VERSION "dbc-export 1 2025.20.8"

NS_ :

BS_:

BU_: BMS CC CMP CMPD CP DAS DI DIF DIR EPBL EPBR EVSE FC GTW HCML HCMR HVP ICR PCS PM PMF PMR PTC SCCM SCM SCS SDCR TAS UMC VC VCFRONT VCLEFT VCRIGHT VCSEC

BO_ 1012 LS_lightShow: 8 GTW
 SG_ LS_lightShowIndex M : 0|5@1+ (1,0) [0|31] "" Vector__XXX
 SG_ LS_lightLeftRampedChannel1Reques m0 : 5|1@1+ (1,0) [0|1] "" Vector__XXX
 SG_ LS_lightLeftRampedChannel1Durati m0 : 6|2@1+ (1,0) [0|3] "" Vector__XXX
 SG_ LS_lightLeftRampedChannel2Reques m0 : 8|1@1+ (1,0) [0|1] "" Vector__XXX
 SG_ LS_lightLeftRampedChannel2Durati m0 : 9|2@1+ (1,0) [0|3] "" Vector__XXX
 SG_ LS_lightLeftRampedChannel3Reques m0 : 11|1@1+ (1,0) [0|1] "" Vector__XXX
 SG_ LS_lightLeftRampedChannel3Durati m0 : 12|2@1+ (1,0) [0|3] "" Vector__XXX
 SG_ LS_lightLeftRampedChannel4Reques m0 : 14|1@1+ (1,0) [0|1] "" Vector__XXX
 SG_ LS_lightLeftRampedChannel4Durati m0 : 16|2@1+ (1,0) [0|3] "" Vector__XXX
 SG_ LS_lightLeftRampedChannel5Reques m0 : 18|1@1+ (1,0) [0|1] "" Vector__XXX
 SG_ LS_lightLeftRampedChannel5Durati m0 : 19|2@1+ (1,0) [0|3] "" Vector__XXX
 SG_ LS_lightLeftRampedChannel6Reques m0 : 21|1@1+ (1,0) [0|1] "" Vector__XXX
 SG_ LS_lightLeftRampedChannel6Durati m0 : 22|2@1+ (1,0) [0|3] "" Vector__XXX
 SG_ LS_lightLeftRampedChannel7Reques m0 : 24|1@1+ (1,0) [0|1] "" Vector__XXX
 SG_ LS_lightLeftRampedChannel7Durati m0 : 25|2@1+ (1,0) [0|3] "" Vector__XXX
 SG_ LS_lightRightRampedChannel1Reque m0 : 27|1@1+ (1,0) [0|1] "" Vector__XXX
 SG_ LS_lightRightRampedChannel1Durat m0 : 28|2@1+ (1,0) [0|3] "" Vector__XXX
 SG_ LS_lightRightRampedChannel2Reque m0 : 30|1@1+ (1,0) [0|1] "" Vector__XXX
 SG_ LS_lightRightRampedChannel2Durat m0 : 31|2@1+ (1,0) [0|3] "" Vector__XXX
 SG_ LS_lightRightRampedChannel3Reque m0 : 33|1@1+ (1,0) [0|1] "" Vector__XXX
 SG_ LS_lightRightRampedChannel3Durat m0 : 34|2@1+ (1,0) [0|3] "" Vector__XXX
 SG_ LS_lightRightRampedChannel4Reque m0 : 36|1@1+ (1,0) [0|1] "" Vector__XXX
 SG_ LS_lightRightRampedChannel4Durat m0 : 37|2@1+ (1,0) [0|3] "" Vector__XXX
 SG_ LS_lightRightRampedChannel5Reque m0 : 39|1@1+ (1,0) [0|1] "" Vector__XXX
 SG_ LS_lightRightRampedChannel5Durat m0 : 40|2@1+ (1,0) [0|3] "" Vector__XXX
 SG_ LS_lightRightRampedChannel6Reque m0 : 42|1@1+ (1,0) [0|1] "" Vector__XXX
 SG_ LS_lightRightRampedChannel6Durat m0 : 43|2@1+ (1,0) [0|3] "" Vector__XXX
 SG_ LS_lightRightRampedChannel7Reque m0 : 45|1@1+ (1,0) [0|1] "" Vector__XXX
 SG_ LS_lightRightRampedChannel7Durat m0 : 46|2@1+ (1,0) [0|3] "" Vector__XXX
 SG_ LS_lightRearTurnLeftRequest m0 : 48|1@1+ (1,0) [0|1] "" Vector__XXX
 SG_ LS_lightRearTurnRightRequest m0 : 49|1@1+ (1,0) [0|1] "" Vector__XXX
 SG_ LS_lightSideRepeaterLeftRequest m0 : 50|1@1+ (1,0) [0|1] "" Vector__XXX
 SG_ LS_lightSideRepeaterRightRequest m0 : 51|1@1+ (1,0) [0|1] "" Vector__XXX
 SG_ LS_lightSideMarkerLeftRequest m0 : 52|1@1+ (1,0) [0|1] "" Vector__XXX
 SG_ LS_lightSideMarkerRightRequest m0 : 53|1@1+ (1,0) [0|1] "" Vector__XXX
 SG_ LS_lightFrontFogLeftRequest m0 : 54|1@1+ (1,0) [0|1] "" Vector__XXX
 SG_ LS_lightFrontFogRightRequest m0 : 55|1@1+ (1,0) [0|1] "" Vector__XXX
 SG_ LS_lightRearFogRequest m0 : 56|1@1+ (1,0) [0|1] "" Vector__XXX
 SG_ LS_lightBrakeRequest m0 : 57|1@1+ (1,0) [0|1] "" Vector__XXX
 SG_ LS_lightTailLeftRequest m0 : 58|1@1+ (1,0) [0|1] "" Vector__XXX
 SG_ LS_lightTailRightRequest m0 : 59|1@1+ (1,0) [0|1] "" Vector__XXX
 SG_ LS_lightLicensePlateRequest m0 : 60|1@1+ (1,0) [0|1] "" Vector__XXX
 SG_ LS_lightReverseRequest m0 : 61|1@1+ (1,0) [0|1] "" Vector__XXX
 SG_ LS_lightAuxParkLeftRequest m0 : 62|1@1+ (1,0) [0|1] "" Vector__XXX
 SG_ LS_lightAuxParkRightRequest m0 : 63|1@1+ (1,0) [0|1] "" Vector__XXX
 SG_ LS_mirrorRequestLeft m1 : 5|3@1+ (1,0) [0|7] "" Vector__XXX
 SG_ LS_mirrorRequestRight m1 : 8|3@1+ (1,0) [0|7] "" Vector__XXX
 SG_ LS_liftgateRequest m1 : 11|3@1+ (1,0) [0|7] "" Vector__XXX
 SG_ LS_windowRequestLF m1 : 16|3@1+ (1,0) [0|7] "" Vector__XXX
 SG_ LS_windowRequestLR m1 : 19|3@1+ (1,0) [0|7] "" Vector__XXX
 SG_ LS_windowRequestRF m1 : 24|3@1+ (1,0) [0|7] "" Vector__XXX
 SG_ LS_windowRequestRR m1 : 27|3@1+ (1,0) [0|7] "" Vector__XXX
 SG_ LS_presentingHandleRequestLF m1 : 32|3@1+ (1,0) [0|7] "" Vector__XXX
 SG_ LS_presentingHandleRequestLR m1 : 35|3@1+ (1,0) [0|7] "" Vector__XXX
 SG_ LS_presentingHandleRequestRF m1 : 40|3@1+ (1,0) [0|7] "" Vector__XXX
 SG_ LS_presentingHandleRequestRR m1 : 43|3@1+ (1,0) [0|7] "" Vector__XXX
 SG_ LS_powerFrontDoorRequestLeft m1 : 46|3@1+ (1,0) [0|7] "" Vector__XXX
 SG_ LS_powerFrontDoorRequestRight m1 : 49|3@1+ (1,0) [0|7] "" Vector__XXX
 SG_ LS_falconDoorRequestLeft m1 : 52|3@1+ (1,0) [0|7] "" Vector__XXX
 SG_ LS_falconDoorRequestRight m1 : 55|3@1+ (1,0) [0|7] "" Vector__XXX
 SG_ LS_chargePortRequest m1 : 58|2@1+ (1,0) [0|2] "" Vector__XXX
 SG_ LS_chargePortRaveRequest m1 : 60|1@1+ (1,0) [0|1] "" Vector__XXX
 SG_ LS_suspensionRequest m1 : 61|2@1+ (1,0) [0|2] "" Vector__XXX
 SG_ LS_rgbIPFLRed m2 : 8|8@1+ (1,0) [0|255] "" Vector__XXX
 SG_ LS_rgbIPFLGreen m2 : 16|8@1+ (1,0) [0|255] "" Vector__XXX
 SG_ LS_rgbIPFLBlue m2 : 24|8@1+ (1,0) [0|255] "" Vector__XXX
 SG_ LS_rgbIPFRRed m2 : 32|8@1+ (1,0) [0|255] "" Vector__XXX
 SG_ LS_rgbIPFRGreen m2 : 40|8@1+ (1,0) [0|255] "" Vector__XXX
 SG_ LS_rgbIPFRBlue m2 : 48|8@1+ (1,0) [0|255] "" Vector__XXX
 SG_ LS_rgbDoorFLForeRed m3 : 8|8@1+ (1,0) [0|255] "" Vector__XXX
 SG_ LS_rgbDoorFLForeGreen m3 : 16|8@1+ (1,0) [0|255] "" Vector__XXX
 SG_ LS_rgbDoorFLForeBlue m3 : 24|8@1+ (1,0) [0|255] "" Vector__XXX
 SG_ LS_rgbDoorFLAftRed m3 : 32|8@1+ (1,0) [0|255] "" Vector__XXX
 SG_ LS_rgbDoorFLAftGreen m3 : 40|8@1+ (1,0) [0|255] "" Vector__XXX
 SG_ LS_rgbDoorFLAftBlue m3 : 48|8@1+ (1,0) [0|255] "" Vector__XXX
 SG_ LS_rgbDoorFRForeRed m4 : 8|8@1+ (1,0) [0|255] "" Vector__XXX
 SG_ LS_rgbDoorFRForeGreen m4 : 16|8@1+ (1,0) [0|255] "" Vector__XXX
 SG_ LS_rgbDoorFRForeBlue m4 : 24|8@1+ (1,0) [0|255] "" Vector__XXX
 SG_ LS_rgbDoorFRAftRed m4 : 32|8@1+ (1,0) [0|255] "" Vector__XXX
 SG_ LS_rgbDoorFRAftGreen m4 : 40|8@1+ (1,0) [0|255] "" Vector__XXX
 SG_ LS_rgbDoorFRAftBlue m4 : 48|8@1+ (1,0) [0|255] "" Vector__XXX
 SG_ LS_rgbDoorRLForeRed m5 : 8|8@1+ (1,0) [0|255] "" Vector__XXX
 SG_ LS_rgbDoorRLForeGreen m5 : 16|8@1+ (1,0) [0|255] "" Vector__XXX
 SG_ LS_rgbDoorRLForeBlue m5 : 24|8@1+ (1,0) [0|255] "" Vector__XXX
 SG_ LS_rgbDoorRLAftRed m5 : 32|8@1+ (1,0) [0|255] "" Vector__XXX
 SG_ LS_rgbDoorRLAftGreen m5 : 40|8@1+ (1,0) [0|255] "" Vector__XXX
 SG_ LS_rgbDoorRLAftBlue m5 : 48|8@1+ (1,0) [0|255] "" Vector__XXX
 SG_ LS_rgbDoorRRForeRed m6 : 8|8@1+ (1,0) [0|255] "" Vector__XXX
 SG_ LS_rgbDoorRRForeGreen m6 : 16|8@1+ (1,0) [0|255] "" Vector__XXX
 SG_ LS_rgbDoorRRForeBlue m6 : 24|8@1+ (1,0) [0|255] "" Vector__XXX
 SG_ LS_rgbDoorRRAftRed m6 : 32|8@1+ (1,0) [0|255] "" Vector__XXX
 SG_ LS_rgbDoorRRAftGreen m6 : 40|8@1+ (1,0) [0|255] "" Vector__XXX
 SG_ LS_rgbDoorRRAftBlue m6 : 48|8@1+ (1,0) [0|255] "" Vector__XXX
 SG_ LS_frontMatrix0 m7 : 8|8@1+ (1,0) [0|255] "" Vector__XXX
 SG_ LS_frontMatrix1 m7 : 16|8@1+ (1,0) [0|255] "" Vector__XXX
 SG_ LS_frontMatrix2 m7 : 24|8@1+ (1,0) [0|255] "" Vector__XXX
 SG_ LS_frontMatrix3 m7 : 32|8@1+ (1,0) [0|255] "" Vector__XXX
 SG_ LS_frontMatrix4 m7 : 40|8@1+ (1,0) [0|255] "" Vector__XXX
 SG_ LS_frontMatrix5 m7 : 48|8@1+ (1,0) [0|255] "" Vector__XXX
 SG_ LS_frontMatrix6 m7 : 56|8@1+ (1,0) [0|255] "" Vector__XXX
 SG_ LS_frontMatrix7 m8 : 8|8@1+ (1,0) [0|255] "" Vector__XXX
 SG_ LS_frontMatrix8 m8 : 16|8@1+ (1,0) [0|255] "" Vector__XXX
 SG_ LS_frontMatrix9 m8 : 24|8@1+ (1,0) [0|255] "" Vector__XXX
 SG_ LS_frontMatrix10 m8 : 32|8@1+ (1,0) [0|255] "" Vector__XXX
 SG_ LS_frontMatrix11 m8 : 40|8@1+ (1,0) [0|255] "" Vector__XXX
 SG_ LS_frontMatrix12 m8 : 48|8@1+ (1,0) [0|255] "" Vector__XXX
 SG_ LS_frontMatrix13 m8 : 56|8@1+ (1,0) [0|255] "" Vector__XXX
 SG_ LS_frontMatrix14 m9 : 8|8@1+ (1,0) [0|255] "" Vector__XXX
 SG_ LS_frontMatrix15 m9 : 16|8@1+ (1,0) [0|255] "" Vector__XXX
 SG_ LS_frontMatrix16 m9 : 24|8@1+ (1,0) [0|255] "" Vector__XXX
 SG_ LS_frontMatrix17 m9 : 32|8@1+ (1,0) [0|255] "" Vector__XXX
 SG_ LS_frontMatrix18 m9 : 40|8@1+ (1,0) [0|255] "" Vector__XXX
 SG_ LS_frontMatrix19 m9 : 48|8@1+ (1,0) [0|255] "" Vector__XXX
 SG_ LS_frontMatrix20 m9 : 56|8@1+ (1,0) [0|255] "" Vector__XXX
 SG_ LS_frontMatrix21 m10 : 8|8@1+ (1,0) [0|255] "" Vector__XXX
 SG_ LS_frontMatrix22 m10 : 16|8@1+ (1,0) [0|255] "" Vector__XXX
 SG_ LS_frontMatrix23 m10 : 24|8@1+ (1,0) [0|255] "" Vector__XXX
 SG_ LS_frontMatrix24 m10 : 32|8@1+ (1,0) [0|255] "" Vector__XXX
 SG_ LS_frontMatrix25 m10 : 40|8@1+ (1,0) [0|255] "" Vector__XXX
 SG_ LS_frontMatrix26 m10 : 48|8@1+ (1,0) [0|255] "" Vector__XXX
 SG_ LS_frontMatrix27 m10 : 56|8@1+ (1,0) [0|255] "" Vector__XXX
 SG_ LS_frontMatrix28 m11 : 8|8@1+ (1,0) [0|255] "" Vector__XXX
 SG_ LS_frontMatrix29 m11 : 16|8@1+ (1,0) [0|255] "" Vector__XXX
 SG_ LS_frontMatrix30 m11 : 24|8@1+ (1,0) [0|255] "" Vector__XXX
 SG_ LS_frontMatrix31 m11 : 32|8@1+ (1,0) [0|255] "" Vector__XXX
 SG_ LS_frontMatrix32 m11 : 40|8@1+ (1,0) [0|255] "" Vector__XXX
 SG_ LS_frontMatrix33 m11 : 48|8@1+ (1,0) [0|255] "" Vector__XXX
 SG_ LS_frontMatrix34 m11 : 56|8@1+ (1,0) [0|255] "" Vector__XXX
 SG_ LS_frontMatrix35 m12 : 8|8@1+ (1,0) [0|255] "" Vector__XXX
 SG_ LS_frontMatrix36 m12 : 16|8@1+ (1,0) [0|255] "" Vector__XXX
 SG_ LS_frontMatrix37 m12 : 24|8@1+ (1,0) [0|255] "" Vector__XXX
 SG_ LS_frontMatrix38 m12 : 32|8@1+ (1,0) [0|255] "" Vector__XXX
 SG_ LS_frontMatrix39 m12 : 40|8@1+ (1,0) [0|255] "" Vector__XXX
 SG_ LS_frontMatrix40 m12 : 48|8@1+ (1,0) [0|255] "" Vector__XXX
 SG_ LS_frontMatrix41 m12 : 56|8@1+ (1,0) [0|255] "" Vector__XXX
 SG_ LS_frontMatrix42 m13 : 8|8@1+ (1,0) [0|255] "" Vector__XXX
 SG_ LS_frontMatrix43 m13 : 16|8@1+ (1,0) [0|255] "" Vector__XXX
 SG_ LS_frontMatrix44 m13 : 24|8@1+ (1,0) [0|255] "" Vector__XXX
 SG_ LS_frontMatrix45 m13 : 32|8@1+ (1,0) [0|255] "" Vector__XXX
 SG_ LS_frontMatrix46 m13 : 40|8@1+ (1,0) [0|255] "" Vector__XXX
 SG_ LS_frontMatrix47 m13 : 48|8@1+ (1,0) [0|255] "" Vector__XXX
 SG_ LS_frontMatrix48 m13 : 56|8@1+ (1,0) [0|255] "" Vector__XXX
 SG_ LS_frontMatrix49 m14 : 8|8@1+ (1,0) [0|255] "" Vector__XXX
 SG_ LS_frontMatrix50 m14 : 16|8@1+ (1,0) [0|255] "" Vector__XXX
 SG_ LS_frontMatrix51 m14 : 24|8@1+ (1,0) [0|255] "" Vector__XXX
 SG_ LS_frontMatrix52 m14 : 32|8@1+ (1,0) [0|255] "" Vector__XXX
 SG_ LS_frontMatrix53 m14 : 40|8@1+ (1,0) [0|255] "" Vector__XXX
 SG_ LS_frontMatrix54 m14 : 48|8@1+ (1,0) [0|255] "" Vector__XXX
 SG_ LS_frontMatrix55 m14 : 56|8@1+ (1,0) [0|255] "" Vector__XXX
 SG_ LS_frontMatrix56 m15 : 8|8@1+ (1,0) [0|255] "" Vector__XXX
 SG_ LS_frontMatrix57 m15 : 16|8@1+ (1,0) [0|255] "" Vector__XXX
 SG_ LS_frontMatrix58 m15 : 24|8@1+ (1,0) [0|255] "" Vector__XXX
 SG_ LS_frontMatrix59 m15 : 32|8@1+ (1,0) [0|255] "" Vector__XXX
 SG_ LS_rearMatrix0 m15 : 40|8@1+ (1,0) [0|255] "" Vector__XXX
 SG_ LS_rearMatrix1 m15 : 48|8@1+ (1,0) [0|255] "" Vector__XXX
 SG_ LS_rearMatrix2 m15 : 56|8@1+ (1,0) [0|255] "" Vector__XXX
 SG_ LS_rearMatrix3 m16 : 8|8@1+ (1,0) [0|255] "" Vector__XXX
 SG_ LS_rearMatrix4 m16 : 16|8@1+ (1,0) [0|255] "" Vector__XXX
 SG_ LS_rearMatrix5 m16 : 24|8@1+ (1,0) [0|255] "" Vector__XXX
 SG_ LS_rearMatrix6 m16 : 32|8@1+ (1,0) [0|255] "" Vector__XXX
 SG_ LS_rearMatrix7 m16 : 40|8@1+ (1,0) [0|255] "" Vector__XXX
 SG_ LS_rearMatrix8 m16 : 48|8@1+ (1,0) [0|255] "" Vector__XXX
 SG_ LS_rearMatrix9 m16 : 56|8@1+ (1,0) [0|255] "" Vector__XXX
 SG_ LS_rearMatrix10 m17 : 8|8@1+ (1,0) [0|255] "" Vector__XXX
 SG_ LS_rearMatrix11 m17 : 16|8@1+ (1,0) [0|255] "" Vector__XXX
 SG_ LS_rearMatrix12 m17 : 24|8@1+ (1,0) [0|255] "" Vector__XXX
 SG_ LS_rearMatrix13 m17 : 32|8@1+ (1,0) [0|255] "" Vector__XXX
 SG_ LS_rearMatrix14 m17 : 40|8@1+ (1,0) [0|255] "" Vector__XXX
 SG_ LS_rearMatrix15 m17 : 48|8@1+ (1,0) [0|255] "" Vector__XXX
 SG_ LS_rearMatrix16 m17 : 56|8@1+ (1,0) [0|255] "" Vector__XXX
 SG_ LS_rearMatrix17 m18 : 8|8@1+ (1,0) [0|255] "" Vector__XXX
 SG_ LS_rearMatrix18 m18 : 16|8@1+ (1,0) [0|255] "" Vector__XXX
 SG_ LS_rearMatrix19 m18 : 24|8@1+ (1,0) [0|255] "" Vector__XXX
 SG_ LS_rearMatrix20 m18 : 32|8@1+ (1,0) [0|255] "" Vector__XXX
 SG_ LS_rearMatrix21 m18 : 40|8@1+ (1,0) [0|255] "" Vector__XXX
 SG_ LS_rearMatrix22 m18 : 48|8@1+ (1,0) [0|255] "" Vector__XXX
 SG_ LS_rearMatrix23 m18 : 56|8@1+ (1,0) [0|255] "" Vector__XXX
 SG_ LS_rearMatrix24 m19 : 8|8@1+ (1,0) [0|255] "" Vector__XXX
 SG_ LS_rearMatrix25 m19 : 16|8@1+ (1,0) [0|255] "" Vector__XXX
 SG_ LS_rearMatrix26 m19 : 24|8@1+ (1,0) [0|255] "" Vector__XXX
 SG_ LS_rearMatrix27 m19 : 32|8@1+ (1,0) [0|255] "" Vector__XXX
 SG_ LS_rearMatrix28 m19 : 40|8@1+ (1,0) [0|255] "" Vector__XXX
 SG_ LS_rearMatrix29 m19 : 48|8@1+ (1,0) [0|255] "" Vector__XXX
 SG_ LS_rearMatrix30 m19 : 56|8@1+ (1,0) [0|255] "" Vector__XXX
 SG_ LS_rearMatrix31 m20 : 8|8@1+ (1,0) [0|255] "" Vector__XXX
 SG_ LS_rearMatrix32 m20 : 16|8@1+ (1,0) [0|255] "" Vector__XXX
 SG_ LS_rearMatrix33 m20 : 24|8@1+ (1,0) [0|255] "" Vector__XXX
 SG_ LS_rearMatrix34 m20 : 32|8@1+ (1,0) [0|255] "" Vector__XXX
 SG_ LS_rearMatrix35 m20 : 40|8@1+ (1,0) [0|255] "" Vector__XXX
 SG_ LS_rearMatrix36 m20 : 48|8@1+ (1,0) [0|255] "" Vector__XXX
 SG_ LS_rearMatrix37 m20 : 56|8@1+ (1,0) [0|255] "" Vector__XXX
 SG_ LS_rearMatrix38 m21 : 8|8@1+ (1,0) [0|255] "" Vector__XXX
 SG_ LS_rearMatrix39 m21 : 16|8@1+ (1,0) [0|255] "" Vector__XXX
 SG_ LS_rearMatrix40 m21 : 24|8@1+ (1,0) [0|255] "" Vector__XXX
 SG_ LS_rearMatrix41 m21 : 32|8@1+ (1,0) [0|255] "" Vector__XXX
 SG_ LS_rearMatrix42 m21 : 40|8@1+ (1,0) [0|255] "" Vector__XXX
 SG_ LS_rearMatrix43 m21 : 48|8@1+ (1,0) [0|255] "" Vector__XXX
 SG_ LS_rearMatrix44 m21 : 56|8@1+ (1,0) [0|255] "" Vector__XXX
 SG_ LS_rearMatrix45 m22 : 8|8@1+ (1,0) [0|255] "" Vector__XXX
 SG_ LS_rearMatrix46 m22 : 16|8@1+ (1,0) [0|255] "" Vector__XXX
 SG_ LS_rearMatrix47 m22 : 24|8@1+ (1,0) [0|255] "" Vector__XXX
 SG_ LS_rearMatrix48 m22 : 32|8@1+ (1,0) [0|255] "" Vector__XXX
 SG_ LS_rearMatrix49 m22 : 40|8@1+ (1,0) [0|255] "" Vector__XXX
 SG_ LS_rearMatrix50 m22 : 48|8@1+ (1,0) [0|255] "" Vector__XXX
 SG_ LS_rearMatrix51 m22 : 56|8@1+ (1,0) [0|255] "" Vector__XXX
 SG_ LS_rearMatrix52 m23 : 8|8@1+ (1,0) [0|255] "" Vector__XXX
 SG_ LS_rearMatrix53 m23 : 16|8@1+ (1,0) [0|255] "" Vector__XXX
 SG_ LS_rearMatrix54 m23 : 24|8@1+ (1,0) [0|255] "" Vector__XXX
 SG_ LS_rearMatrix55 m23 : 32|8@1+ (1,0) [0|255] "" Vector__XXX
 SG_ LS_rearMatrix56 m23 : 40|8@1+ (1,0) [0|255] "" Vector__XXX
 SG_ LS_rearMatrix57 m23 : 48|8@1+ (1,0) [0|255] "" Vector__XXX
 SG_ LS_rearMatrix58 m23 : 56|8@1+ (1,0) [0|255] "" Vector__XXX
 SG_ LS_rearMatrix59 m24 : 8|8@1+ (1,0) [0|255] "" Vector__XXX
 SG_ LS_offroadLightBar0 m24 : 16|8@1+ (1,0) [0|255] "" Vector__XXX
 SG_ LS_offroadLightBar1 m24 : 24|8@1+ (1,0) [0|255] "" Vector__XXX
 SG_ LS_offroadLightBar2 m24 : 32|8@1+ (1,0) [0|255] "" Vector__XXX
 SG_ LS_offroadLightBar3 m24 : 40|8@1+ (1,0) [0|255] "" Vector__XXX
 SG_ LS_offroadLightBar4 m24 : 48|8@1+ (1,0) [0|255] "" Vector__XXX
 SG_ LS_offroadLightBar5 m24 : 56|8@1+ (1,0) [0|255] "" Vector__XXX

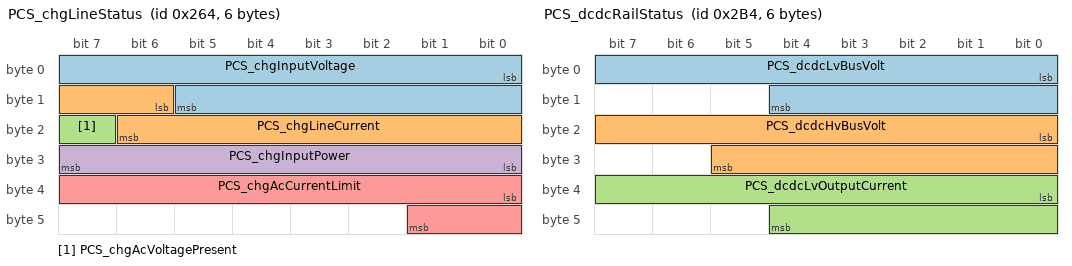
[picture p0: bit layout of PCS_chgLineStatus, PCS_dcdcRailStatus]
BO_ 612 PCS_chgLineStatus: 6 PCS
 SG_ PCS_chgInputVoltage : 0|14@1+ (0.033,0) [0|540.639] "V" Vector__XXX
 SG_ PCS_chgLineCurrent : 14|9@1+ (0.1,0) [0|50] "A" Vector__XXX
 SG_ PCS_chgAcVoltagePresent : 23|1@1+ (1,0) [0|1] "" Vector__XXX
 SG_ PCS_chgInputPower : 24|8@1+ (0.1,0) [0|20] "kW" Vector__XXX
 SG_ PCS_chgAcCurrentLimit : 32|10@1+ (0.1,0) [0|102.3] "A" Vector__XXX

BO_ 692 PCS_dcdcRailStatus: 6 PCS
 SG_ PCS_dcdcLvBusVolt : 0|13@1+ (0.01,0) [0|80] "V" Vector__XXX
 SG_ PCS_dcdcHvBusVolt : 16|14@1+ (0.1,0) [0|1600] "V" Vector__XXX
 SG_ PCS_dcdcLvOutputCurrent : 32|13@1- (0.1,0) [-400|400] "A" Vector__XXX

BO_ 964 PCS_info: 8 PCS
 SG_ PCS_infoIndex M : 0|8@1+ (1,0) [0|255] "" Vector__XXX
 SG_ PCS_buildType m10 : 8|8@1+ (1,0) [0|255] "" Vector__XXX
 SG_ PCS_buildConfigId m10 : 16|16@1+ (1,0) [0|65535] "" Vector__XXX
 SG_ PCS_hardwareId m10 : 32|16@1+ (1,0) [0|65535] "" Vector__XXX
 SG_ PCS_componentId m10 : 48|16@1+ (1,0) [0|65535] "" Vector__XXX
 SG_ PCS_pcbaId m11 : 16|8@1+ (1,0) [0|255] "" Vector__XXX
 SG_ PCS_assemblyId m11 : 24|8@1+ (1,0) [0|255] "" Vector__XXX
 SG_ PCS_usageId m11 : 32|16@1+ (1,0) [0|65535] "" Vector__XXX
 SG_ PCS_subUsageId m11 : 48|16@1+ (1,0) [0|65535] "" Vector__XXX
 SG_ PCS_platformType m13 : 8|8@1+ (1,0) [0|255] "" Vector__XXX
 SG_ PCS_appCrc m13 : 32|32@1+ (1,0) [0|4294967295] "" Vector__XXX
 SG_ PCS_cpu2AppCrc m16 : 32|32@1+ (1,0) [0|4294967295] "" Vector__XXX
 SG_ PCS_appGitHash m17 : 8|56@1+ (1,0) [0|7.20575940379e+16] "" Vector__XXX
 SG_ PCS_bootGitHash m18 : 8|56@1+ (1,0) [0|7.20575940379e+16] "" Vector__XXX
 SG_ PCS_bootUdsProtoVersion m20 : 8|8@1+ (1,0) [0|255] "" Vector__XXX
 SG_ PCS_bootCrc m20 : 32|32@1+ (1,0) [0|4294967295] "" Vector__XXX

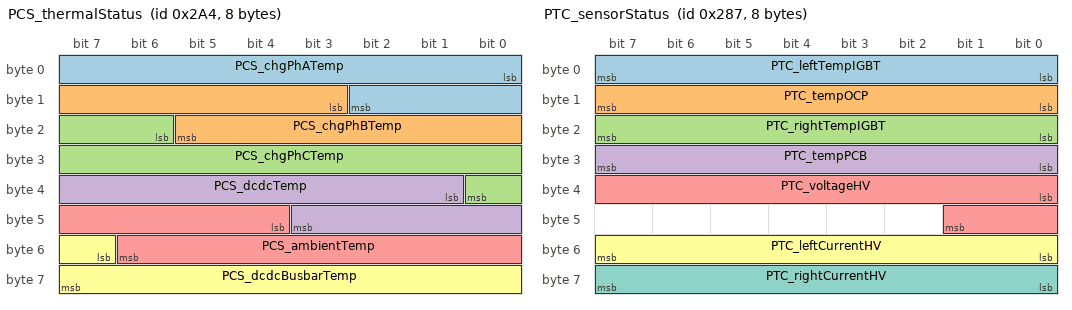
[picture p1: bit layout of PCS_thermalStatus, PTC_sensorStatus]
BO_ 676 PCS_thermalStatus: 8 PCS
 SG_ PCS_chgPhATemp : 0|11@1- (0.1,40) [-62.4|142.3] "C" Vector__XXX
 SG_ PCS_chgPhBTemp : 11|11@1- (0.1,40) [-62.4|142.3] "C" Vector__XXX
 SG_ PCS_chgPhCTemp : 22|11@1- (0.1,40) [-62.4|142.3] "C" Vector__XXX
 SG_ PCS_dcdcTemp : 33|11@1- (0.1,40) [-62.4|142.3] "C" Vector__XXX
 SG_ PCS_ambientTemp : 44|11@1- (0.1,40) [-62.4|142.3] "C" Vector__XXX
 SG_ PCS_dcdcBusbarTemp : 55|9@1+ (0.2935421,0) [0|149.706471] "C" Vector__XXX

BO_ 790 PMF_info: 8 PMF
 SG_ PMF_infoIndex M : 0|8@1+ (1,0) [0|255] "" Vector__XXX
 SG_ PMF_buildType m10 : 8|8@1+ (1,0) [0|255] "" Vector__XXX
 SG_ PMF_buildConfigurationId m10 : 16|16@1+ (1,0) [0|65535] "" Vector__XXX
 SG_ PMF_hardwareId m10 : 32|8@1+ (1,0) [0|252] "" Vector__XXX
 SG_ PMF_deviceFused m10 : 40|1@1+ (1,0) [0|1] "" Vector__XXX
 SG_ PMF_componentId m10 : 48|16@1+ (1,0) [0|65535] "" Vector__XXX
 SG_ PMF_pcbaId m11 : 16|8@1+ (1,0) [0|255] "" Vector__XXX
 SG_ PMF_assemblyId m11 : 24|8@1+ (1,0) [0|255] "" Vector__XXX
 SG_ PMF_usageId m11 : 32|16@1+ (1,0) [0|65535] "" Vector__XXX
 SG_ PMF_subUsageId m11 : 48|16@1+ (1,0) [0|65535] "" Vector__XXX
 SG_ PMF_applicationCrc m13 : 32|32@1+ (1,0) [0|4294967295] "" Vector__XXX
 SG_ PMF_appGitHash m17 : 8|56@1+ (1,0) [0|7.20575940379e+16] "" Vector__XXX
 SG_ PMF_bootGitHash m18 : 8|56@1+ (1,0) [0|7.20575940379e+16] "" Vector__XXX
 SG_ PMF_platformTyp m19 : 8|8@1+ (1,0) [0|255] "" Vector__XXX
 SG_ PMF_udsProtocolVersion m20 : 8|8@1+ (1,0) [0|255] "" Vector__XXX
 SG_ PMF_bootloaderCrc m20 : 32|32@1+ (1,0) [0|4294967295] "" Vector__XXX

BO_ 1748 PMR_info: 8 PMR
 SG_ PMR_infoIndex M : 0|8@1+ (1,0) [0|255] "" Vector__XXX
 SG_ PMR_buildType m10 : 8|8@1+ (1,0) [0|255] "" Vector__XXX
 SG_ PMR_buildConfigurationId m10 : 16|16@1+ (1,0) [0|65535] "" Vector__XXX
 SG_ PMR_hardwareId m10 : 32|8@1+ (1,0) [0|252] "" Vector__XXX
 SG_ PMR_deviceFused m10 : 40|1@1+ (1,0) [0|1] "" Vector__XXX
 SG_ PMR_componentId m10 : 48|16@1+ (1,0) [0|65535] "" Vector__XXX
 SG_ PMR_pcbaId m11 : 16|8@1+ (1,0) [0|255] "" Vector__XXX
 SG_ PMR_assemblyId m11 : 24|8@1+ (1,0) [0|255] "" Vector__XXX
 SG_ PMR_usageId m11 : 32|16@1+ (1,0) [0|65535] "" Vector__XXX
 SG_ PMR_subUsageId m11 : 48|16@1+ (1,0) [0|65535] "" Vector__XXX
 SG_ PMR_applicationCrc m13 : 32|32@1+ (1,0) [0|4294967295] "" Vector__XXX
 SG_ PMR_appGitHash m17 : 8|56@1+ (1,0) [0|7.20575940379e+16] "" Vector__XXX
 SG_ PMR_bootGitHash m18 : 8|56@1+ (1,0) [0|7.20575940379e+16] "" Vector__XXX
 SG_ PMR_platformTyp m19 : 8|8@1+ (1,0) [0|255] "" Vector__XXX
 SG_ PMR_udsProtocolVersion m20 : 8|8@1+ (1,0) [0|255] "" Vector__XXX
 SG_ PMR_bootloaderCrc m20 : 32|32@1+ (1,0) [0|4294967295] "" Vector__XXX

BO_ 1551 PM_info: 8 PM
 SG_ PM_infoIndex M : 0|8@1+ (1,0) [0|255] "" Vector__XXX
 SG_ PM_buildType m10 : 8|8@1+ (1,0) [0|255] "" Vector__XXX
 SG_ PM_buildConfigurationId m10 : 16|16@1+ (1,0) [0|65535] "" Vector__XXX
 SG_ PM_hardwareId m10 : 32|8@1+ (1,0) [0|252] "" Vector__XXX
 SG_ PM_deviceFused m10 : 40|1@1+ (1,0) [0|1] "" Vector__XXX
 SG_ PM_componentId m10 : 48|16@1+ (1,0) [0|65535] "" Vector__XXX
 SG_ PM_pcbaId m11 : 16|8@1+ (1,0) [0|255] "" Vector__XXX
 SG_ PM_assemblyId m11 : 24|8@1+ (1,0) [0|255] "" Vector__XXX
 SG_ PM_usageId m11 : 32|16@1+ (1,0) [0|65535] "" Vector__XXX
 SG_ PM_subUsageId m11 : 48|16@1+ (1,0) [0|65535] "" Vector__XXX
 SG_ PM_applicationCrc m13 : 32|32@1+ (1,0) [0|4294967295] "" Vector__XXX
 SG_ PM_bootGitHash m18 : 8|56@1+ (1,0) [0|7.20575940379e+16] "" Vector__XXX

BO_ 1766 PNCD_IsoTpPipeToCp: 8 GTW
 SG_ PNCD_isoTpToCpData : 0|64@1+ (1,0) [0|1.84467440737e+19] "" Vector__XXX

BO_ 837 PTC_info: 8 PTC
 SG_ PTC_infoIndex M : 0|8@1+ (1,0) [0|255] "" Vector__XXX
 SG_ PTC_infoBuildType m10 : 8|3@1+ (1,0) [0|7] "" Vector__XXX
 SG_ PTC_infoBuildConfigId m10 : 16|16@1+ (1,0) [0|65535] "" Vector__XXX
 SG_ PTC_infoHardwareId m10 : 32|16@1+ (1,0) [0|65535] "" Vector__XXX
 SG_ PTC_infoComponentId m10 : 48|16@1+ (1,0) [0|65535] "" Vector__XXX
 SG_ PTC_infoPcbaId m11 : 16|8@1+ (1,0) [0|255] "" Vector__XXX
 SG_ PTC_infoAssemblyId m11 : 24|8@1+ (1,0) [0|254] "" Vector__XXX
 SG_ PTC_infoUsageId m11 : 32|16@1+ (1,0) [0|65535] "" Vector__XXX
 SG_ PTC_infoSubUsageId m11 : 48|16@1+ (1,0) [0|65535] "" Vector__XXX
 SG_ PTC_infoPlatformType m13 : 8|8@1+ (1,0) [0|255] "" Vector__XXX
 SG_ PTC_infoAppCrc m13 : 32|32@1+ (1,0) [0|4294967295] "" Vector__XXX
 SG_ PTC_infoBootUdsProtoVersion m20 : 8|8@1+ (1,0) [0|255] "" Vector__XXX
 SG_ PTC_infoBootCrc m20 : 32|32@1+ (1,0) [0|4294967295] "" Vector__XXX

BO_ 647 PTC_sensorStatus: 8 PTC
 SG_ PTC_leftTempIGBT : 0|8@1+ (1,-40) [-40|200] "degC" Vector__XXX
 SG_ PTC_tempOCP : 8|8@1+ (1,-40) [-40|200] "degC" Vector__XXX
 SG_ PTC_rightTempIGBT : 16|8@1+ (1,-40) [-40|200] "degC" Vector__XXX
 SG_ PTC_tempPCB : 24|8@1+ (1,-40) [-40|200] "degC" Vector__XXX
 SG_ PTC_voltageHV : 32|10@1+ (0.5,0) [0|511.5] "V" Vector__XXX
 SG_ PTC_leftCurrentHV : 48|8@1+ (0.2,0) [0|50] "A" Vector__XXX
 SG_ PTC_rightCurrentHV : 56|8@1+ (0.2,0) [0|50] "A" Vector__XXX

BO_ 1359 SCCM_alertMatrix: 8 SCCM
 SG_ SCCM_matrixIndex M : 0|4@1+ (1,0) [0|15] "" Vector__XXX
 SG_ SCCM_a001_CANBusOff m0 : 4|1@1+ (1,0) [0|1] "" Vector__XXX
 SG_ SCCM_a002_CANTOut m0 : 5|1@1+ (1,0) [0|1] "" Vector__XXX
 SG_ SCCM_a003_highBeamOpen m0 : 6|1@1+ (1,0) [0|1] "" Vector__XXX
 SG_ SCCM_a004_highBeamShortToGND m0 : 7|1@1+ (1,0) [0|1] "" Vector__XXX
 SG_ SCCM_a005_tipWipeOpen m0 : 8|1@1+ (1,0) [0|1] "" Vector__XXX
 SG_ SCCM_a006_tipWipeShortToGND m0 : 9|1@1+ (1,0) [0|1] "" Vector__XXX
 SG_ SCCM_a007_turnIndComInfo m0 : 10|1@1+ (1,0) [0|1] "" Vector__XXX
 SG_ SCCM_a008_turnIndInvalidTrans m0 : 11|1@1+ (1,0) [0|1] "" Vector__XXX
 SG_ SCCM_a009_turnIndOpen m0 : 12|1@1+ (1,0) [0|1] "" Vector__XXX
 SG_ SCCM_a010_turnIndShortToGnd m0 : 13|1@1+ (1,0) [0|1] "" Vector__XXX
 SG_ SCCM_a011_turnIndHWErr m0 : 14|1@1+ (1,0) [0|1] "" Vector__XXX
 SG_ SCCM_a012_turnGenErr m0 : 15|1@1+ (1,0) [0|1] "" Vector__XXX
 SG_ SCCM_a013_voltageHigh m0 : 16|1@1+ (1,0) [0|1] "" Vector__XXX
 SG_ SCCM_a014_voltageLow m0 : 17|1@1+ (1,0) [0|1] "" Vector__XXX
 SG_ SCCM_a015_softwareError m0 : 18|1@1+ (1,0) [0|1] "" Vector__XXX
 SG_ SCCM_a016_hardwareError m0 : 19|1@1+ (1,0) [0|1] "" Vector__XXX
 SG_ SCCM_a017_memoryError m0 : 20|1@1+ (1,0) [0|1] "" Vector__XXX
 SG_ SCCM_a018_angleSpeedOutOfRange m0 : 21|1@1+ (1,0) [0|1] "" Vector__XXX
 SG_ SCCM_a019_angleOutOfRange m0 : 22|1@1+ (1,0) [0|1] "" Vector__XXX
 SG_ SCCM_a020_angleInternalError m0 : 23|1@1+ (1,0) [0|1] "" Vector__XXX
 SG_ SCCM_a021_gearStalkSignalInvalid m0 : 24|1@1+ (1,0) [0|1] "" Vector__XXX
 SG_ SCCM_a022_gearStalkOpenCircuit m0 : 25|1@1+ (1,0) [0|1] "" Vector__XXX
 SG_ SCCM_a023_gearStalkShortCircuit m0 : 26|1@1+ (1,0) [0|1] "" Vector__XXX
 SG_ SCCM_a024_gearStalkGenErr m0 : 27|1@1+ (1,0) [0|1] "" Vector__XXX
 SG_ SCCM_a025_runTimeError m0 : 28|1@1+ (1,0) [0|1] "" Vector__XXX
 SG_ SCCM_a026_parkButtonInvalidSigna m0 : 29|1@1+ (1,0) [0|1] "" Vector__XXX
 SG_ SCCM_a027_parkButtonOpenCircuit m0 : 30|1@1+ (1,0) [0|1] "" Vector__XXX
 SG_ SCCM_a028_parkButtonShortToGroun m0 : 31|1@1+ (1,0) [0|1] "" Vector__XXX
 SG_ SCCM_a029_parkButtonMalfunction m0 : 32|1@1+ (1,0) [0|1] "" Vector__XXX
 SG_ SCCM_a061_voltageHigh_2 m1 : 4|1@1+ (1,0) [0|1] "" Vector__XXX
 SG_ SCCM_a062_voltageLow_2 m1 : 5|1@1+ (1,0) [0|1] "" Vector__XXX
 SG_ SCCM_a063_angleOutOfRange_2 m1 : 6|1@1+ (1,0) [0|1] "" Vector__XXX
 SG_ SCCM_a064_angleSpeedOutOfRange_2 m1 : 7|1@1+ (1,0) [0|1] "" Vector__XXX
 SG_ SCCM_a065_angleNotPlausible m1 : 8|1@1+ (1,0) [0|1] "" Vector__XXX
 SG_ SCCM_a066_angleSpeedNotPlausible m1 : 9|1@1+ (1,0) [0|1] "" Vector__XXX
 SG_ SCCM_a067_CANBusOff_2 m1 : 10|1@1+ (1,0) [0|1] "" Vector__XXX
 SG_ SCCM_a068_CANLVPowerState_LOC m1 : 11|1@1+ (1,0) [0|1] "" Vector__XXX
 SG_ SCCM_a069_calibrationMismatch m1 : 12|1@1+ (1,0) [0|1] "" Vector__XXX
 SG_ SCCM_a070_angleTrimMismatch m1 : 13|1@1+ (1,0) [0|1] "" Vector__XXX
 SG_ SCCM_a071_angleHallSensorError m1 : 14|1@1+ (1,0) [0|1] "" Vector__XXX
 SG_ SCCM_a072_spiBitErrors m1 : 15|1@1+ (1,0) [0|1] "" Vector__XXX
 SG_ SCCM_a073_watchdogReset m1 : 16|1@1+ (1,0) [0|1] "" Vector__XXX
 SG_ SCCM_a074_PLLLossOfLock m1 : 17|1@1+ (1,0) [0|1] "" Vector__XXX
 SG_ SCCM_a075_hardwareError_2 m1 : 18|1@1+ (1,0) [0|1] "" Vector__XXX
 SG_ SCCM_a076_memoryError_2 m1 : 19|1@1+ (1,0) [0|1] "" Vector__XXX
 SG_ SCCM_a077_gearAngleNotPlausible m1 : 20|1@1+ (1,0) [0|1] "" Vector__XXX
 SG_ SCCM_a078_ADCCalibrationError m1 : 21|1@1+ (1,0) [0|1] "" Vector__XXX
 SG_ SCCM_a079_chipTempOutOfRange m1 : 22|1@1+ (1,0) [0|1] "" Vector__XXX
 SG_ SCCM_a080_ADCSelfTestFailed m1 : 23|1@1+ (1,0) [0|1] "" Vector__XXX
 SG_ SCCM_a081_startupTestFailed m1 : 24|1@1+ (1,0) [0|1] "" Vector__XXX
 SG_ SCCM_a082_runtimeTestFailed m1 : 25|1@1+ (1,0) [0|1] "" Vector__XXX
 SG_ SCCM_a121_turnIndicatorAngleInva m2 : 4|1@1+ (1,0) [0|1] "" Vector__XXX
 SG_ SCCM_a122_turnIndicatorSpeedInva m2 : 5|1@1+ (1,0) [0|1] "" Vector__XXX
 SG_ SCCM_a123_turnIndicatorStuckActi m2 : 6|1@1+ (1,0) [0|1] "" Vector__XXX
 SG_ SCCM_a124_turnIndicatorIdleInval m2 : 7|1@1+ (1,0) [0|1] "" Vector__XXX
 SG_ SCCM_a125_turnIndicatorHallAngle m2 : 8|1@1+ (1,0) [0|1] "" Vector__XXX
 SG_ SCCM_a126_turnIndicatorHallMagOu m2 : 9|1@1+ (1,0) [0|1] "" Vector__XXX

BO_ 816 SCCM_info: 8 SCCM
 SG_ SCCM_infoIndex M : 0|8@1+ (1,0) [0|255] "" Vector__XXX
 SG_ SCCM_infoBuildType m10 : 8|8@1+ (1,0) [0|255] "" Vector__XXX
 SG_ SCCM_infoBuildConfigId m10 : 16|16@1+ (1,0) [0|65535] "" Vector__XXX
 SG_ SCCM_infoHardwareId m10 : 32|16@1+ (1,0) [0|65535] "" Vector__XXX
 SG_ SCCM_infoComponentId m10 : 48|16@1+ (1,0) [0|65535] "" Vector__XXX
 SG_ SCCM_infoPcbaId m11 : 16|8@1+ (1,0) [0|255] "" Vector__XXX
 SG_ SCCM_infoAssemblyId m11 : 24|8@1+ (1,0) [0|255] "" Vector__XXX
 SG_ SCCM_infoUsageId m11 : 32|16@1+ (1,0) [0|65535] "" Vector__XXX
 SG_ SCCM_infoSubUsageId m11 : 48|16@1+ (1,0) [0|65535] "" Vector__XXX
 SG_ SCCM_infoPlatformType m13 : 8|8@1+ (1,0) [0|255] "" Vector__XXX
 SG_ SCCM_infoAppCrc m13 : 39|32@0+ (1,0) [0|4294967295] "" Vector__XXX
 SG_ SCCM_infoBootSvnRev m14 : 8|24@1+ (1,0) [0|16777215] "" Vector__XXX
 SG_ SCCM_infoBootSvnUrlHash m14 : 32|32@1+ (1,0) [0|4294967295] "" Vector__XXX
 SG_ SCCM_infoSubcomponent1Version m16 : 16|32@1+ (1,0) [0|4294967295] "" Vector__XXX
 SG_ SCCM_infoAppSvnHash m17 : 8|56@1+ (1,0) [0|7.20575940379e+16] "" Vector__XXX
 SG_ SCCM_infoBootSvnHash m18 : 8|56@1+ (1,0) [0|7.20575940379e+16] "" Vector__XXX
 SG_ SCCM_infoUdsProtoVersion m20 : 8|8@1+ (1,0) [0|255] "" Vector__XXX
 SG_ SCCM_infoBootCrc m20 : 32|32@1+ (1,0) [0|4294967295] "" Vector__XXX

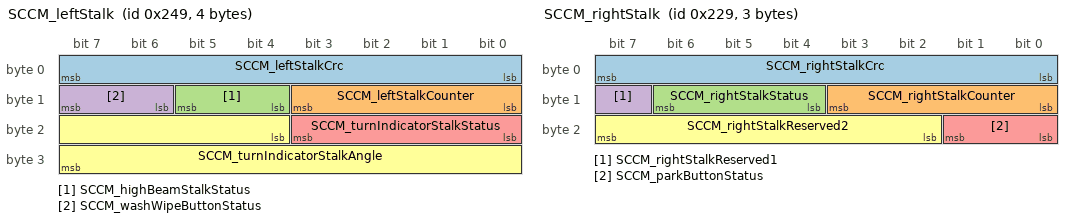
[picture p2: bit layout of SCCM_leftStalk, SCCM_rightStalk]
BO_ 585 SCCM_leftStalk: 4 SCCM
 SG_ SCCM_leftStalkCrc : 0|8@1+ (1,0) [0|255] "" Vector__XXX
 SG_ SCCM_leftStalkCounter : 8|4@1+ (1,0) [0|15] "" Vector__XXX
 SG_ SCCM_highBeamStalkStatus : 12|2@1+ (1,0) [0|2] "" Vector__XXX
 SG_ SCCM_washWipeButtonStatus : 14|2@1+ (1,0) [0|2] "" Vector__XXX
 SG_ SCCM_turnIndicatorStalkStatus : 16|4@1+ (1,0) [0|15] "" Vector__XXX
 SG_ SCCM_turnIndicatorStalkAngle : 20|12@1+ (0.1,-180) [-180|180] "deg" Vector__XXX

BO_ 553 SCCM_rightStalk: 3 SCCM
 SG_ SCCM_rightStalkCrc : 0|8@1+ (1,0) [0|255] "" Vector__XXX
 SG_ SCCM_rightStalkCounter : 8|4@1+ (1,0) [0|15] "" Vector__XXX
 SG_ SCCM_rightStalkStatus : 12|3@1+ (1,0) [0|7] "" Vector__XXX
 SG_ SCCM_rightStalkReserved1 : 15|1@1+ (1,0) [0|1] "" Vector__XXX
 SG_ SCCM_parkButtonStatus : 16|2@1+ (1,0) [0|2] "" Vector__XXX
 SG_ SCCM_rightStalkReserved2 : 18|6@1+ (1,0) [0|63] "" Vector__XXX

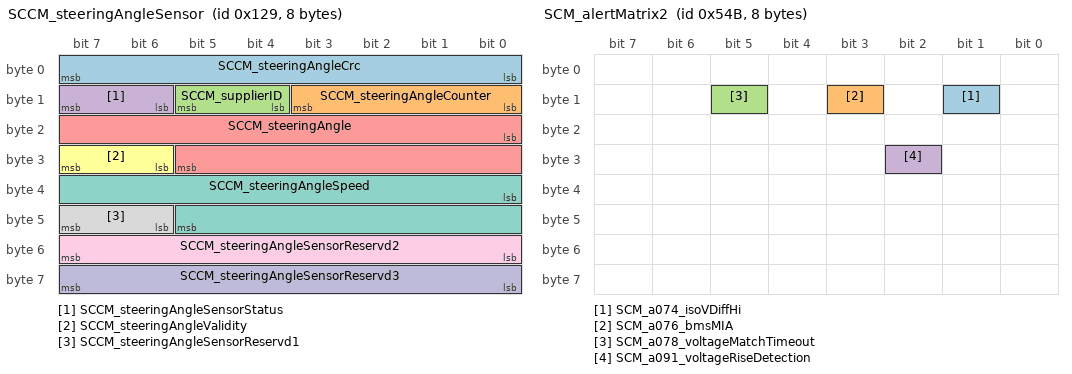
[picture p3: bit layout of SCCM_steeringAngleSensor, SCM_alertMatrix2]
BO_ 297 SCCM_steeringAngleSensor: 8 SCCM
 SG_ SCCM_steeringAngleCrc : 0|8@1+ (1,0) [0|255] "" Vector__XXX
 SG_ SCCM_steeringAngleCounter : 8|4@1+ (1,0) [0|15] "" Vector__XXX
 SG_ SCCM_supplierID : 12|2@1+ (1,0) [0|3] "" Vector__XXX
 SG_ SCCM_steeringAngleSensorStatus : 14|2@1+ (1,0) [0|3] "" Vector__XXX
 SG_ SCCM_steeringAngle : 16|14@1+ (0.1,-819.2) [-819.2|819] "deg" Vector__XXX
 SG_ SCCM_steeringAngleValidity : 30|2@1+ (1,0) [0|2] "" Vector__XXX
 SG_ SCCM_steeringAngleSpeed : 32|14@1+ (0.5,-4096) [-4096|4095.5] "deg/s" Vector__XXX
 SG_ SCCM_steeringAngleSensorReservd1 : 46|2@1+ (1,0) [0|3] "" Vector__XXX
 SG_ SCCM_steeringAngleSensorReservd2 : 48|8@1+ (1,0) [0|255] "" Vector__XXX
 SG_ SCCM_steeringAngleSensorReservd3 : 56|8@1+ (1,0) [0|255] "" Vector__XXX

BO_ 1356 SCM_alertLog: 8 SCM
 SG_ SCM_alertID M : 0|15@1+ (1,0) [0|32767] "" Vector__XXX
 SG_ SCM_alertType : 15|1@1+ (1,0) [0|1] "" Vector__XXX
 SG_ SCM_a074_voltageWithRo m74 : 16|12@1+ (1,0) [0|4095] "" Vector__XXX
 SG_ SCM_a074_voltageWithoutRo m74 : 28|12@1+ (1,0) [0|4095] "" Vector__XXX

BO_ 815 SCM_alertMatrix1: 8 SCM
 SG_ SCM_a027_externalIsolationLow : 26|1@1+ (1,0) [0|1] "" Vector__XXX
 SG_ SCM_a044_proximityRationality : 43|1@1+ (1,0) [0|1] "" Vector__XXX

BO_ 1355 SCM_alertMatrix2: 8 SCM
 SG_ SCM_a074_isoVDiffHi : 9|1@1+ (1,0) [0|1] "" Vector__XXX
 SG_ SCM_a076_bmsMIA : 11|1@1+ (1,0) [0|1] "" Vector__XXX
 SG_ SCM_a078_voltageMatchTimeout : 13|1@1+ (1,0) [0|1] "" Vector__XXX
 SG_ SCM_a091_voltageRiseDetection : 26|1@1+ (1,0) [0|1] "" Vector__XXX

BO_ 1354 SCS_alertLog: 8 SCS
 SG_ SCS_alertID M : 0|15@1+ (1,0) [0|32767] "" Vector__XXX
 SG_ SCS_alertType : 15|1@1+ (1,0) [0|1] "" Vector__XXX
 SG_ SCS_a044_proximityV m44 : 16|16@1+ (0.0001,0) [0|6.5535] "V" Vector__XXX
 SG_ SCS_a074_voltageWithRo m74 : 16|12@1+ (0.146520152688,0) [0|600.000025257] "V" Vector__XXX
 SG_ SCS_a074_voltageWithoutRo m74 : 28|12@1+ (0.146520152688,0) [0|600.000025257] "V" Vector__XXX

BO_ 869 SCS_alertMatrix1: 8 SCS
 SG_ SCS_a001_hwDSPfault : 0|1@1+ (1,0) [0|1] "" Vector__XXX
 SG_ SCS_a002_hwIbatOC : 1|1@1+ (1,0) [0|1] "" Vector__XXX
 SG_ SCS_a003_hwCordOT : 2|1@1+ (1,0) [0|1] "" Vector__XXX
 SG_ SCS_a004_hwVbusOV : 3|1@1+ (1,0) [0|1] "" Vector__XXX
 SG_ SCS_a005_hwHVIL : 4|1@1+ (1,0) [0|1] "" Vector__XXX
 SG_ SCS_a006_hwWeld_V1 : 5|1@1+ (1,0) [0|1] "" Vector__XXX
 SG_ SCS_a007_hwWeld_V2 : 6|1@1+ (1,0) [0|1] "" Vector__XXX
 SG_ SCS_a008_hwIllegalCntrShoot : 7|1@1+ (1,0) [0|1] "" Vector__XXX
 SG_ SCS_a009_hwOpen_V1 : 8|1@1+ (1,0) [0|1] "" Vector__XXX
 SG_ SCS_a010_hwOpen_V2 : 9|1@1+ (1,0) [0|1] "" Vector__XXX
 SG_ SCS_a011_hwIllegalCntrCmdV1 : 10|1@1+ (1,0) [0|1] "" Vector__XXX
 SG_ SCS_a012_hwIllegalCntrCmdV2 : 11|1@1+ (1,0) [0|1] "" Vector__XXX
 SG_ SCS_a013_cordTempHiFoldBk : 12|1@1+ (1,0) [0|1] "" Vector__XXX
 SG_ SCS_a014_coolantTempHiFoldBk : 13|1@1+ (1,0) [0|1] "" Vector__XXX
 SG_ SCS_a015_cpldRationality : 14|1@1+ (1,0) [0|1] "" Vector__XXX
 SG_ SCS_a016_unusedHW16 : 15|1@1+ (1,0) [0|1] "" Vector__XXX
 SG_ SCS_a017_unusedHW17 : 16|1@1+ (1,0) [0|1] "" Vector__XXX
 SG_ SCS_a018_unusedHW18 : 17|1@1+ (1,0) [0|1] "" Vector__XXX
 SG_ SCS_a019_unusedHW19 : 18|1@1+ (1,0) [0|1] "" Vector__XXX
 SG_ SCS_a020_unusedHW20 : 19|1@1+ (1,0) [0|1] "" Vector__XXX
 SG_ SCS_a021_unusedHW21 : 20|1@1+ (1,0) [0|1] "" Vector__XXX
 SG_ SCS_a024_emergencyShutdown : 23|1@1+ (1,0) [0|1] "" Vector__XXX
 SG_ SCS_a025_internalIsolationFault : 24|1@1+ (1,0) [0|1] "" Vector__XXX
 SG_ SCS_a026_internalIsolationLow : 25|1@1+ (1,0) [0|1] "" Vector__XXX
 SG_ SCS_a027_externalIsolationLow : 26|1@1+ (1,0) [0|1] "" Vector__XXX
 SG_ SCS_a028_isolationRationality : 27|1@1+ (1,0) [0|1] "" Vector__XXX
 SG_ SCS_a029_VbatOV : 28|1@1+ (1,0) [0|1] "" Vector__XXX
 SG_ SCS_a030_VbusOV : 29|1@1+ (1,0) [0|1] "" Vector__XXX
 SG_ SCS_a031_IbatOC : 30|1@1+ (1,0) [0|1] "" Vector__XXX
 SG_ SCS_a032_VBatRationality : 31|1@1+ (1,0) [0|1] "" Vector__XXX
 SG_ SCS_a033_VBusRationality : 32|1@1+ (1,0) [0|1] "" Vector__XXX
 SG_ SCS_a034_IBatRationality : 33|1@1+ (1,0) [0|1] "" Vector__XXX
 SG_ SCS_a035_unexpectedVbusBehavior : 34|1@1+ (1,0) [0|1] "" Vector__XXX
 SG_ SCS_a036_internalContactorWelded : 35|1@1+ (1,0) [0|1] "" Vector__XXX
 SG_ SCS_a037_outputContactorWelded : 36|1@1+ (1,0) [0|1] "" Vector__XXX
 SG_ SCS_a038_contactorFailedOpen : 37|1@1+ (1,0) [0|1] "" Vector__XXX
 SG_ SCS_a039_ibatRegulation : 38|1@1+ (1,0) [0|1] "" Vector__XXX
 SG_ SCS_a040_plus12VOutOfRange : 39|1@1+ (1,0) [0|1] "" Vector__XXX
 SG_ SCS_a041_minus12VOutOfRange : 40|1@1+ (1,0) [0|1] "" Vector__XXX
 SG_ SCS_a042_pilotOutOfRange : 41|1@1+ (1,0) [0|1] "" Vector__XXX
 SG_ SCS_a043_pilotRationality : 42|1@1+ (1,0) [0|1] "" Vector__XXX
 SG_ SCS_a044_proximityRationality : 43|1@1+ (1,0) [0|1] "" Vector__XXX
 SG_ SCS_a045_pcbaOT : 44|1@1+ (1,0) [0|1] "" Vector__XXX
 SG_ SCS_a046_coolantOT : 45|1@1+ (1,0) [0|1] "" Vector__XXX
 SG_ SCS_a047_cordOT : 46|1@1+ (1,0) [0|1] "" Vector__XXX
 SG_ SCS_a048_ambientOT : 47|1@1+ (1,0) [0|1] "" Vector__XXX
 SG_ SCS_a049_pcbaTempRationality : 48|1@1+ (1,0) [0|1] "" Vector__XXX
 SG_ SCS_a050_coolantTempRationality : 49|1@1+ (1,0) [0|1] "" Vector__XXX
 SG_ SCS_a051_cordTempRationality : 50|1@1+ (1,0) [0|1] "" Vector__XXX
 SG_ SCS_a052_ambientTempRationality : 51|1@1+ (1,0) [0|1] "" Vector__XXX
 SG_ SCS_a053_unexpectedThermalBehavi : 52|1@1+ (1,0) [0|1] "" Vector__XXX
 SG_ SCS_a054_pumpRegulation : 53|1@1+ (1,0) [0|1] "" Vector__XXX
 SG_ SCS_a055_coolantLevelLow : 54|1@1+ (1,0) [0|1] "" Vector__XXX
 SG_ SCS_a056_stateTransitionDenied : 55|1@1+ (1,0) [0|1] "" Vector__XXX
 SG_ SCS_a057_watchdogReset : 56|1@1+ (1,0) [0|1] "" Vector__XXX
 SG_ SCS_a058_adcRef : 57|1@1+ (1,0) [0|1] "" Vector__XXX
 SG_ SCS_a059_memoryError : 58|1@1+ (1,0) [0|1] "" Vector__XXX
 SG_ SCS_a060_swHVIL : 59|1@1+ (1,0) [0|1] "" Vector__XXX
 SG_ SCS_a061_postOutOfService : 60|1@1+ (1,0) [0|1] "" Vector__XXX
 SG_ SCS_a062_unused : 61|1@1+ (1,0) [0|1] "" Vector__XXX
 SG_ SCS_a063_canRationality : 62|1@1+ (1,0) [0|1] "" Vector__XXX
 SG_ SCS_a064_vehicleCommandTimeout : 63|1@1+ (1,0) [0|1] "" Vector__XXX

BO_ 880 SCS_alertMatrix2: 8 SCS
 SG_ SCS_a065_vBatRationalityStage1 : 0|1@1+ (1,0) [0|1] "" Vector__XXX
 SG_ SCS_a066_vBatRationalityStage2 : 1|1@1+ (1,0) [0|1] "" Vector__XXX
 SG_ SCS_a067_vBatRationalityStage3 : 2|1@1+ (1,0) [0|1] "" Vector__XXX
 SG_ SCS_a068_vBatRationalityStage4 : 3|1@1+ (1,0) [0|1] "" Vector__XXX
 SG_ SCS_a069_vStageRationalityV1 : 4|1@1+ (1,0) [0|1] "" Vector__XXX
 SG_ SCS_a070_vStageRationalityV2 : 5|1@1+ (1,0) [0|1] "" Vector__XXX
 SG_ SCS_a071_chargerMIA : 6|1@1+ (1,0) [0|1] "" Vector__XXX
 SG_ SCS_a072_gtwMIA : 7|1@1+ (1,0) [0|1] "" Vector__XXX
 SG_ SCS_a073_lccMIA : 8|1@1+ (1,0) [0|1] "" Vector__XXX
 SG_ SCS_a074_isoVDiffHi : 9|1@1+ (1,0) [0|1] "" Vector__XXX
 SG_ SCS_a075_unused75 : 10|1@1+ (1,0) [0|1] "" Vector__XXX
 SG_ SCS_a076_bmsMIA : 11|1@1+ (1,0) [0|1] "" Vector__XXX
 SG_ SCS_a077_unexpectedVbatBehavior : 12|1@1+ (1,0) [0|1] "" Vector__XXX
 SG_ SCS_a078_voltageMatchTimeout : 13|1@1+ (1,0) [0|1] "" Vector__XXX
 SG_ SCS_a079_unexpectedVbat : 14|1@1+ (1,0) [0|1] "" Vector__XXX
 SG_ SCS_a080_lccFaulted : 15|1@1+ (1,0) [0|1] "" Vector__XXX
 SG_ SCS_a081_rmsInputVoltageHigh : 16|1@1+ (1,0) [0|1] "" Vector__XXX
 SG_ SCS_a082_VbatUV : 17|1@1+ (1,0) [0|1] "" Vector__XXX
 SG_ SCS_a083_chargeCurrentLimited : 18|1@1+ (1,0) [0|1] "" Vector__XXX
 SG_ SCS_a084_unused84 : 19|1@1+ (1,0) [0|1] "" Vector__XXX
 SG_ SCS_a085_unused85 : 20|1@1+ (1,0) [0|1] "" Vector__XXX
 SG_ SCS_a086_lccResetDetected : 21|1@1+ (1,0) [0|1] "" Vector__XXX
 SG_ SCS_a087_posCordTempRationality : 22|1@1+ (1,0) [0|1] "" Vector__XXX
 SG_ SCS_a088_negCordTempRationality : 23|1@1+ (1,0) [0|1] "" Vector__XXX
 SG_ SCS_a089_posCordOT : 24|1@1+ (1,0) [0|1] "" Vector__XXX
 SG_ SCS_a090_negCordOT : 25|1@1+ (1,0) [0|1] "" Vector__XXX
 SG_ SCS_a091_voltageRiseDetection : 26|1@1+ (1,0) [0|1] "" Vector__XXX
 SG_ SCS_a092_cabEnableDeasserted : 27|1@1+ (1,0) [0|1] "" Vector__XXX
 SG_ SCS_a093_unused93 : 28|1@1+ (1,0) [0|1] "" Vector__XXX
 SG_ SCS_a094_unused94 : 29|1@1+ (1,0) [0|1] "" Vector__XXX
 SG_ SCS_a095_unused95 : 30|1@1+ (1,0) [0|1] "" Vector__XXX
 SG_ SCS_a096_unused96 : 31|1@1+ (1,0) [0|1] "" Vector__XXX
 SG_ SCS_a097_unused97 : 32|1@1+ (1,0) [0|1] "" Vector__XXX
 SG_ SCS_a098_unused98 : 33|1@1+ (1,0) [0|1] "" Vector__XXX
 SG_ SCS_a099_unused99 : 34|1@1+ (1,0) [0|1] "" Vector__XXX
 SG_ SCS_a100_unused100 : 35|1@1+ (1,0) [0|1] "" Vector__XXX
 SG_ SCS_a101_unused101 : 36|1@1+ (1,0) [0|1] "" Vector__XXX
 SG_ SCS_a102_unused102 : 37|1@1+ (1,0) [0|1] "" Vector__XXX
 SG_ SCS_a103_unused103 : 38|1@1+ (1,0) [0|1] "" Vector__XXX
 SG_ SCS_a104_unused104 : 39|1@1+ (1,0) [0|1] "" Vector__XXX
 SG_ SCS_a105_unused105 : 40|1@1+ (1,0) [0|1] "" Vector__XXX
 SG_ SCS_a106_unused106 : 41|1@1+ (1,0) [0|1] "" Vector__XXX
 SG_ SCS_a107_unused107 : 42|1@1+ (1,0) [0|1] "" Vector__XXX
 SG_ SCS_a108_unused108 : 43|1@1+ (1,0) [0|1] "" Vector__XXX
 SG_ SCS_a109_unused109 : 44|1@1+ (1,0) [0|1] "" Vector__XXX
 SG_ SCS_a110_unused110 : 45|1@1+ (1,0) [0|1] "" Vector__XXX
 SG_ SCS_a111_unused111 : 46|1@1+ (1,0) [0|1] "" Vector__XXX
 SG_ SCS_a112_unused112 : 47|1@1+ (1,0) [0|1] "" Vector__XXX
 SG_ SCS_a113_unused113 : 48|1@1+ (1,0) [0|1] "" Vector__XXX
 SG_ SCS_a114_unused114 : 49|1@1+ (1,0) [0|1] "" Vector__XXX
 SG_ SCS_a115_unused115 : 50|1@1+ (1,0) [0|1] "" Vector__XXX
 SG_ SCS_a116_unused116 : 51|1@1+ (1,0) [0|1] "" Vector__XXX
 SG_ SCS_a117_unused117 : 52|1@1+ (1,0) [0|1] "" Vector__XXX
 SG_ SCS_a118_unused118 : 53|1@1+ (1,0) [0|1] "" Vector__XXX
 SG_ SCS_a119_unused119 : 54|1@1+ (1,0) [0|1] "" Vector__XXX
 SG_ SCS_a120_unused120 : 55|1@1+ (1,0) [0|1] "" Vector__XXX
 SG_ SCS_a121_unused121 : 56|1@1+ (1,0) [0|1] "" Vector__XXX
 SG_ SCS_a122_unused122 : 57|1@1+ (1,0) [0|1] "" Vector__XXX
 SG_ SCS_a123_unused123 : 58|1@1+ (1,0) [0|1] "" Vector__XXX
 SG_ SCS_a124_unused124 : 59|1@1+ (1,0) [0|1] "" Vector__XXX
 SG_ SCS_a125_unused125 : 60|1@1+ (1,0) [0|1] "" Vector__XXX
 SG_ SCS_a126_unused126 : 61|1@1+ (1,0) [0|1] "" Vector__XXX
 SG_ SCS_a127_unused127 : 62|1@1+ (1,0) [0|1] "" Vector__XXX
 SG_ SCS_a128_unused128 : 63|1@1+ (1,0) [0|1] "" Vector__XXX

BO_ 1467 SDCR_alertMatrix: 8 SDCR
 SG_ SDCR_matrixIndex M : 0|4@1+ (1,0) [0|15] "" Vector__XXX
 SG_ SDCR_a001_powerOnSelfTestFailed m0 : 4|1@1+ (1,0) [0|1] "" Vector__XXX
 SG_ SDCR_a002_diPstSkipped m0 : 5|1@1+ (1,0) [0|1] "" Vector__XXX
 SG_ SDCR_a003_diUartMIA m0 : 6|1@1+ (1,0) [0|1] "" Vector__XXX
 SG_ SDCR_a004_pmRunningFdbkIrrationa m0 : 7|1@1+ (1,0) [0|1] "" Vector__XXX
 SG_ SDCR_a005_motorSpeedIrrational m0 : 8|1@1+ (1,0) [0|1] "" Vector__XXX
 SG_ SDCR_a006_pyroTriggered m0 : 9|1@1+ (1,0) [0|1] "" Vector__XXX
 SG_ SDCR_a007_faultCurrentsDetected m0 : 10|1@1+ (1,0) [0|1] "" Vector__XXX
 SG_ SDCR_a008_hvlinkMIA m0 : 11|1@1+ (1,0) [0|1] "" Vector__XXX
 SG_ SDCR_a009_uartVersionMismatch m0 : 12|1@1+ (1,0) [0|1] "" Vector__XXX
 SG_ SDCR_a010_vrefIrrational m0 : 13|1@1+ (1,0) [0|1] "" Vector__XXX
 SG_ SDCR_a011_phaseCurrentOffset m0 : 14|1@1+ (1,0) [0|1] "" Vector__XXX
 SG_ SDCR_a012_vBoostSecIrrational m0 : 15|1@1+ (1,0) [0|1] "" Vector__XXX
 SG_ SDCR_a013_vBkupIrrational m0 : 16|1@1+ (1,0) [0|1] "" Vector__XXX
 SG_ SDCR_a014_vBusIrrational m0 : 17|1@1+ (1,0) [0|1] "" Vector__XXX
 SG_ SDCR_a015_phaseVIrrational m0 : 18|1@1+ (1,0) [0|1] "" Vector__XXX
 SG_ SDCR_a016_systemReset m0 : 19|1@1+ (1,0) [0|1] "" Vector__XXX
 SG_ SDCR_a017_adcSPIError m0 : 20|1@1+ (1,0) [0|1] "" Vector__XXX
 SG_ SDCR_a018_historicalPyroTrigger m0 : 21|1@1+ (1,0) [0|1] "" Vector__XXX
 SG_ SDCR_a019_historicalFaultCurrent m0 : 22|1@1+ (1,0) [0|1] "" Vector__XXX
 SG_ SDCR_a020_eepromSPIError m0 : 23|1@1+ (1,0) [0|1] "" Vector__XXX
 SG_ SDCR_a021_busBarTempIrrational m0 : 24|1@1+ (1,0) [0|1] "" Vector__XXX
 SG_ SDCR_a022_TaskInitError m0 : 25|1@1+ (1,0) [0|1] "" Vector__XXX
 SG_ SDCR_a023_ecuLogAvailable m0 : 26|1@1+ (1,0) [0|1] "" Vector__XXX
 SG_ SDCR_a024_gtwMIA m0 : 27|1@1+ (1,0) [0|1] "" Vector__XXX
 SG_ SDCR_a025_diSwitchingFdbkIrratio m0 : 28|1@1+ (1,0) [0|1] "" Vector__XXX
 SG_ SDCR_a026_faultCurrentMonitoring m0 : 29|1@1+ (1,0) [0|1] "" Vector__XXX
 SG_ SDCR_a027_diCanMIA m0 : 30|1@1+ (1,0) [0|1] "" Vector__XXX
 SG_ SDCR_a028_vcLVStateMIA m0 : 31|1@1+ (1,0) [0|1] "" Vector__XXX
 SG_ SDCR_a029_diMIA m0 : 32|1@1+ (1,0) [0|1] "" Vector__XXX
 SG_ SDCR_a030_placeholder30 m0 : 33|1@1+ (1,0) [0|1] "" Vector__XXX
 SG_ SDCR_a031_placeholder31 m0 : 34|1@1+ (1,0) [0|1] "" Vector__XXX
 SG_ SDCR_a032_placeholder32 m0 : 35|1@1+ (1,0) [0|1] "" Vector__XXX
 SG_ SDCR_a033_placeholder33 m0 : 36|1@1+ (1,0) [0|1] "" Vector__XXX
 SG_ SDCR_a034_phaseCurrentIrrational m0 : 37|1@1+ (1,0) [0|1] "" Vector__XXX

BO_ 1597 SDCR_info: 8 SDCR
 SG_ SDCR_infoIndex M : 0|8@1+ (1,0) [0|255] "" Vector__XXX
 SG_ SDCR_infoBuildType m10 : 13|3@1+ (1,0) [0|7] "" Vector__XXX
 SG_ SDCR_infoBuildConfigId m10 : 16|16@1+ (1,0) [0|65535] "" Vector__XXX
 SG_ SDCR_infoHardwareId m10 : 32|16@1+ (1,0) [0|65535] "" Vector__XXX
 SG_ SDCR_infoComponentId m10 : 55|16@0+ (1,0) [0|65535] "" Vector__XXX
 SG_ SDCR_infoPcbaId m11 : 8|8@1+ (1,0) [0|255] "" Vector__XXX
 SG_ SDCR_infoAssemblyId m11 : 16|8@1+ (1,0) [0|255] "" Vector__XXX
 SG_ SDCR_infoUsageId m11 : 31|16@0+ (1,0) [0|65535] "" Vector__XXX
 SG_ SDCR_infoSubUsageId m11 : 40|16@1+ (1,0) [0|65535] "" Vector__XXX
 SG_ SDCR_infoAppCrc m13 : 15|32@0+ (1,0) [0|4294967295] "" Vector__XXX
 SG_ SDCR_infoBootGitHash m18 : 8|56@1+ (1,0) [0|7.20575940379e+16] "" Vector__XXX

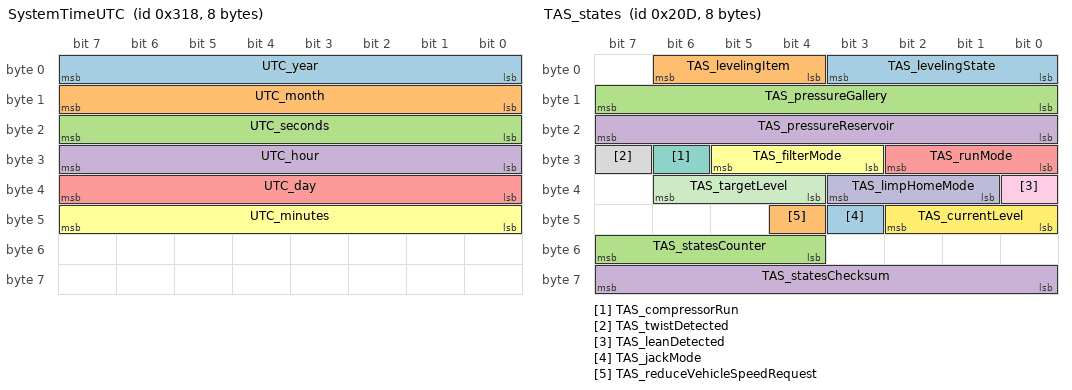
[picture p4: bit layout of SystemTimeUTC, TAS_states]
BO_ 792 SystemTimeUTC: 8 Vector__XXX
 SG_ UTC_year : 0|8@1+ (1,2000) [2000|2255] "" Vector__XXX
 SG_ UTC_month : 8|8@1+ (1,0) [1|12] "" Vector__XXX
 SG_ UTC_seconds : 16|8@1+ (1,0) [0|59] "s" Vector__XXX
 SG_ UTC_hour : 24|8@1+ (1,0) [0|23] "h" Vector__XXX
 SG_ UTC_day : 32|8@1+ (1,0) [1|31] "" Vector__XXX
 SG_ UTC_minutes : 40|8@1+ (1,0) [0|59] "min" Vector__XXX

BO_ 523 TAS_axleData: 8 TAS
 SG_ TAS_axleIndex M : 0|1@1+ (1,0) [0|1] "" Vector__XXX
 SG_ TAS_rawHeightFL m0 : 4|10@1+ (1,-512) [-512|510] "mm" Vector__XXX
 SG_ TAS_staticHeightEstimateFL m0 : 14|10@1+ (1,-512) [-512|510] "mm" Vector__XXX
 SG_ TAS_componentPressureFL m0 : 24|8@1+ (0.1,0) [0|25.4] "bara" Vector__XXX
 SG_ TAS_rawHeightFR m0 : 32|10@1+ (1,-512) [-512|510] "mm" Vector__XXX
 SG_ TAS_staticHeightEstimateFR m0 : 42|10@1+ (1,-512) [-512|510] "mm" Vector__XXX
 SG_ TAS_componentPressureFR m0 : 52|8@1+ (0.1,0) [0|25.4] "bara" Vector__XXX
 SG_ TAS_rawHeightRL m1 : 4|10@1+ (1,-512) [-512|510] "mm" Vector__XXX
 SG_ TAS_staticHeightEstimateRL m1 : 14|10@1+ (1,-512) [-512|510] "mm" Vector__XXX
 SG_ TAS_componentPressureRL m1 : 24|8@1+ (0.1,0) [0|25.4] "bara" Vector__XXX
 SG_ TAS_rawHeightRR m1 : 32|10@1+ (1,-512) [-512|510] "mm" Vector__XXX
 SG_ TAS_staticHeightEstimateRR m1 : 42|10@1+ (1,-512) [-512|510] "mm" Vector__XXX
 SG_ TAS_componentPressureRR m1 : 52|8@1+ (0.1,0) [0|25.4] "bara" Vector__XXX

BO_ 1398 TAS_dampingStates: 8 TAS
 SG_ TAS_endstopState : 0|1@1+ (1,0) [0|1] "" Vector__XXX
 SG_ TAS_continuousControlState : 1|1@1+ (1,0) [0|1] "" Vector__XXX
 SG_ TAS_activeTireTune : 2|1@1+ (1,0) [0|1] "" Vector__XXX
 SG_ TAS_roughnessRaiseReason : 3|2@1+ (1,0) [0|3] "" Vector__XXX
 SG_ TAS_frontMetricDrivesRear : 5|2@1+ (1,0) [0|3] "" Vector__XXX
 SG_ TAS_roadCondition : 8|8@1+ (0.005,0) [0|1.27] "-" Vector__XXX
 SG_ TAS_bellyProtect : 16|2@1+ (1,0) [0|3] "" Vector__XXX
 SG_ TAS_frontMetricDrivesFront : 18|2@1+ (1,0) [0|3] "" Vector__XXX
 SG_ TAS_speedBumpAxleFront : 20|3@1+ (1,0) [0|7] "" Vector__XXX
 SG_ TAS_speedBumpAxleRear : 23|3@1+ (1,0) [0|7] "" Vector__XXX
 SG_ TAS_holeProtectFL : 26|2@1+ (1,0) [0|3] "" Vector__XXX
 SG_ TAS_holeProtectFR : 28|2@1+ (1,0) [0|3] "" Vector__XXX
 SG_ TAS_holeProtectRL : 30|2@1+ (1,0) [0|3] "" Vector__XXX
 SG_ TAS_holeProtectRR : 32|2@1+ (1,0) [0|3] "" Vector__XXX
 SG_ TAS_stepProtectFL : 34|2@1+ (1,0) [0|3] "" Vector__XXX
 SG_ TAS_stepProtectFR : 36|2@1+ (1,0) [0|3] "" Vector__XXX
 SG_ TAS_stepProtectRL : 38|2@1+ (1,0) [0|3] "" Vector__XXX
 SG_ TAS_stepProtectRR : 40|2@1+ (1,0) [0|3] "" Vector__XXX
 SG_ TAS_FDUTorqueCorruptionScale : 42|4@1+ (0.075,0) [0|1.05] "-" Vector__XXX
 SG_ TAS_sprungMassEstimate : 46|5@1+ (64,1800) [1800|3720] "kg" Vector__XXX
 SG_ TAS_anyDamperActive : 51|1@1+ (1,0) [0|1] "" Vector__XXX
 SG_ TAS_dampingStatesCounter : 52|4@1+ (1,0) [0|15] "" Vector__XXX
 SG_ TAS_dampingStatesChecksum : 56|8@1+ (1,0) [0|255] "" Vector__XXX

BO_ 1357 TAS_info: 8 TAS
 SG_ TAS_infoIndex M : 0|8@1+ (1,0) [0|255] "" Vector__XXX
 SG_ TAS_infoBuildType m10 : 8|8@1+ (1,0) [0|255] "" Vector__XXX
 SG_ TAS_infoBuildConfigId m10 : 16|16@1+ (1,0) [0|65535] "" Vector__XXX
 SG_ TAS_infoHardwareId m10 : 32|1@1+ (1,0) [0|1] "" Vector__XXX
 SG_ TAS_infoComponentId m10 : 48|16@1+ (1,0) [0|65535] "" Vector__XXX
 SG_ TAS_infoPcbaId m11 : 16|8@1+ (1,0) [0|255] "" Vector__XXX
 SG_ TAS_infoAssemblyId m11 : 24|8@1+ (1,0) [0|254] "" Vector__XXX
 SG_ TAS_infoUsageId m11 : 32|16@1+ (1,0) [0|65535] "" Vector__XXX
 SG_ TAS_infoSubUsageId m11 : 48|16@1+ (1,0) [0|65535] "" Vector__XXX
 SG_ TAS_infoAppCrc m13 : 32|32@1+ (1,0) [0|4294967295] "" Vector__XXX
 SG_ TAS_infoAppGitHash m17 : 8|56@1+ (1,0) [0|7.20575940379e+16] "" Vector__XXX
 SG_ TAS_infoBootGitHash m18 : 8|56@1+ (1,0) [0|7.20575940379e+16] "" Vector__XXX
 SG_ TAS_infoPlatformType m19 : 8|8@1+ (1,0) [0|255] "" Vector__XXX
 SG_ TAS_infoMajorVersion m19 : 16|8@1+ (1,0) [0|254] "" Vector__XXX
 SG_ TAS_infoBranchOrigin m19 : 24|8@1+ (1,0) [0|254] "" Vector__XXX
 SG_ TAS_infoMaturity m19 : 32|8@1+ (1,0) [0|254] "" Vector__XXX
 SG_ TAS_infoHardwareRevision m19 : 40|8@1+ (1,0) [0|254] "" Vector__XXX

BO_ 525 TAS_states: 8 TAS
 SG_ TAS_levelingState : 0|4@1+ (1,0) [0|15] "" Vector__XXX
 SG_ TAS_levelingItem : 4|3@1+ (1,0) [0|7] "" Vector__XXX
 SG_ TAS_pressureGallery : 8|8@1+ (0.1,0) [0|25.4] "bara" Vector__XXX
 SG_ TAS_pressureReservoir : 16|8@1+ (0.1,0) [0|25.4] "bara" Vector__XXX
 SG_ TAS_runMode : 24|3@1+ (1,0) [0|7] "" Vector__XXX
 SG_ TAS_filterMode : 27|3@1+ (1,0) [0|7] "" Vector__XXX
 SG_ TAS_compressorRun : 30|1@1+ (1,0) [0|1] "" Vector__XXX
 SG_ TAS_twistDetected : 31|1@1+ (1,0) [0|1] "" Vector__XXX
 SG_ TAS_leanDetected : 32|1@1+ (1,0) [0|1] "" Vector__XXX
 SG_ TAS_limpHomeMode : 33|3@1+ (1,0) [0|7] "" Vector__XXX
 SG_ TAS_targetLevel : 36|3@1+ (1,0) [0|7] "" Vector__XXX
 SG_ TAS_currentLevel : 40|3@1+ (1,0) [0|7] "" Vector__XXX
 SG_ TAS_jackMode : 43|1@1+ (1,0) [0|1] "" Vector__XXX
 SG_ TAS_reduceVehicleSpeedRequest : 44|1@1+ (1,0) [0|1] "" Vector__XXX
 SG_ TAS_statesCounter : 52|4@1+ (1,0) [0|15] "" Vector__XXX
 SG_ TAS_statesChecksum : 56|8@1+ (1,0) [0|255] "" Vector__XXX

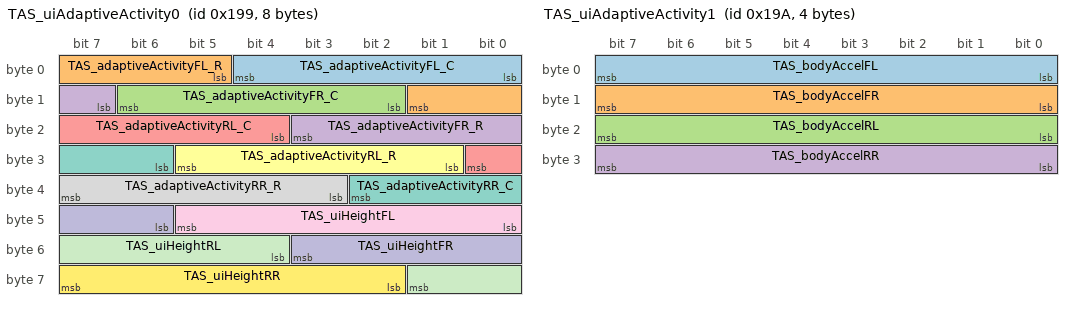
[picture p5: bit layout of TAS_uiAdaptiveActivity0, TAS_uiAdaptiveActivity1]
BO_ 409 TAS_uiAdaptiveActivity0: 8 TAS
 SG_ TAS_adaptiveActivityFL_C : 0|5@1+ (0.04,0) [0|1] "-" Vector__XXX
 SG_ TAS_adaptiveActivityFL_R : 5|5@1+ (0.04,0) [0|1] "-" Vector__XXX
 SG_ TAS_adaptiveActivityFR_C : 10|5@1+ (0.04,0) [0|1] "-" Vector__XXX
 SG_ TAS_adaptiveActivityFR_R : 15|5@1+ (0.04,0) [0|1] "-" Vector__XXX
 SG_ TAS_adaptiveActivityRL_C : 20|5@1+ (0.04,0) [0|1] "-" Vector__XXX
 SG_ TAS_adaptiveActivityRL_R : 25|5@1+ (0.04,0) [0|1] "-" Vector__XXX
 SG_ TAS_adaptiveActivityRR_C : 30|5@1+ (0.04,0) [0|1] "-" Vector__XXX
 SG_ TAS_adaptiveActivityRR_R : 35|5@1+ (0.04,0) [0|1] "-" Vector__XXX
 SG_ TAS_uiHeightFL : 40|6@1+ (4,-128) [-128|120] "mm" Vector__XXX
 SG_ TAS_uiHeightFR : 46|6@1+ (4,-128) [-128|120] "mm" Vector__XXX
 SG_ TAS_uiHeightRL : 52|6@1+ (4,-128) [-128|120] "mm" Vector__XXX
 SG_ TAS_uiHeightRR : 58|6@1+ (4,-128) [-128|120] "mm" Vector__XXX

BO_ 410 TAS_uiAdaptiveActivity1: 4 TAS
 SG_ TAS_bodyAccelFL : 0|8@1+ (0.05,-5) [-5|5] "g" Vector__XXX
 SG_ TAS_bodyAccelFR : 8|8@1+ (0.05,-5) [-5|5] "g" Vector__XXX
 SG_ TAS_bodyAccelRL : 16|8@1+ (0.05,-5) [-5|5] "g" Vector__XXX
 SG_ TAS_bodyAccelRR : 24|8@1+ (0.05,-5) [-5|5] "g" Vector__XXX

BO_ 538 TAS_uiControl: 5 TAS
 SG_ TAS_yellowWarningLamp : 0|1@1+ (1,0) [0|1] "" Vector__XXX
 SG_ TAS_redWarningLamp : 1|1@1+ (1,0) [0|1] "" Vector__XXX
 SG_ TAS_veryLowAllowed : 2|1@1+ (1,0) [0|1] "" Vector__XXX
 SG_ TAS_lowAllowed : 3|1@1+ (1,0) [0|1] "" Vector__XXX
 SG_ TAS_standardAllowed : 4|1@1+ (1,0) [0|1] "" Vector__XXX
 SG_ TAS_highAllowed : 5|1@1+ (1,0) [0|1] "" Vector__XXX
 SG_ TAS_veryHighAllowed : 6|1@1+ (1,0) [0|1] "" Vector__XXX
 SG_ TAS_extractAllowed : 7|1@1+ (1,0) [0|1] "" Vector__XXX
 SG_ TAS_showSpinner : 9|1@1+ (1,0) [0|1] "" Vector__XXX
 SG_ TAS_adaptiveRideModeOverride : 10|2@1+ (1,0) [0|2] "" Vector__XXX
 SG_ TAS_levelSelectEnabled : 12|1@1+ (1,0) [0|1] "" Vector__XXX
 SG_ TAS_jackModeToggleEnabled : 13|1@1+ (1,0) [0|1] "" Vector__XXX
 SG_ TAS_adaptiveRideSelectEnabled : 14|1@1+ (1,0) [0|1] "" Vector__XXX
 SG_ TAS_launchModeState : 16|3@1+ (1,0) [0|7] "" Vector__XXX
 SG_ TAS_restrictUpLevelingFalcons : 19|1@1+ (1,0) [0|1] "" Vector__XXX
 SG_ TAS_restrictUpLevelingTrunk : 20|1@1+ (1,0) [0|1] "" Vector__XXX
 SG_ TAS_restrictDownLevelingDoors : 21|1@1+ (1,0) [0|1] "" Vector__XXX
 SG_ TAS_restrictLevelingChargeCable : 22|1@1+ (1,0) [0|1] "" Vector__XXX
 SG_ TAS_restrictLevelingSystemCheck : 23|1@1+ (1,0) [0|1] "" Vector__XXX
 SG_ TAS_restrictLevelingTransport : 24|1@1+ (1,0) [0|1] "" Vector__XXX
 SG_ TAS_restrictLevelingShowroom : 25|1@1+ (1,0) [0|1] "" Vector__XXX
 SG_ TAS_uiControlCounter : 28|4@1+ (1,0) [0|15] "" Vector__XXX
 SG_ TAS_uiControlChecksum : 32|8@1+ (1,0) [0|255] "" Vector__XXX

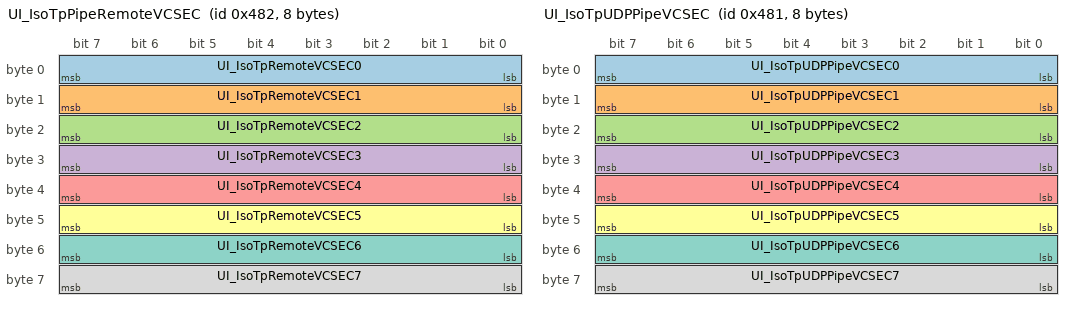
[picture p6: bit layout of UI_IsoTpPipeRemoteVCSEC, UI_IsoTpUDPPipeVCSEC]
BO_ 1154 UI_IsoTpPipeRemoteVCSEC: 8 GTW
 SG_ UI_IsoTpRemoteVCSEC0 : 0|8@1+ (1,0) [0|255] "" Vector__XXX
 SG_ UI_IsoTpRemoteVCSEC1 : 8|8@1+ (1,0) [0|255] "" Vector__XXX
 SG_ UI_IsoTpRemoteVCSEC2 : 16|8@1+ (1,0) [0|255] "" Vector__XXX
 SG_ UI_IsoTpRemoteVCSEC3 : 24|8@1+ (1,0) [0|255] "" Vector__XXX
 SG_ UI_IsoTpRemoteVCSEC4 : 32|8@1+ (1,0) [0|255] "" Vector__XXX
 SG_ UI_IsoTpRemoteVCSEC5 : 40|8@1+ (1,0) [0|255] "" Vector__XXX
 SG_ UI_IsoTpRemoteVCSEC6 : 48|8@1+ (1,0) [0|255] "" Vector__XXX
 SG_ UI_IsoTpRemoteVCSEC7 : 56|8@1+ (1,0) [0|255] "" Vector__XXX

BO_ 1153 UI_IsoTpUDPPipeVCSEC: 8 GTW
 SG_ UI_IsoTpUDPPipeVCSEC0 : 0|8@1+ (1,0) [0|255] "" Vector__XXX
 SG_ UI_IsoTpUDPPipeVCSEC1 : 8|8@1+ (1,0) [0|255] "" Vector__XXX
 SG_ UI_IsoTpUDPPipeVCSEC2 : 16|8@1+ (1,0) [0|255] "" Vector__XXX
 SG_ UI_IsoTpUDPPipeVCSEC3 : 24|8@1+ (1,0) [0|255] "" Vector__XXX
 SG_ UI_IsoTpUDPPipeVCSEC4 : 32|8@1+ (1,0) [0|255] "" Vector__XXX
 SG_ UI_IsoTpUDPPipeVCSEC5 : 40|8@1+ (1,0) [0|255] "" Vector__XXX
 SG_ UI_IsoTpUDPPipeVCSEC6 : 48|8@1+ (1,0) [0|255] "" Vector__XXX
 SG_ UI_IsoTpUDPPipeVCSEC7 : 56|8@1+ (1,0) [0|255] "" Vector__XXX

BO_ 659 UI_chassisControl: 8 GTW
 SG_ UI_steeringTuneRequest : 0|2@1+ (1,0) [0|3] "" Vector__XXX
 SG_ UI_tractionControlMode : 2|3@1+ (1,0) [0|7] "" Vector__XXX
 SG_ UI_parkBrakeRequest : 5|2@1+ (1,0) [0|2] "" Vector__XXX
 SG_ UI_narrowGarages : 7|1@1+ (1,0) [0|1] "" Vector__XXX
 SG_ UI_winchModeRequest : 8|2@1+ (1,0) [0|3] "" Vector__XXX
 SG_ UI_zeroSpeedConfirmed : 10|2@1+ (1,0) [0|2] "" Vector__XXX
 SG_ UI_trailerMode : 12|1@1+ (1,0) [0|1] "" Vector__XXX
 SG_ UI_distanceUnits : 13|1@1+ (1,0) [0|1] "" Vector__XXX
 SG_ UI_dasDebugEnable : 14|1@1+ (1,0) [0|1] "" Vector__XXX
 SG_ UI_accOvertakeEnable : 16|2@1+ (1,0) [0|2] "" Vector__XXX
 SG_ UI_aebEnable : 18|2@1+ (1,0) [0|2] "" Vector__XXX
 SG_ UI_aesEnable : 20|2@1+ (1,0) [0|2] "" Vector__XXX
 SG_ UI_ahlbEnable : 22|2@1+ (1,0) [0|2] "" Vector__XXX
 SG_ UI_autoLaneChangeEnable : 24|2@1+ (1,0) [0|2] "" Vector__XXX
 SG_ UI_winchProxUserOverride : 26|1@1+ (1,0) [0|1] "" Vector__XXX
 SG_ UI_rebootAutopilot : 27|1@1+ (1,0) [0|1] "" Vector__XXX
 SG_ UI_autoParkRequest : 28|4@1+ (1,0) [0|14] "" Vector__XXX
 SG_ UI_bsdEnable : 32|2@1+ (1,0) [0|2] "" Vector__XXX
 SG_ UI_fcwEnable : 34|2@1+ (1,0) [0|2] "" Vector__XXX
 SG_ UI_fcwSensitivity : 36|2@1+ (1,0) [0|2] "" Vector__XXX
 SG_ UI_latControlEnable : 38|2@1+ (1,0) [0|2] "" Vector__XXX
 SG_ UI_ldwEnable : 40|2@1+ (1,0) [0|2] "" Vector__XXX
 SG_ UI_pedalSafetyEnable : 42|2@1+ (1,0) [0|2] "" Vector__XXX
 SG_ UI_pedalMap_epas : 44|2@1+ (1,0) [0|3] "" Vector__XXX
 SG_ UI_redLightStopSignEnable : 46|2@1+ (1,0) [0|2] "" Vector__XXX
 SG_ UI_selfParkTune : 48|4@1+ (1,0) [0|14] "" Vector__XXX
 SG_ UI_chassisControlCounter : 52|4@1+ (1,0) [0|15] "" Vector__XXX
 SG_ UI_chassisControlChecksum : 56|8@1+ (1,0) [0|255] "" Vector__XXX

BO_ 1280 UI_debugECU: 2 GTW
 SG_ UI_debugEcuTarget M : 0|5@1+ (1,0) [0|31] "" Vector__XXX
 SG_ UI_DI_debugEnable m1 : 8|1@1+ (1,0) [0|1] "" Vector__XXX
 SG_ UI_DIS_debugEnable m2 : 8|1@1+ (1,0) [0|1] "" Vector__XXX
 SG_ UI_PM_debugEnable m3 : 8|1@1+ (1,0) [0|1] "" Vector__XXX
 SG_ UI_PM_debugAt100Hz m3 : 9|1@1+ (1,0) [0|1] "" Vector__XXX
 SG_ UI_PMS_debugEnable m4 : 8|1@1+ (1,0) [0|1] "" Vector__XXX
 SG_ UI_PMS_debugAt100Hz m4 : 9|1@1+ (1,0) [0|1] "" Vector__XXX
 SG_ UI_BMS_debugAllEnable m5 : 8|1@1+ (1,0) [0|1] "" Vector__XXX
 SG_ UI_BMS_debugDisable m5 : 9|1@1+ (1,0) [0|1] "" Vector__XXX
 SG_ UI_VCRIGHT_debugEnable m6 : 8|1@1+ (1,0) [0|1] "" Vector__XXX
 SG_ UI_VCFRONT_debugEnable m7 : 5|1@1+ (1,0) [0|1] "" Vector__XXX
 SG_ UI_DIF_debugEnable m8 : 8|1@1+ (1,0) [0|1] "" Vector__XXX
 SG_ UI_DIR_debugEnable m9 : 8|1@1+ (1,0) [0|1] "" Vector__XXX
 SG_ UI_PMF_debugEnable m10 : 8|1@1+ (1,0) [0|1] "" Vector__XXX
 SG_ UI_PMR_debugEnable m11 : 8|1@1+ (1,0) [0|1] "" Vector__XXX

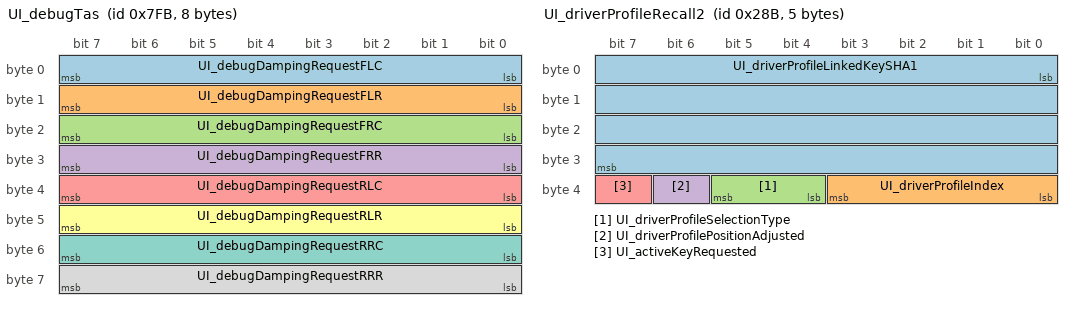
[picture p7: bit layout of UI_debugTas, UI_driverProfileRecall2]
BO_ 2043 UI_debugTas: 8 GTW
 SG_ UI_debugDampingRequestFLC : 0|8@1+ (0.01,0) [0|2.54] "A" Vector__XXX
 SG_ UI_debugDampingRequestFLR : 8|8@1+ (0.01,0) [0|2.54] "A" Vector__XXX
 SG_ UI_debugDampingRequestFRC : 16|8@1+ (0.01,0) [0|2.54] "A" Vector__XXX
 SG_ UI_debugDampingRequestFRR : 24|8@1+ (0.01,0) [0|2.54] "A" Vector__XXX
 SG_ UI_debugDampingRequestRLC : 32|8@1+ (0.01,0) [0|2.54] "A" Vector__XXX
 SG_ UI_debugDampingRequestRLR : 40|8@1+ (0.01,0) [0|2.54] "A" Vector__XXX
 SG_ UI_debugDampingRequestRRC : 48|8@1+ (0.01,0) [0|2.54] "A" Vector__XXX
 SG_ UI_debugDampingRequestRRR : 56|8@1+ (0.01,0) [0|2.54] "A" Vector__XXX

BO_ 568 UI_driverAssistMapData: 8 GTW
 SG_ UI_mapSpeedLimitDependency : 0|3@1+ (1,0) [0|6] "" Vector__XXX
 SG_ UI_roadClass : 3|3@1+ (1,0) [1|7] "" Vector__XXX
 SG_ UI_inSuperchargerGeofence : 6|1@1+ (1,0) [0|1] "" Vector__XXX
 SG_ UI_mapSpeedUnits : 7|1@1+ (1,0) [0|1] "" Vector__XXX
 SG_ UI_mapSpeedLimit : 8|5@1+ (1,0) [0|30] "" Vector__XXX
 SG_ UI_mapSpeedLimitType : 13|3@1+ (1,0) [0|6] "" Vector__XXX
 SG_ UI_countryCode : 16|10@1+ (1,0) [0|1022] "" Vector__XXX
 SG_ UI_streetCount : 26|2@1+ (1,0) [0|3] "" Vector__XXX
 SG_ UI_gpsRoadMatch : 28|1@1+ (1,0) [0|1] "" Vector__XXX
 SG_ UI_navRouteActive : 29|1@1+ (1,0) [0|1] "" Vector__XXX
 SG_ UI_parallelAutoparkEnabled : 30|1@1+ (1,0) [0|1] "" Vector__XXX
 SG_ UI_perpendicularAutoparkEnabled : 31|1@1+ (1,0) [0|1] "" Vector__XXX
 SG_ UI_nextBranchDist : 32|5@1+ (10,0) [0|300] "m" Vector__XXX
 SG_ UI_controlledAccess : 37|1@1+ (1,0) [0|1] "" Vector__XXX
 SG_ UI_nextBranchLeftOffRamp : 38|1@1+ (1,0) [0|1] "" Vector__XXX
 SG_ UI_nextBranchRightOffRamp : 39|1@1+ (1,0) [0|1] "" Vector__XXX
 SG_ UI_rejectLeftLane : 40|1@1+ (1,0) [0|1] "" Vector__XXX
 SG_ UI_rejectRightLane : 41|1@1+ (1,0) [0|1] "" Vector__XXX
 SG_ UI_rejectHPP : 42|1@1+ (1,0) [0|1] "" Vector__XXX
 SG_ UI_rejectNav : 43|1@1+ (1,0) [0|1] "" Vector__XXX
 SG_ UI_rejectLeftFreeSpace : 44|1@1+ (1,0) [0|1] "" Vector__XXX
 SG_ UI_rejectRightFreeSpace : 45|1@1+ (1,0) [0|1] "" Vector__XXX
 SG_ UI_rejectAutosteer : 46|1@1+ (1,0) [0|1] "" Vector__XXX
 SG_ UI_rejectHandsOn : 47|1@1+ (1,0) [0|1] "" Vector__XXX
 SG_ UI_acceptBottsDots : 48|1@1+ (1,0) [0|1] "" Vector__XXX
 SG_ UI_autosteerRestricted : 49|1@1+ (1,0) [0|1] "" Vector__XXX
 SG_ UI_pmmEnabled : 50|1@1+ (1,0) [0|1] "" Vector__XXX
 SG_ UI_scaEnabled : 51|1@1+ (1,0) [0|1] "" Vector__XXX
 SG_ UI_mapDataCounter : 52|4@1+ (1,0) [0|15] "" Vector__XXX
 SG_ UI_mapDataChecksum : 56|8@1+ (1,0) [0|255] "" Vector__XXX

BO_ 651 UI_driverProfileRecall2: 5 GTW
 SG_ UI_driverProfileLinkedKeySHA1 : 0|32@1+ (1,0) [0|4294967294] "" Vector__XXX
 SG_ UI_driverProfileIndex : 32|4@1+ (1,0) [0|15] "" Vector__XXX
 SG_ UI_driverProfileSelectionType : 36|2@1+ (1,0) [0|3] "" Vector__XXX
 SG_ UI_driverProfilePositionAdjusted : 38|1@1+ (1,0) [0|1] "" Vector__XXX
 SG_ UI_activeKeyRequested : 39|1@1+ (1,0) [0|1] "" Vector__XXX

BO_ 984 UI_elevationStatus: 4 GTW
 SG_ UI_elevation : 0|14@1- (1,0) [-8192|8190] "m" Vector__XXX
 SG_ UI_navElevation : 16|14@1- (1,0) [-8192|8190] "m" Vector__XXX

BO_ 804 UI_gpsTime: 8 GTW
 SG_ UI_gpsTime : 0|64@1+ (1,0) [0|1.84467440737e+19] "" Vector__XXX

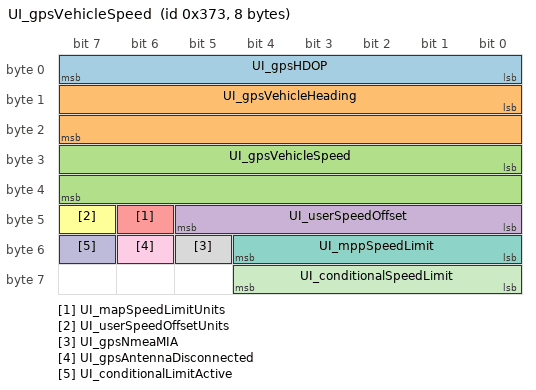
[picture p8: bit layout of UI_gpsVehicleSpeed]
BO_ 883 UI_gpsVehicleSpeed: 8 GTW
 SG_ UI_gpsHDOP : 0|8@1+ (0.1,0) [0|25.5] "1" Vector__XXX
 SG_ UI_gpsVehicleHeading : 8|16@1+ (0.0078125,0) [0|511.9921875] "deg" Vector__XXX
 SG_ UI_gpsVehicleSpeed : 24|16@1+ (0.00390625,0) [0|255.99609375] "km/hr" Vector__XXX
 SG_ UI_userSpeedOffset : 40|6@1+ (1,-30) [-30|33] "kph/mph" Vector__XXX
 SG_ UI_mapSpeedLimitUnits : 46|1@1+ (1,0) [0|1] "" Vector__XXX
 SG_ UI_userSpeedOffsetUnits : 47|1@1+ (1,0) [0|1] "" Vector__XXX
 SG_ UI_mppSpeedLimit : 48|5@1+ (5,0) [0|155] "kph/mph" Vector__XXX
 SG_ UI_gpsNmeaMIA : 53|1@1+ (1,0) [0|1] "" Vector__XXX
 SG_ UI_gpsAntennaDisconnected : 54|1@1+ (1,0) [0|1] "" Vector__XXX
 SG_ UI_conditionalLimitActive : 55|1@1+ (1,0) [0|1] "" Vector__XXX
 SG_ UI_conditionalSpeedLimit : 56|5@1+ (5,0) [0|150] "kph/mph" Vector__XXX

BO_TX_BU_ 1012 : GTW;
BO_TX_BU_ 612 : PCS;
BO_TX_BU_ 692 : PCS;
BO_TX_BU_ 964 : PCS;
BO_TX_BU_ 676 : PCS;
BO_TX_BU_ 790 : PMF;
BO_TX_BU_ 1748 : PMR;
BO_TX_BU_ 1551 : PM;
BO_TX_BU_ 1766 : GTW;
BO_TX_BU_ 837 : PTC;
BO_TX_BU_ 647 : PTC;
BO_TX_BU_ 1359 : SCCM;
BO_TX_BU_ 816 : SCCM;
BO_TX_BU_ 585 : SCCM;
BO_TX_BU_ 553 : SCCM;
BO_TX_BU_ 297 : SCCM;
BO_TX_BU_ 1356 : SCM;
BO_TX_BU_ 815 : SCM;
BO_TX_BU_ 1355 : SCM;
BO_TX_BU_ 1354 : SCS;
BO_TX_BU_ 869 : SCS;
BO_TX_BU_ 880 : SCS;
BO_TX_BU_ 1467 : SDCR;
BO_TX_BU_ 1597 : SDCR;
BO_TX_BU_ 523 : TAS;
BO_TX_BU_ 1398 : TAS;
BO_TX_BU_ 1357 : TAS;
BO_TX_BU_ 525 : TAS;
BO_TX_BU_ 409 : TAS;
BO_TX_BU_ 410 : TAS;
BO_TX_BU_ 538 : TAS;
BO_TX_BU_ 1154 : GTW;
BO_TX_BU_ 1153 : GTW;
BO_TX_BU_ 659 : GTW;
BO_TX_BU_ 1280 : GTW;
BO_TX_BU_ 2043 : GTW;
BO_TX_BU_ 568 : GTW;
BO_TX_BU_ 651 : GTW;
BO_TX_BU_ 984 : GTW;
BO_TX_BU_ 804 : GTW;
BO_TX_BU_ 883 : GTW;
CM_ BO_ 1012 "LS ECU message: light show; forwarded onto this bus by the gateway; frame length from the layout, not yet observed on a vehicle bus";
CM_ SG_ 1012 LS_lightShowIndex "LS ECU: light show index";
CM_ SG_ 1012 LS_lightLeftRampedChannel1Reques "LS ECU: light left ramped channel1 request";
CM_ SG_ 1012 LS_lightLeftRampedChannel1Durati "LS ECU: light left ramped channel1 duration";
CM_ SG_ 1012 LS_lightLeftRampedChannel2Reques "LS ECU: light left ramped channel2 request";
CM_ SG_ 1012 LS_lightLeftRampedChannel2Durati "LS ECU: light left ramped channel2 duration";
CM_ SG_ 1012 LS_lightLeftRampedChannel3Reques "LS ECU: light left ramped channel3 request";
CM_ SG_ 1012 LS_lightLeftRampedChannel3Durati "LS ECU: light left ramped channel3 duration";
CM_ SG_ 1012 LS_lightLeftRampedChannel4Reques "LS ECU: light left ramped channel4 request";
CM_ SG_ 1012 LS_lightLeftRampedChannel4Durati "LS ECU: light left ramped channel4 duration";
CM_ SG_ 1012 LS_lightLeftRampedChannel5Reques "LS ECU: light left ramped channel5 request";
CM_ SG_ 1012 LS_lightLeftRampedChannel5Durati "LS ECU: light left ramped channel5 duration";
CM_ SG_ 1012 LS_lightLeftRampedChannel6Reques "LS ECU: light left ramped channel6 request";
CM_ SG_ 1012 LS_lightLeftRampedChannel6Durati "LS ECU: light left ramped channel6 duration";
CM_ SG_ 1012 LS_lightLeftRampedChannel7Reques "LS ECU: light left ramped channel7 request";
CM_ SG_ 1012 LS_lightLeftRampedChannel7Durati "LS ECU: light left ramped channel7 duration";
CM_ SG_ 1012 LS_lightRightRampedChannel1Reque "LS ECU: light right ramped channel1 request";
CM_ SG_ 1012 LS_lightRightRampedChannel1Durat "LS ECU: light right ramped channel1 duration; raw 1 = signal not available (SNA)";
CM_ SG_ 1012 LS_lightRightRampedChannel2Reque "LS ECU: light right ramped channel2 request";
CM_ SG_ 1012 LS_lightRightRampedChannel2Durat "LS ECU: light right ramped channel2 duration; raw 1 = signal not available (SNA)";
CM_ SG_ 1012 LS_lightRightRampedChannel3Reque "LS ECU: light right ramped channel3 request";
CM_ SG_ 1012 LS_lightRightRampedChannel3Durat "LS ECU: light right ramped channel3 duration";
CM_ SG_ 1012 LS_lightRightRampedChannel4Reque "LS ECU: light right ramped channel4 request";
CM_ SG_ 1012 LS_lightRightRampedChannel4Durat "LS ECU: light right ramped channel4 duration";
CM_ SG_ 1012 LS_lightRightRampedChannel5Reque "LS ECU: light right ramped channel5 request";
CM_ SG_ 1012 LS_lightRightRampedChannel5Durat "LS ECU: light right ramped channel5 duration";
CM_ SG_ 1012 LS_lightRightRampedChannel6Reque "LS ECU: light right ramped channel6 request";
CM_ SG_ 1012 LS_lightRightRampedChannel6Durat "LS ECU: light right ramped channel6 duration";
CM_ SG_ 1012 LS_lightRightRampedChannel7Reque "LS ECU: light right ramped channel7 request";
CM_ SG_ 1012 LS_lightRightRampedChannel7Durat "LS ECU: light right ramped channel7 duration";
CM_ SG_ 1012 LS_lightRearTurnLeftRequest "LS ECU: light rear turn left request";
CM_ SG_ 1012 LS_lightRearTurnRightRequest "LS ECU: light rear turn right request";
CM_ SG_ 1012 LS_lightSideRepeaterLeftRequest "LS ECU: light side repeater left request";
CM_ SG_ 1012 LS_lightSideRepeaterRightRequest "LS ECU: light side repeater right request";
CM_ SG_ 1012 LS_lightSideMarkerLeftRequest "LS ECU: light side marker left request";
CM_ SG_ 1012 LS_lightSideMarkerRightRequest "LS ECU: light side marker right request";
CM_ SG_ 1012 LS_lightFrontFogLeftRequest "LS ECU: light front fog left request";
CM_ SG_ 1012 LS_lightFrontFogRightRequest "LS ECU: light front fog right request";
CM_ SG_ 1012 LS_lightRearFogRequest "LS ECU: light rear fog request";
CM_ SG_ 1012 LS_lightBrakeRequest "LS ECU: light brake request";
CM_ SG_ 1012 LS_lightTailLeftRequest "LS ECU: light tail left request";
CM_ SG_ 1012 LS_lightTailRightRequest "LS ECU: light tail right request";
CM_ SG_ 1012 LS_lightLicensePlateRequest "LS ECU: light license plate request";
CM_ SG_ 1012 LS_lightReverseRequest "LS ECU: light reverse request";
CM_ SG_ 1012 LS_lightAuxParkLeftRequest "LS ECU: light aux park left request";
CM_ SG_ 1012 LS_lightAuxParkRightRequest "LS ECU: light aux park right request";
CM_ SG_ 1012 LS_mirrorRequestLeft "LS ECU: mirror request left";
CM_ SG_ 1012 LS_mirrorRequestRight "LS ECU: mirror request right";
CM_ SG_ 1012 LS_liftgateRequest "LS ECU: liftgate request";
CM_ SG_ 1012 LS_windowRequestLF "LS ECU: window request LF";
CM_ SG_ 1012 LS_windowRequestLR "LS ECU: window request LR";
CM_ SG_ 1012 LS_windowRequestRF "LS ECU: window request RF";
CM_ SG_ 1012 LS_windowRequestRR "LS ECU: window request RR";
CM_ SG_ 1012 LS_presentingHandleRequestLF "LS ECU: presenting handle request LF";
CM_ SG_ 1012 LS_presentingHandleRequestLR "LS ECU: presenting handle request LR";
CM_ SG_ 1012 LS_presentingHandleRequestRF "LS ECU: presenting handle request RF";
CM_ SG_ 1012 LS_presentingHandleRequestRR "LS ECU: presenting handle request RR";
CM_ SG_ 1012 LS_powerFrontDoorRequestLeft "LS ECU: power front door request left";
CM_ SG_ 1012 LS_powerFrontDoorRequestRight "LS ECU: power front door request right";
CM_ SG_ 1012 LS_falconDoorRequestLeft "LS ECU: falcon door request left";
CM_ SG_ 1012 LS_falconDoorRequestRight "LS ECU: falcon door request right";
CM_ SG_ 1012 LS_chargePortRequest "LS ECU: charge port request; raw 3 = signal not available (SNA)";
CM_ SG_ 1012 LS_chargePortRaveRequest "LS ECU: charge port rave request";
CM_ SG_ 1012 LS_suspensionRequest "LS ECU: suspension request; raw 3 = signal not available (SNA)";
CM_ SG_ 1012 LS_rgbIPFLRed "LS ECU: rgb IPFL red";
CM_ SG_ 1012 LS_rgbIPFLGreen "LS ECU: rgb IPFL green";
CM_ SG_ 1012 LS_rgbIPFLBlue "LS ECU: rgb IPFL blue";
CM_ SG_ 1012 LS_rgbIPFRRed "LS ECU: rgb IPFR red";
CM_ SG_ 1012 LS_rgbIPFRGreen "LS ECU: rgb IPFR green";
CM_ SG_ 1012 LS_rgbIPFRBlue "LS ECU: rgb IPFR blue";
CM_ SG_ 1012 LS_rgbDoorFLForeRed "LS ECU: rgb door FL fore red";
CM_ SG_ 1012 LS_rgbDoorFLForeGreen "LS ECU: rgb door FL fore green";
CM_ SG_ 1012 LS_rgbDoorFLForeBlue "LS ECU: rgb door FL fore blue";
CM_ SG_ 1012 LS_rgbDoorFLAftRed "LS ECU: rgb door FL aft red";
CM_ SG_ 1012 LS_rgbDoorFLAftGreen "LS ECU: rgb door FL aft green";
CM_ SG_ 1012 LS_rgbDoorFLAftBlue "LS ECU: rgb door FL aft blue";
CM_ SG_ 1012 LS_rgbDoorFRForeRed "LS ECU: rgb door FR fore red";
CM_ SG_ 1012 LS_rgbDoorFRForeGreen "LS ECU: rgb door FR fore green";
CM_ SG_ 1012 LS_rgbDoorFRForeBlue "LS ECU: rgb door FR fore blue";
CM_ SG_ 1012 LS_rgbDoorFRAftRed "LS ECU: rgb door FR aft red";
CM_ SG_ 1012 LS_rgbDoorFRAftGreen "LS ECU: rgb door FR aft green";
CM_ SG_ 1012 LS_rgbDoorFRAftBlue "LS ECU: rgb door FR aft blue";
CM_ SG_ 1012 LS_rgbDoorRLForeRed "LS ECU: rgb door RL fore red";
CM_ SG_ 1012 LS_rgbDoorRLForeGreen "LS ECU: rgb door RL fore green";
CM_ SG_ 1012 LS_rgbDoorRLForeBlue "LS ECU: rgb door RL fore blue";
CM_ SG_ 1012 LS_rgbDoorRLAftRed "LS ECU: rgb door RL aft red";
CM_ SG_ 1012 LS_rgbDoorRLAftGreen "LS ECU: rgb door RL aft green";
CM_ SG_ 1012 LS_rgbDoorRLAftBlue "LS ECU: rgb door RL aft blue";
CM_ SG_ 1012 LS_rgbDoorRRForeRed "LS ECU: rgb door RR fore red";
CM_ SG_ 1012 LS_rgbDoorRRForeGreen "LS ECU: rgb door RR fore green";
CM_ SG_ 1012 LS_rgbDoorRRForeBlue "LS ECU: rgb door RR fore blue";
CM_ SG_ 1012 LS_rgbDoorRRAftRed "LS ECU: rgb door RR aft red";
CM_ SG_ 1012 LS_rgbDoorRRAftGreen "LS ECU: rgb door RR aft green";
CM_ SG_ 1012 LS_rgbDoorRRAftBlue "LS ECU: rgb door RR aft blue";
CM_ SG_ 1012 LS_frontMatrix0 "LS ECU: front matrix0";
CM_ SG_ 1012 LS_frontMatrix1 "LS ECU: front matrix1";
CM_ SG_ 1012 LS_frontMatrix2 "LS ECU: front matrix2";
CM_ SG_ 1012 LS_frontMatrix3 "LS ECU: front matrix3";
CM_ SG_ 1012 LS_frontMatrix4 "LS ECU: front matrix4";
CM_ SG_ 1012 LS_frontMatrix5 "LS ECU: front matrix5";
CM_ SG_ 1012 LS_frontMatrix6 "LS ECU: front matrix6";
CM_ SG_ 1012 LS_frontMatrix7 "LS ECU: front matrix7";
CM_ SG_ 1012 LS_frontMatrix8 "LS ECU: front matrix8";
CM_ SG_ 1012 LS_frontMatrix9 "LS ECU: front matrix9";
CM_ SG_ 1012 LS_frontMatrix10 "LS ECU: front matrix10";
CM_ SG_ 1012 LS_frontMatrix11 "LS ECU: front matrix11";
CM_ SG_ 1012 LS_frontMatrix12 "LS ECU: front matrix12";
CM_ SG_ 1012 LS_frontMatrix13 "LS ECU: front matrix13";
CM_ SG_ 1012 LS_frontMatrix14 "LS ECU: front matrix14";
CM_ SG_ 1012 LS_frontMatrix15 "LS ECU: front matrix15";
CM_ SG_ 1012 LS_frontMatrix16 "LS ECU: front matrix16";
CM_ SG_ 1012 LS_frontMatrix17 "LS ECU: front matrix17";
CM_ SG_ 1012 LS_frontMatrix18 "LS ECU: front matrix18";
CM_ SG_ 1012 LS_frontMatrix19 "LS ECU: front matrix19";
CM_ SG_ 1012 LS_frontMatrix20 "LS ECU: front matrix20";
CM_ SG_ 1012 LS_frontMatrix21 "LS ECU: front matrix21";
CM_ SG_ 1012 LS_frontMatrix22 "LS ECU: front matrix22";
CM_ SG_ 1012 LS_frontMatrix23 "LS ECU: front matrix23";
CM_ SG_ 1012 LS_frontMatrix24 "LS ECU: front matrix24";
CM_ SG_ 1012 LS_frontMatrix25 "LS ECU: front matrix25";
CM_ SG_ 1012 LS_frontMatrix26 "LS ECU: front matrix26";
CM_ SG_ 1012 LS_frontMatrix27 "LS ECU: front matrix27";
CM_ SG_ 1012 LS_frontMatrix28 "LS ECU: front matrix28";
CM_ SG_ 1012 LS_frontMatrix29 "LS ECU: front matrix29";
CM_ SG_ 1012 LS_frontMatrix30 "LS ECU: front matrix30";
CM_ SG_ 1012 LS_frontMatrix31 "LS ECU: front matrix31";
CM_ SG_ 1012 LS_frontMatrix32 "LS ECU: front matrix32";
CM_ SG_ 1012 LS_frontMatrix33 "LS ECU: front matrix33";
CM_ SG_ 1012 LS_frontMatrix34 "LS ECU: front matrix34";
CM_ SG_ 1012 LS_frontMatrix35 "LS ECU: front matrix35";
CM_ SG_ 1012 LS_frontMatrix36 "LS ECU: front matrix36";
CM_ SG_ 1012 LS_frontMatrix37 "LS ECU: front matrix37";
CM_ SG_ 1012 LS_frontMatrix38 "LS ECU: front matrix38";
CM_ SG_ 1012 LS_frontMatrix39 "LS ECU: front matrix39";
CM_ SG_ 1012 LS_frontMatrix40 "LS ECU: front matrix40";
CM_ SG_ 1012 LS_frontMatrix41 "LS ECU: front matrix41";
CM_ SG_ 1012 LS_frontMatrix42 "LS ECU: front matrix42";
CM_ SG_ 1012 LS_frontMatrix43 "LS ECU: front matrix43";
CM_ SG_ 1012 LS_frontMatrix44 "LS ECU: front matrix44";
CM_ SG_ 1012 LS_frontMatrix45 "LS ECU: front matrix45";
CM_ SG_ 1012 LS_frontMatrix46 "LS ECU: front matrix46";
CM_ SG_ 1012 LS_frontMatrix47 "LS ECU: front matrix47";
CM_ SG_ 1012 LS_frontMatrix48 "LS ECU: front matrix48";
CM_ SG_ 1012 LS_frontMatrix49 "LS ECU: front matrix49";
CM_ SG_ 1012 LS_frontMatrix50 "LS ECU: front matrix50";
CM_ SG_ 1012 LS_frontMatrix51 "LS ECU: front matrix51";
CM_ SG_ 1012 LS_frontMatrix52 "LS ECU: front matrix52";
CM_ SG_ 1012 LS_frontMatrix53 "LS ECU: front matrix53";
CM_ SG_ 1012 LS_frontMatrix54 "LS ECU: front matrix54";
CM_ SG_ 1012 LS_frontMatrix55 "LS ECU: front matrix55";
CM_ SG_ 1012 LS_frontMatrix56 "LS ECU: front matrix56";
CM_ SG_ 1012 LS_frontMatrix57 "LS ECU: front matrix57";
CM_ SG_ 1012 LS_frontMatrix58 "LS ECU: front matrix58";
CM_ SG_ 1012 LS_frontMatrix59 "LS ECU: front matrix59";
CM_ SG_ 1012 LS_rearMatrix0 "LS ECU: rear matrix0";
CM_ SG_ 1012 LS_rearMatrix1 "LS ECU: rear matrix1";
CM_ SG_ 1012 LS_rearMatrix2 "LS ECU: rear matrix2";
CM_ SG_ 1012 LS_rearMatrix3 "LS ECU: rear matrix3";
CM_ SG_ 1012 LS_rearMatrix4 "LS ECU: rear matrix4";
CM_ SG_ 1012 LS_rearMatrix5 "LS ECU: rear matrix5";
CM_ SG_ 1012 LS_rearMatrix6 "LS ECU: rear matrix6";
CM_ SG_ 1012 LS_rearMatrix7 "LS ECU: rear matrix7";
CM_ SG_ 1012 LS_rearMatrix8 "LS ECU: rear matrix8";
CM_ SG_ 1012 LS_rearMatrix9 "LS ECU: rear matrix9";
CM_ SG_ 1012 LS_rearMatrix10 "LS ECU: rear matrix10";
CM_ SG_ 1012 LS_rearMatrix11 "LS ECU: rear matrix11";
CM_ SG_ 1012 LS_rearMatrix12 "LS ECU: rear matrix12";
CM_ SG_ 1012 LS_rearMatrix13 "LS ECU: rear matrix13";
CM_ SG_ 1012 LS_rearMatrix14 "LS ECU: rear matrix14";
CM_ SG_ 1012 LS_rearMatrix15 "LS ECU: rear matrix15";
CM_ SG_ 1012 LS_rearMatrix16 "LS ECU: rear matrix16";
CM_ SG_ 1012 LS_rearMatrix17 "LS ECU: rear matrix17";
CM_ SG_ 1012 LS_rearMatrix18 "LS ECU: rear matrix18";
CM_ SG_ 1012 LS_rearMatrix19 "LS ECU: rear matrix19";
CM_ SG_ 1012 LS_rearMatrix20 "LS ECU: rear matrix20";
CM_ SG_ 1012 LS_rearMatrix21 "LS ECU: rear matrix21";
CM_ SG_ 1012 LS_rearMatrix22 "LS ECU: rear matrix22";
CM_ SG_ 1012 LS_rearMatrix23 "LS ECU: rear matrix23";
CM_ SG_ 1012 LS_rearMatrix24 "LS ECU: rear matrix24";
CM_ SG_ 1012 LS_rearMatrix25 "LS ECU: rear matrix25";
CM_ SG_ 1012 LS_rearMatrix26 "LS ECU: rear matrix26";
CM_ SG_ 1012 LS_rearMatrix27 "LS ECU: rear matrix27";
CM_ SG_ 1012 LS_rearMatrix28 "LS ECU: rear matrix28";
CM_ SG_ 1012 LS_rearMatrix29 "LS ECU: rear matrix29";
CM_ SG_ 1012 LS_rearMatrix30 "LS ECU: rear matrix30";
CM_ SG_ 1012 LS_rearMatrix31 "LS ECU: rear matrix31";
CM_ SG_ 1012 LS_rearMatrix32 "LS ECU: rear matrix32";
CM_ SG_ 1012 LS_rearMatrix33 "LS ECU: rear matrix33";
CM_ SG_ 1012 LS_rearMatrix34 "LS ECU: rear matrix34";
CM_ SG_ 1012 LS_rearMatrix35 "LS ECU: rear matrix35";
CM_ SG_ 1012 LS_rearMatrix36 "LS ECU: rear matrix36";
CM_ SG_ 1012 LS_rearMatrix37 "LS ECU: rear matrix37";
CM_ SG_ 1012 LS_rearMatrix38 "LS ECU: rear matrix38";
CM_ SG_ 1012 LS_rearMatrix39 "LS ECU: rear matrix39";
CM_ SG_ 1012 LS_rearMatrix40 "LS ECU: rear matrix40";
CM_ SG_ 1012 LS_rearMatrix41 "LS ECU: rear matrix41";
CM_ SG_ 1012 LS_rearMatrix42 "LS ECU: rear matrix42";
CM_ SG_ 1012 LS_rearMatrix43 "LS ECU: rear matrix43";
CM_ SG_ 1012 LS_rearMatrix44 "LS ECU: rear matrix44";
CM_ SG_ 1012 LS_rearMatrix45 "LS ECU: rear matrix45";
CM_ SG_ 1012 LS_rearMatrix46 "LS ECU: rear matrix46";
CM_ SG_ 1012 LS_rearMatrix47 "LS ECU: rear matrix47";
CM_ SG_ 1012 LS_rearMatrix48 "LS ECU: rear matrix48";
CM_ SG_ 1012 LS_rearMatrix49 "LS ECU: rear matrix49";
CM_ SG_ 1012 LS_rearMatrix50 "LS ECU: rear matrix50";
CM_ SG_ 1012 LS_rearMatrix51 "LS ECU: rear matrix51";
CM_ SG_ 1012 LS_rearMatrix52 "LS ECU: rear matrix52";
CM_ SG_ 1012 LS_rearMatrix53 "LS ECU: rear matrix53";
CM_ SG_ 1012 LS_rearMatrix54 "LS ECU: rear matrix54";
CM_ SG_ 1012 LS_rearMatrix55 "LS ECU: rear matrix55";
CM_ SG_ 1012 LS_rearMatrix56 "LS ECU: rear matrix56";
CM_ SG_ 1012 LS_rearMatrix57 "LS ECU: rear matrix57";
CM_ SG_ 1012 LS_rearMatrix58 "LS ECU: rear matrix58";
CM_ SG_ 1012 LS_rearMatrix59 "LS ECU: rear matrix59";
CM_ SG_ 1012 LS_offroadLightBar0 "LS ECU: offroad light bar0";
CM_ SG_ 1012 LS_offroadLightBar1 "LS ECU: offroad light bar1";
CM_ SG_ 1012 LS_offroadLightBar2 "LS ECU: offroad light bar2";
CM_ SG_ 1012 LS_offroadLightBar3 "LS ECU: offroad light bar3";
CM_ SG_ 1012 LS_offroadLightBar4 "LS ECU: offroad light bar4";
CM_ SG_ 1012 LS_offroadLightBar5 "LS ECU: offroad light bar5";
CM_ BO_ 612 "Power conversion system (on-board charger and DC-DC converter) message: chg line status; frame length from the layout, not yet observed on a vehicle bus";
CM_ SG_ 612 PCS_chgInputVoltage "RMS value of AC charger's sensed input voltage";
CM_ SG_ 612 PCS_chgLineCurrent "AC charger's sensed input line current";
CM_ SG_ 612 PCS_chgAcVoltagePresent "Indicates whether AC voltage is present on the PCS input";
CM_ SG_ 612 PCS_chgInputPower "Total AC charger input power";
CM_ SG_ 612 PCS_chgAcCurrentLimit "Maximum AC current that can be pulled from a single conductor";
CM_ BO_ 692 "Power conversion system (on-board charger and DC-DC converter) message: dcdc rail status; frame length from the layout, not yet observed on a vehicle bus";
CM_ SG_ 692 PCS_dcdcLvBusVolt "DCDC's sensed LV bus voltage";
CM_ SG_ 692 PCS_dcdcHvBusVolt "DCDC's sensed HV bus voltage";
CM_ SG_ 692 PCS_dcdcLvOutputCurrent "DCDC's computed LV output current";
CM_ BO_ 964 "Power conversion system (on-board charger and DC-DC converter) message: info; frame length from the layout, not yet observed on a vehicle bus";
CM_ SG_ 964 PCS_infoIndex "Power conversion system (on-board charger and DC-DC converter): info index";
CM_ SG_ 964 PCS_buildType "Power conversion system (on-board charger and DC-DC converter): build type";
CM_ SG_ 964 PCS_buildConfigId "Power conversion system (on-board charger and DC-DC converter): build config id";
CM_ SG_ 964 PCS_hardwareId "Power conversion system (on-board charger and DC-DC converter): hardware id";
CM_ SG_ 964 PCS_componentId "Power conversion system (on-board charger and DC-DC converter): component id";
CM_ SG_ 964 PCS_pcbaId "PCBA ID portion of component hardware ID as reported by application";
CM_ SG_ 964 PCS_assemblyId "Power conversion system (on-board charger and DC-DC converter): assembly id";
CM_ SG_ 964 PCS_usageId "Usage ID portion of component hardware ID as reported by application";
CM_ SG_ 964 PCS_subUsageId "Sub-usage ID portion of component hardware ID as reported by application";
CM_ SG_ 964 PCS_platformType "Power conversion system (on-board charger and DC-DC converter): platform type";
CM_ SG_ 964 PCS_appCrc "Power conversion system (on-board charger and DC-DC converter): app crc";
CM_ SG_ 964 PCS_cpu2AppCrc "Power conversion system (on-board charger and DC-DC converter): cpu2 app crc";
CM_ SG_ 964 PCS_appGitHash "Power conversion system (on-board charger and DC-DC converter): app git hash";
CM_ SG_ 964 PCS_bootGitHash "Power conversion system (on-board charger and DC-DC converter): boot git hash";
CM_ SG_ 964 PCS_bootUdsProtoVersion "Power conversion system (on-board charger and DC-DC converter): boot uds proto version";
CM_ SG_ 964 PCS_bootCrc "Power conversion system (on-board charger and DC-DC converter): boot crc";
CM_ BO_ 676 "Power conversion system (on-board charger and DC-DC converter) message: thermal status; frame length from the layout, not yet observed on a vehicle bus";
CM_ SG_ 676 PCS_chgPhATemp "Sensed temperature of AC charger phase A; raw 1025 = signal not available (SNA)";
CM_ SG_ 676 PCS_chgPhBTemp "Sensed temperature of AC charger phase B; raw 1025 = signal not available (SNA)";
CM_ SG_ 676 PCS_chgPhCTemp "Sensed temperature of AC charger phase C; raw 1025 = signal not available (SNA)";
CM_ SG_ 676 PCS_dcdcTemp "Sensed temperature of DCDC; raw 1025 = signal not available (SNA)";
CM_ SG_ 676 PCS_ambientTemp "Ambient temperature sensed by the PCS; raw 1025 = signal not available (SNA)";
CM_ SG_ 676 PCS_dcdcBusbarTemp "Sensed temperature of DCDC busbar; raw 511 = signal not available (SNA)";
CM_ BO_ 790 "PMF ECU message: info; frame length from the layout, not yet observed on a vehicle bus";
CM_ SG_ 790 PMF_infoIndex "PMF ECU: info index";
CM_ SG_ 790 PMF_buildType "PMF ECU: build type";
CM_ SG_ 790 PMF_buildConfigurationId "PMF ECU: build configuration id";
CM_ SG_ 790 PMF_hardwareId "PMF ECU: hardware id";
CM_ SG_ 790 PMF_deviceFused "PMF ECU: device fused";
CM_ SG_ 790 PMF_componentId "PMF ECU: component id";
CM_ SG_ 790 PMF_pcbaId "PMF ECU: pcba id";
CM_ SG_ 790 PMF_assemblyId "PMF ECU: assembly id";
CM_ SG_ 790 PMF_usageId "PMF ECU: usage id";
CM_ SG_ 790 PMF_subUsageId "PMF ECU: sub usage id";
CM_ SG_ 790 PMF_applicationCrc "PMF ECU: application crc";
CM_ SG_ 790 PMF_appGitHash "PMF ECU: app git hash";
CM_ SG_ 790 PMF_bootGitHash "PMF ECU: boot git hash";
CM_ SG_ 790 PMF_platformTyp "PMF ECU: platform typ";
CM_ SG_ 790 PMF_udsProtocolVersion "PMF ECU: uds protocol version";
CM_ SG_ 790 PMF_bootloaderCrc "PMF ECU: bootloader crc";
CM_ BO_ 1748 "PMR ECU message: info; frame length from the layout, not yet observed on a vehicle bus";
CM_ SG_ 1748 PMR_infoIndex "PMR ECU: info index";
CM_ SG_ 1748 PMR_buildType "PMR ECU: build type";
CM_ SG_ 1748 PMR_buildConfigurationId "PMR ECU: build configuration id";
CM_ SG_ 1748 PMR_hardwareId "PMR ECU: hardware id";
CM_ SG_ 1748 PMR_deviceFused "PMR ECU: device fused";
CM_ SG_ 1748 PMR_componentId "PMR ECU: component id";
CM_ SG_ 1748 PMR_pcbaId "PMR ECU: pcba id";
CM_ SG_ 1748 PMR_assemblyId "PMR ECU: assembly id";
CM_ SG_ 1748 PMR_usageId "PMR ECU: usage id";
CM_ SG_ 1748 PMR_subUsageId "PMR ECU: sub usage id";
CM_ SG_ 1748 PMR_applicationCrc "PMR ECU: application crc";
CM_ SG_ 1748 PMR_appGitHash "PMR ECU: app git hash";
CM_ SG_ 1748 PMR_bootGitHash "PMR ECU: boot git hash";
CM_ SG_ 1748 PMR_platformTyp "PMR ECU: platform typ";
CM_ SG_ 1748 PMR_udsProtocolVersion "PMR ECU: uds protocol version";
CM_ SG_ 1748 PMR_bootloaderCrc "PMR ECU: bootloader crc";
CM_ BO_ 1551 "PM ECU message: info; frame length from the layout, not yet observed on a vehicle bus";
CM_ SG_ 1551 PM_infoIndex "PM ECU: info index";
CM_ SG_ 1551 PM_buildType "PM ECU: build type";
CM_ SG_ 1551 PM_buildConfigurationId "PM ECU: build configuration id";
CM_ SG_ 1551 PM_hardwareId "PM ECU: hardware id";
CM_ SG_ 1551 PM_deviceFused "PM ECU: device fused";
CM_ SG_ 1551 PM_componentId "PM ECU: component id";
CM_ SG_ 1551 PM_pcbaId "PM ECU: pcba id";
CM_ SG_ 1551 PM_assemblyId "PM ECU: assembly id";
CM_ SG_ 1551 PM_usageId "PM ECU: usage id";
CM_ SG_ 1551 PM_subUsageId "PM ECU: sub usage id";
CM_ SG_ 1551 PM_applicationCrc "PM ECU: application crc";
CM_ SG_ 1551 PM_bootGitHash "PM ECU: boot git hash";
CM_ BO_ 1766 "PNCD ECU message: iso tp pipe to cp; forwarded onto this bus by the gateway; frame length from the layout, not yet observed on a vehicle bus";
CM_ SG_ 1766 PNCD_isoTpToCpData "PNCD ECU: iso tp to cp data";
CM_ BO_ 837 "Cabin heater message: info; frame length from the layout, not yet observed on a vehicle bus";
CM_ SG_ 837 PTC_infoIndex "Cabin heater: info index";
CM_ SG_ 837 PTC_infoBuildType "Cabin heater: info build type";
CM_ SG_ 837 PTC_infoBuildConfigId "Cabin heater: info build config id";
CM_ SG_ 837 PTC_infoHardwareId "Cabin heater: info hardware id";
CM_ SG_ 837 PTC_infoComponentId "Cabin heater: info component id";
CM_ SG_ 837 PTC_infoPcbaId "Cabin heater: info pcba id";
CM_ SG_ 837 PTC_infoAssemblyId "Cabin heater: info assembly id; raw 255 = signal not available (SNA)";
CM_ SG_ 837 PTC_infoUsageId "Cabin heater: info usage id";
CM_ SG_ 837 PTC_infoSubUsageId "Cabin heater: info sub usage id";
CM_ SG_ 837 PTC_infoPlatformType "Cabin heater: info platform type";
CM_ SG_ 837 PTC_infoAppCrc "Cabin heater: info app crc";
CM_ SG_ 837 PTC_infoBootUdsProtoVersion "Cabin heater: info boot uds proto version";
CM_ SG_ 837 PTC_infoBootCrc "Cabin heater: info boot crc";
CM_ BO_ 647 "Cabin heater message: sensor status; frame length from the layout, not yet observed on a vehicle bus";
CM_ SG_ 647 PTC_leftTempIGBT "Heater left bank IGBT temperature";
CM_ SG_ 647 PTC_tempOCP "Temperature measured near the over current protection circuit";
CM_ SG_ 647 PTC_rightTempIGBT "Heater right bank IGBT temperature";
CM_ SG_ 647 PTC_tempPCB "Heater printed circuit board temperature";
CM_ SG_ 647 PTC_voltageHV "Heater high voltage input voltage";
CM_ SG_ 647 PTC_leftCurrentHV "Cabin heater: left current HV";
CM_ SG_ 647 PTC_rightCurrentHV "Cabin heater: right current HV";
CM_ BO_ 1359 "Steering column control module message: alert matrix; frame length from the layout, not yet observed on a vehicle bus";
CM_ SG_ 1359 SCCM_matrixIndex "Steering column control module: matrix index";
CM_ SG_ 1359 SCCM_a001_CANBusOff "Steering column control module: a001 CAN bus off";
CM_ SG_ 1359 SCCM_a002_CANTOut "Steering column control module: a002 CANT out";
CM_ SG_ 1359 SCCM_a003_highBeamOpen "Steering column control module: a003 high beam open";
CM_ SG_ 1359 SCCM_a004_highBeamShortToGND "Steering column control module: a004 high beam short to GND";
CM_ SG_ 1359 SCCM_a005_tipWipeOpen "Steering column control module: a005 tip wipe open";
CM_ SG_ 1359 SCCM_a006_tipWipeShortToGND "Steering column control module: a006 tip wipe short to GND";
CM_ SG_ 1359 SCCM_a007_turnIndComInfo "Steering column control module: a007 turn ind com info";
CM_ SG_ 1359 SCCM_a008_turnIndInvalidTrans "Steering column control module: a008 turn ind invalid trans";
CM_ SG_ 1359 SCCM_a009_turnIndOpen "Steering column control module: a009 turn ind open";
CM_ SG_ 1359 SCCM_a010_turnIndShortToGnd "Steering column control module: a010 turn ind short to gnd";
CM_ SG_ 1359 SCCM_a011_turnIndHWErr "Steering column control module: a011 turn ind HW err";
CM_ SG_ 1359 SCCM_a012_turnGenErr "Steering column control module: a012 turn gen err";
CM_ SG_ 1359 SCCM_a013_voltageHigh "Steering column control module: a013 voltage high";
CM_ SG_ 1359 SCCM_a014_voltageLow "Steering column control module: a014 voltage low";
CM_ SG_ 1359 SCCM_a015_softwareError "Steering column control module: a015 software error";
CM_ SG_ 1359 SCCM_a016_hardwareError "Steering column control module: a016 hardware error";
CM_ SG_ 1359 SCCM_a017_memoryError "Steering column control module: a017 memory error";
CM_ SG_ 1359 SCCM_a018_angleSpeedOutOfRange "Steering column control module: a018 angle speed out of range";
CM_ SG_ 1359 SCCM_a019_angleOutOfRange "Steering column control module: a019 angle out of range";
CM_ SG_ 1359 SCCM_a020_angleInternalError "Steering column control module: a020 angle internal error";
CM_ SG_ 1359 SCCM_a021_gearStalkSignalInvalid "Steering column control module: a021 gear stalk signal invalid";
CM_ SG_ 1359 SCCM_a022_gearStalkOpenCircuit "Steering column control module: a022 gear stalk open circuit";
CM_ SG_ 1359 SCCM_a023_gearStalkShortCircuit "Steering column control module: a023 gear stalk short circuit";
CM_ SG_ 1359 SCCM_a024_gearStalkGenErr "Steering column control module: a024 gear stalk gen err";
CM_ SG_ 1359 SCCM_a025_runTimeError "Steering column control module: a025 run time error";
CM_ SG_ 1359 SCCM_a026_parkButtonInvalidSigna "Steering column control module: a026 park button invalid signal";
CM_ SG_ 1359 SCCM_a027_parkButtonOpenCircuit "Steering column control module: a027 park button open circuit";
CM_ SG_ 1359 SCCM_a028_parkButtonShortToGroun "Steering column control module: a028 park button short to ground";
CM_ SG_ 1359 SCCM_a029_parkButtonMalfunction "Steering column control module: a029 park button malfunction";
CM_ SG_ 1359 SCCM_a061_voltageHigh_2 "Steering column control module: a061 voltage high 2";
CM_ SG_ 1359 SCCM_a062_voltageLow_2 "Steering column control module: a062 voltage low 2";
CM_ SG_ 1359 SCCM_a063_angleOutOfRange_2 "Steering column control module: a063 angle out of range 2";
CM_ SG_ 1359 SCCM_a064_angleSpeedOutOfRange_2 "Steering column control module: a064 angle speed out of range 2";
CM_ SG_ 1359 SCCM_a065_angleNotPlausible "Steering column control module: a065 angle not plausible";
CM_ SG_ 1359 SCCM_a066_angleSpeedNotPlausible "Steering column control module: a066 angle speed not plausible";
CM_ SG_ 1359 SCCM_a067_CANBusOff_2 "Steering column control module: a067 CAN bus off 2";
CM_ SG_ 1359 SCCM_a068_CANLVPowerState_LOC "Steering column control module: a068 CANLV power state LOC";
CM_ SG_ 1359 SCCM_a069_calibrationMismatch "Steering column control module: a069 calibration mismatch";
CM_ SG_ 1359 SCCM_a070_angleTrimMismatch "Steering column control module: a070 angle trim mismatch";
CM_ SG_ 1359 SCCM_a071_angleHallSensorError "Steering column control module: a071 angle hall sensor error";
CM_ SG_ 1359 SCCM_a072_spiBitErrors "Steering column control module: a072 spi bit errors";
CM_ SG_ 1359 SCCM_a073_watchdogReset "Steering column control module: a073 watchdog reset";
CM_ SG_ 1359 SCCM_a074_PLLLossOfLock "Steering column control module: a074 PLL loss of lock";
CM_ SG_ 1359 SCCM_a075_hardwareError_2 "Steering column control module: a075 hardware error 2";
CM_ SG_ 1359 SCCM_a076_memoryError_2 "Steering column control module: a076 memory error 2";
CM_ SG_ 1359 SCCM_a077_gearAngleNotPlausible "Steering column control module: a077 gear angle not plausible";
CM_ SG_ 1359 SCCM_a078_ADCCalibrationError "Steering column control module: a078 ADC calibration error";
CM_ SG_ 1359 SCCM_a079_chipTempOutOfRange "Steering column control module: a079 chip temp out of range";
CM_ SG_ 1359 SCCM_a080_ADCSelfTestFailed "Steering column control module: a080 ADC self test failed";
CM_ SG_ 1359 SCCM_a081_startupTestFailed "Steering column control module: a081 startup test failed";
CM_ SG_ 1359 SCCM_a082_runtimeTestFailed "Steering column control module: a082 runtime test failed";
CM_ SG_ 1359 SCCM_a121_turnIndicatorAngleInva "Steering column control module: a121 turn indicator angle invalid";
CM_ SG_ 1359 SCCM_a122_turnIndicatorSpeedInva "Steering column control module: a122 turn indicator speed invalid";
CM_ SG_ 1359 SCCM_a123_turnIndicatorStuckActi "Steering column control module: a123 turn indicator stuck active";
CM_ SG_ 1359 SCCM_a124_turnIndicatorIdleInval "Steering column control module: a124 turn indicator idle invalid";
CM_ SG_ 1359 SCCM_a125_turnIndicatorHallAngle "Steering column control module: a125 turn indicator hall angle mismatch";
CM_ SG_ 1359 SCCM_a126_turnIndicatorHallMagOu "Steering column control module: a126 turn indicator hall mag out of range";
CM_ BO_ 816 "Steering column control module message: info; frame length from the layout, not yet observed on a vehicle bus";
CM_ SG_ 816 SCCM_infoIndex "Steering column control module: info index";
CM_ SG_ 816 SCCM_infoBuildType "Steering column control module: info build type";
CM_ SG_ 816 SCCM_infoBuildConfigId "Steering column control module: info build config id";
CM_ SG_ 816 SCCM_infoHardwareId "Steering column control module: info hardware id";
CM_ SG_ 816 SCCM_infoComponentId "Steering column control module: info component id";
CM_ SG_ 816 SCCM_infoPcbaId "Steering column control module: info pcba id";
CM_ SG_ 816 SCCM_infoAssemblyId "Steering column control module: info assembly id";
CM_ SG_ 816 SCCM_infoUsageId "Steering column control module: info usage id";
CM_ SG_ 816 SCCM_infoSubUsageId "Steering column control module: info sub usage id";
CM_ SG_ 816 SCCM_infoPlatformType "Steering column control module: info platform type";
CM_ SG_ 816 SCCM_infoAppCrc "Steering column control module: info app crc";
CM_ SG_ 816 SCCM_infoBootSvnRev "Steering column control module: info boot svn rev";
CM_ SG_ 816 SCCM_infoBootSvnUrlHash "Steering column control module: info boot svn url hash";
CM_ SG_ 816 SCCM_infoSubcomponent1Version "Steering column control module: info subcomponent1 version";
CM_ SG_ 816 SCCM_infoAppSvnHash "Steering column control module: info app svn hash";
CM_ SG_ 816 SCCM_infoBootSvnHash "Steering column control module: info boot svn hash";
CM_ SG_ 816 SCCM_infoUdsProtoVersion "Steering column control module: info uds proto version";
CM_ SG_ 816 SCCM_infoBootCrc "Steering column control module: info boot crc";
CM_ BO_ 585 "Steering column control module message: left stalk; frame length from the layout, not yet observed on a vehicle bus";
CM_ SG_ 585 SCCM_leftStalkCrc "Steering column control module: left stalk crc";
CM_ SG_ 585 SCCM_leftStalkCounter "Steering column control module: left stalk counter";
CM_ SG_ 585 SCCM_highBeamStalkStatus "Active state of high beam push/pull stalk position; raw 3 = signal not available (SNA)";
CM_ SG_ 585 SCCM_washWipeButtonStatus "Active state of wash/wipe button on the turn signal stalk; raw 3 = signal not available (SNA)";
CM_ SG_ 585 SCCM_turnIndicatorStalkStatus "Active state of turn indicator stalk position; raw 9 = signal not available (SNA)";
CM_ SG_ 585 SCCM_turnIndicatorStalkAngle "Measured angle of the turn signal stalk; raw 4095 = signal not available (SNA)";
CM_ BO_ 553 "Steering column control module message: right stalk; frame length from the layout, not yet observed on a vehicle bus";
CM_ SG_ 553 SCCM_rightStalkCrc "Steering column control module: right stalk crc";
CM_ SG_ 553 SCCM_rightStalkCounter "Steering column control module: right stalk counter";
CM_ SG_ 553 SCCM_rightStalkStatus "Active state of drive stalk position, does not indicate active drive gear; raw 6 = signal not available (SNA)";
CM_ SG_ 553 SCCM_rightStalkReserved1 "Steering column control module: right stalk reserved1";
CM_ SG_ 553 SCCM_parkButtonStatus "Active state of park button on the drive stalk; raw 3 = signal not available (SNA)";
CM_ SG_ 553 SCCM_rightStalkReserved2 "Steering column control module: right stalk reserved2";
CM_ BO_ 297 "Steering column control module message: steering angle sensor; frame length from the layout, not yet observed on a vehicle bus";
CM_ SG_ 297 SCCM_steeringAngleCrc "Steering column control module: steering angle crc";
CM_ SG_ 297 SCCM_steeringAngleCounter "Message counter";
CM_ SG_ 297 SCCM_supplierID "Steering column control module: supplier ID";
CM_ SG_ 297 SCCM_steeringAngleSensorStatus "Reports steering angle sensor status and validity based on bootup checks";
CM_ SG_ 297 SCCM_steeringAngle "Measured ASAS sensor angle; raw 16383 = signal not available (SNA)";
CM_ SG_ 297 SCCM_steeringAngleValidity "Transitions to VALID when rotation of over 4 deg has occurred; raw 3 = signal not available (SNA)";
CM_ SG_ 297 SCCM_steeringAngleSpeed "Speed of steering angle rotation";
CM_ SG_ 297 SCCM_steeringAngleSensorReservd1 "Steering column control module: steering angle sensor reservd1";
CM_ SG_ 297 SCCM_steeringAngleSensorReservd2 "Steering column control module: steering angle sensor reservd2";
CM_ SG_ 297 SCCM_steeringAngleSensorReservd3 "Steering column control module: steering angle sensor reservd3";
CM_ BO_ 1356 "SCM ECU message: alert log; frame length from the layout, not yet observed on a vehicle bus";
CM_ SG_ 1356 SCM_alertID "SCM ECU: alert ID";
CM_ SG_ 1356 SCM_alertType "SCM ECU: alert type";
CM_ SG_ 1356 SCM_a074_voltageWithRo "SCM ECU: a074 voltage with ro";
CM_ SG_ 1356 SCM_a074_voltageWithoutRo "SCM ECU: a074 voltage without ro";
CM_ BO_ 815 "SCM ECU message: alert matrix1; frame length from the layout, not yet observed on a vehicle bus";
CM_ SG_ 815 SCM_a027_externalIsolationLow "SCM ECU: a027 external isolation low";
CM_ SG_ 815 SCM_a044_proximityRationality "SCM ECU: a044 proximity rationality";
CM_ BO_ 1355 "SCM ECU message: alert matrix2; frame length from the layout, not yet observed on a vehicle bus";
CM_ SG_ 1355 SCM_a074_isoVDiffHi "SCM ECU: a074 iso v diff hi";
CM_ SG_ 1355 SCM_a076_bmsMIA "SCM ECU: a076 bms MIA";
CM_ SG_ 1355 SCM_a078_voltageMatchTimeout "SCM ECU: a078 voltage match timeout";
CM_ SG_ 1355 SCM_a091_voltageRiseDetection "SCM ECU: a091 voltage rise detection";
CM_ BO_ 1354 "SCS ECU message: alert log; frame length from the layout, not yet observed on a vehicle bus";
CM_ SG_ 1354 SCS_alertID "SCS ECU: alert ID";
CM_ SG_ 1354 SCS_alertType "SCS ECU: alert type";
CM_ SG_ 1354 SCS_a044_proximityV "SCS ECU: a044 proximity v";
CM_ SG_ 1354 SCS_a074_voltageWithRo "SCS ECU: a074 voltage with ro";
CM_ SG_ 1354 SCS_a074_voltageWithoutRo "SCS ECU: a074 voltage without ro";
CM_ BO_ 869 "SCS ECU message: alert matrix1; frame length from the layout, not yet observed on a vehicle bus";
CM_ SG_ 869 SCS_a001_hwDSPfault "SCS ECU: a001 hw DS pfault";
CM_ SG_ 869 SCS_a002_hwIbatOC "SCS ECU: a002 hw ibat OC";
CM_ SG_ 869 SCS_a003_hwCordOT "SCS ECU: a003 hw cord OT";
CM_ SG_ 869 SCS_a004_hwVbusOV "SCS ECU: a004 hw vbus OV";
CM_ SG_ 869 SCS_a005_hwHVIL "SCS ECU: a005 hw HVIL";
CM_ SG_ 869 SCS_a006_hwWeld_V1 "SCS ECU: a006 hw weld V1";
CM_ SG_ 869 SCS_a007_hwWeld_V2 "SCS ECU: a007 hw weld V2";
CM_ SG_ 869 SCS_a008_hwIllegalCntrShoot "SCS ECU: a008 hw illegal cntr shoot";
CM_ SG_ 869 SCS_a009_hwOpen_V1 "SCS ECU: a009 hw open V1";
CM_ SG_ 869 SCS_a010_hwOpen_V2 "SCS ECU: a010 hw open V2";
CM_ SG_ 869 SCS_a011_hwIllegalCntrCmdV1 "SCS ECU: a011 hw illegal cntr cmd V1";
CM_ SG_ 869 SCS_a012_hwIllegalCntrCmdV2 "SCS ECU: a012 hw illegal cntr cmd V2";
CM_ SG_ 869 SCS_a013_cordTempHiFoldBk "SCS ECU: a013 cord temp hi fold bk";
CM_ SG_ 869 SCS_a014_coolantTempHiFoldBk "SCS ECU: a014 coolant temp hi fold bk";
CM_ SG_ 869 SCS_a015_cpldRationality "SCS ECU: a015 cpld rationality";
CM_ SG_ 869 SCS_a016_unusedHW16 "SCS ECU: a016 unused HW16";
CM_ SG_ 869 SCS_a017_unusedHW17 "SCS ECU: a017 unused HW17";
CM_ SG_ 869 SCS_a018_unusedHW18 "SCS ECU: a018 unused HW18";
CM_ SG_ 869 SCS_a019_unusedHW19 "SCS ECU: a019 unused HW19";
CM_ SG_ 869 SCS_a020_unusedHW20 "SCS ECU: a020 unused HW20";
CM_ SG_ 869 SCS_a021_unusedHW21 "SCS ECU: a021 unused HW21";
CM_ SG_ 869 SCS_a024_emergencyShutdown "SCS ECU: a024 emergency shutdown";
CM_ SG_ 869 SCS_a025_internalIsolationFault "SCS ECU: a025 internal isolation fault";
CM_ SG_ 869 SCS_a026_internalIsolationLow "SCS ECU: a026 internal isolation low";
CM_ SG_ 869 SCS_a027_externalIsolationLow "SCS ECU: a027 external isolation low";
CM_ SG_ 869 SCS_a028_isolationRationality "SCS ECU: a028 isolation rationality";
CM_ SG_ 869 SCS_a029_VbatOV "SCS ECU: a029 vbat OV";
CM_ SG_ 869 SCS_a030_VbusOV "SCS ECU: a030 vbus OV";
CM_ SG_ 869 SCS_a031_IbatOC "SCS ECU: a031 ibat OC";
CM_ SG_ 869 SCS_a032_VBatRationality "SCS ECU: a032 v bat rationality";
CM_ SG_ 869 SCS_a033_VBusRationality "SCS ECU: a033 v bus rationality";
CM_ SG_ 869 SCS_a034_IBatRationality "SCS ECU: a034 i bat rationality";
CM_ SG_ 869 SCS_a035_unexpectedVbusBehavior "SCS ECU: a035 unexpected vbus behavior";
CM_ SG_ 869 SCS_a036_internalContactorWelded "SCS ECU: a036 internal contactor welded";
CM_ SG_ 869 SCS_a037_outputContactorWelded "SCS ECU: a037 output contactor welded";
CM_ SG_ 869 SCS_a038_contactorFailedOpen "SCS ECU: a038 contactor failed open";
CM_ SG_ 869 SCS_a039_ibatRegulation "SCS ECU: a039 ibat regulation";
CM_ SG_ 869 SCS_a040_plus12VOutOfRange "SCS ECU: a040 plus12 v out of range";
CM_ SG_ 869 SCS_a041_minus12VOutOfRange "SCS ECU: a041 minus12 v out of range";
CM_ SG_ 869 SCS_a042_pilotOutOfRange "SCS ECU: a042 pilot out of range";
CM_ SG_ 869 SCS_a043_pilotRationality "SCS ECU: a043 pilot rationality";
CM_ SG_ 869 SCS_a044_proximityRationality "SCS ECU: a044 proximity rationality";
CM_ SG_ 869 SCS_a045_pcbaOT "SCS ECU: a045 pcba OT";
CM_ SG_ 869 SCS_a046_coolantOT "SCS ECU: a046 coolant OT";
CM_ SG_ 869 SCS_a047_cordOT "SCS ECU: a047 cord OT";
CM_ SG_ 869 SCS_a048_ambientOT "SCS ECU: a048 ambient OT";
CM_ SG_ 869 SCS_a049_pcbaTempRationality "SCS ECU: a049 pcba temp rationality";
CM_ SG_ 869 SCS_a050_coolantTempRationality "SCS ECU: a050 coolant temp rationality";
CM_ SG_ 869 SCS_a051_cordTempRationality "SCS ECU: a051 cord temp rationality";
CM_ SG_ 869 SCS_a052_ambientTempRationality "SCS ECU: a052 ambient temp rationality";
CM_ SG_ 869 SCS_a053_unexpectedThermalBehavi "SCS ECU: a053 unexpected thermal behavi";
CM_ SG_ 869 SCS_a054_pumpRegulation "SCS ECU: a054 pump regulation";
CM_ SG_ 869 SCS_a055_coolantLevelLow "SCS ECU: a055 coolant level low";
CM_ SG_ 869 SCS_a056_stateTransitionDenied "SCS ECU: a056 state transition denied";
CM_ SG_ 869 SCS_a057_watchdogReset "SCS ECU: a057 watchdog reset";
CM_ SG_ 869 SCS_a058_adcRef "SCS ECU: a058 adc ref";
CM_ SG_ 869 SCS_a059_memoryError "SCS ECU: a059 memory error";
CM_ SG_ 869 SCS_a060_swHVIL "SCS ECU: a060 sw HVIL";
CM_ SG_ 869 SCS_a061_postOutOfService "SCS ECU: a061 post out of service";
CM_ SG_ 869 SCS_a062_unused "SCS ECU: a062 unused";
CM_ SG_ 869 SCS_a063_canRationality "SCS ECU: a063 can rationality";
CM_ SG_ 869 SCS_a064_vehicleCommandTimeout "SCS ECU: a064 vehicle command timeout";
CM_ BO_ 880 "SCS ECU message: alert matrix2; frame length from the layout, not yet observed on a vehicle bus";
CM_ SG_ 880 SCS_a065_vBatRationalityStage1 "SCS ECU: a065 v bat rationality stage1";
CM_ SG_ 880 SCS_a066_vBatRationalityStage2 "SCS ECU: a066 v bat rationality stage2";
CM_ SG_ 880 SCS_a067_vBatRationalityStage3 "SCS ECU: a067 v bat rationality stage3";
CM_ SG_ 880 SCS_a068_vBatRationalityStage4 "SCS ECU: a068 v bat rationality stage4";
CM_ SG_ 880 SCS_a069_vStageRationalityV1 "SCS ECU: a069 v stage rationality V1";
CM_ SG_ 880 SCS_a070_vStageRationalityV2 "SCS ECU: a070 v stage rationality V2";
CM_ SG_ 880 SCS_a071_chargerMIA "SCS ECU: a071 charger MIA";
CM_ SG_ 880 SCS_a072_gtwMIA "SCS ECU: a072 gtw MIA";
CM_ SG_ 880 SCS_a073_lccMIA "SCS ECU: a073 lcc MIA";
CM_ SG_ 880 SCS_a074_isoVDiffHi "SCS ECU: a074 iso v diff hi";
CM_ SG_ 880 SCS_a075_unused75 "SCS ECU: a075 unused75";
CM_ SG_ 880 SCS_a076_bmsMIA "SCS ECU: a076 bms MIA";
CM_ SG_ 880 SCS_a077_unexpectedVbatBehavior "SCS ECU: a077 unexpected vbat behavior";
CM_ SG_ 880 SCS_a078_voltageMatchTimeout "SCS ECU: a078 voltage match timeout";
CM_ SG_ 880 SCS_a079_unexpectedVbat "SCS ECU: a079 unexpected vbat";
CM_ SG_ 880 SCS_a080_lccFaulted "SCS ECU: a080 lcc faulted";
CM_ SG_ 880 SCS_a081_rmsInputVoltageHigh "SCS ECU: a081 rms input voltage high";
CM_ SG_ 880 SCS_a082_VbatUV "SCS ECU: a082 vbat UV";
CM_ SG_ 880 SCS_a083_chargeCurrentLimited "SCS ECU: a083 charge current limited";
CM_ SG_ 880 SCS_a084_unused84 "SCS ECU: a084 unused84";
CM_ SG_ 880 SCS_a085_unused85 "SCS ECU: a085 unused85";
CM_ SG_ 880 SCS_a086_lccResetDetected "SCS ECU: a086 lcc reset detected";
CM_ SG_ 880 SCS_a087_posCordTempRationality "SCS ECU: a087 pos cord temp rationality";
CM_ SG_ 880 SCS_a088_negCordTempRationality "SCS ECU: a088 neg cord temp rationality";
CM_ SG_ 880 SCS_a089_posCordOT "SCS ECU: a089 pos cord OT";
CM_ SG_ 880 SCS_a090_negCordOT "SCS ECU: a090 neg cord OT";
CM_ SG_ 880 SCS_a091_voltageRiseDetection "SCS ECU: a091 voltage rise detection";
CM_ SG_ 880 SCS_a092_cabEnableDeasserted "SCS ECU: a092 cab enable deasserted";
CM_ SG_ 880 SCS_a093_unused93 "SCS ECU: a093 unused93";
CM_ SG_ 880 SCS_a094_unused94 "SCS ECU: a094 unused94";
CM_ SG_ 880 SCS_a095_unused95 "SCS ECU: a095 unused95";
CM_ SG_ 880 SCS_a096_unused96 "SCS ECU: a096 unused96";
CM_ SG_ 880 SCS_a097_unused97 "SCS ECU: a097 unused97";
CM_ SG_ 880 SCS_a098_unused98 "SCS ECU: a098 unused98";
CM_ SG_ 880 SCS_a099_unused99 "SCS ECU: a099 unused99";
CM_ SG_ 880 SCS_a100_unused100 "SCS ECU: a100 unused100";
CM_ SG_ 880 SCS_a101_unused101 "SCS ECU: a101 unused101";
CM_ SG_ 880 SCS_a102_unused102 "SCS ECU: a102 unused102";
CM_ SG_ 880 SCS_a103_unused103 "SCS ECU: a103 unused103";
CM_ SG_ 880 SCS_a104_unused104 "SCS ECU: a104 unused104";
CM_ SG_ 880 SCS_a105_unused105 "SCS ECU: a105 unused105";
CM_ SG_ 880 SCS_a106_unused106 "SCS ECU: a106 unused106";
CM_ SG_ 880 SCS_a107_unused107 "SCS ECU: a107 unused107";
CM_ SG_ 880 SCS_a108_unused108 "SCS ECU: a108 unused108";
CM_ SG_ 880 SCS_a109_unused109 "SCS ECU: a109 unused109";
CM_ SG_ 880 SCS_a110_unused110 "SCS ECU: a110 unused110";
CM_ SG_ 880 SCS_a111_unused111 "SCS ECU: a111 unused111";
CM_ SG_ 880 SCS_a112_unused112 "SCS ECU: a112 unused112";
CM_ SG_ 880 SCS_a113_unused113 "SCS ECU: a113 unused113";
CM_ SG_ 880 SCS_a114_unused114 "SCS ECU: a114 unused114";
CM_ SG_ 880 SCS_a115_unused115 "SCS ECU: a115 unused115";
CM_ SG_ 880 SCS_a116_unused116 "SCS ECU: a116 unused116";
CM_ SG_ 880 SCS_a117_unused117 "SCS ECU: a117 unused117";
CM_ SG_ 880 SCS_a118_unused118 "SCS ECU: a118 unused118";
CM_ SG_ 880 SCS_a119_unused119 "SCS ECU: a119 unused119";
CM_ SG_ 880 SCS_a120_unused120 "SCS ECU: a120 unused120";
CM_ SG_ 880 SCS_a121_unused121 "SCS ECU: a121 unused121";
CM_ SG_ 880 SCS_a122_unused122 "SCS ECU: a122 unused122";
CM_ SG_ 880 SCS_a123_unused123 "SCS ECU: a123 unused123";
CM_ SG_ 880 SCS_a124_unused124 "SCS ECU: a124 unused124";
CM_ SG_ 880 SCS_a125_unused125 "SCS ECU: a125 unused125";
CM_ SG_ 880 SCS_a126_unused126 "SCS ECU: a126 unused126";
CM_ SG_ 880 SCS_a127_unused127 "SCS ECU: a127 unused127";
CM_ SG_ 880 SCS_a128_unused128 "SCS ECU: a128 unused128";
CM_ BO_ 1467 "SDCR ECU message: alert matrix; frame length from the layout, not yet observed on a vehicle bus";
CM_ SG_ 1467 SDCR_matrixIndex "SDCR ECU: matrix index";
CM_ SG_ 1467 SDCR_a001_powerOnSelfTestFailed "SDCR ECU: a001 power on self test failed";
CM_ SG_ 1467 SDCR_a002_diPstSkipped "SDCR ECU: a002 di pst skipped";
CM_ SG_ 1467 SDCR_a003_diUartMIA "SDCR ECU: a003 di uart MIA";
CM_ SG_ 1467 SDCR_a004_pmRunningFdbkIrrationa "SDCR ECU: a004 pm running fdbk irrational";
CM_ SG_ 1467 SDCR_a005_motorSpeedIrrational "SDCR ECU: a005 motor speed irrational";
CM_ SG_ 1467 SDCR_a006_pyroTriggered "SDCR ECU: a006 pyro triggered";
CM_ SG_ 1467 SDCR_a007_faultCurrentsDetected "SDCR ECU: a007 fault currents detected";
CM_ SG_ 1467 SDCR_a008_hvlinkMIA "SDCR ECU: a008 hvlink MIA";
CM_ SG_ 1467 SDCR_a009_uartVersionMismatch "SDCR ECU: a009 uart version mismatch";
CM_ SG_ 1467 SDCR_a010_vrefIrrational "SDCR ECU: a010 vref irrational";
CM_ SG_ 1467 SDCR_a011_phaseCurrentOffset "SDCR ECU: a011 phase current offset";
CM_ SG_ 1467 SDCR_a012_vBoostSecIrrational "SDCR ECU: a012 v boost sec irrational";
CM_ SG_ 1467 SDCR_a013_vBkupIrrational "SDCR ECU: a013 v bkup irrational";
CM_ SG_ 1467 SDCR_a014_vBusIrrational "SDCR ECU: a014 v bus irrational";
CM_ SG_ 1467 SDCR_a015_phaseVIrrational "SDCR ECU: a015 phase v irrational";
CM_ SG_ 1467 SDCR_a016_systemReset "SDCR ECU: a016 system reset";
CM_ SG_ 1467 SDCR_a017_adcSPIError "SDCR ECU: a017 adc SPI error";
CM_ SG_ 1467 SDCR_a018_historicalPyroTrigger "SDCR ECU: a018 historical pyro trigger";
CM_ SG_ 1467 SDCR_a019_historicalFaultCurrent "SDCR ECU: a019 historical fault currents";
CM_ SG_ 1467 SDCR_a020_eepromSPIError "SDCR ECU: a020 eeprom SPI error";
CM_ SG_ 1467 SDCR_a021_busBarTempIrrational "SDCR ECU: a021 bus bar temp irrational";
CM_ SG_ 1467 SDCR_a022_TaskInitError "SDCR ECU: a022 task init error";
CM_ SG_ 1467 SDCR_a023_ecuLogAvailable "SDCR ECU: a023 ecu log available";
CM_ SG_ 1467 SDCR_a024_gtwMIA "SDCR ECU: a024 gtw MIA";
CM_ SG_ 1467 SDCR_a025_diSwitchingFdbkIrratio "SDCR ECU: a025 di switching fdbk irrational";
CM_ SG_ 1467 SDCR_a026_faultCurrentMonitoring "SDCR ECU: a026 fault current monitoring disabled";
CM_ SG_ 1467 SDCR_a027_diCanMIA "SDCR ECU: a027 di can MIA";
CM_ SG_ 1467 SDCR_a028_vcLVStateMIA "SDCR ECU: a028 vc LV state MIA";
CM_ SG_ 1467 SDCR_a029_diMIA "SDCR ECU: a029 di MIA";
CM_ SG_ 1467 SDCR_a030_placeholder30 "SDCR ECU: a030 placeholder30";
CM_ SG_ 1467 SDCR_a031_placeholder31 "SDCR ECU: a031 placeholder31";
CM_ SG_ 1467 SDCR_a032_placeholder32 "SDCR ECU: a032 placeholder32";
CM_ SG_ 1467 SDCR_a033_placeholder33 "SDCR ECU: a033 placeholder33";
CM_ SG_ 1467 SDCR_a034_phaseCurrentIrrational "SDCR ECU: a034 phase current irrational";
CM_ BO_ 1597 "SDCR ECU message: info; frame length from the layout, not yet observed on a vehicle bus";
CM_ SG_ 1597 SDCR_infoIndex "SDCR ECU: info index";
CM_ SG_ 1597 SDCR_infoBuildType "SDCR ECU: info build type";
CM_ SG_ 1597 SDCR_infoBuildConfigId "SDCR ECU: info build config id";
CM_ SG_ 1597 SDCR_infoHardwareId "SDCR ECU: info hardware id";
CM_ SG_ 1597 SDCR_infoComponentId "SDCR ECU: info component id";
CM_ SG_ 1597 SDCR_infoPcbaId "SDCR ECU: info pcba id";
CM_ SG_ 1597 SDCR_infoAssemblyId "SDCR ECU: info assembly id";
CM_ SG_ 1597 SDCR_infoUsageId "SDCR ECU: info usage id";
CM_ SG_ 1597 SDCR_infoSubUsageId "SDCR ECU: info sub usage id";
CM_ SG_ 1597 SDCR_infoAppCrc "SDCR ECU: info app crc";
CM_ SG_ 1597 SDCR_infoBootGitHash "SDCR ECU: info boot git hash";
CM_ BO_ 792 "Vector__XXX ECU message: system time UTC; frame length observed on a vehicle bus";
CM_ SG_ 792 UTC_year "UTC date: year";
CM_ SG_ 792 UTC_month "UTC date: month";
CM_ SG_ 792 UTC_seconds "UTC time: seconds";
CM_ SG_ 792 UTC_hour "UTC time: hour";
CM_ SG_ 792 UTC_day "UTC date: day of month";
CM_ SG_ 792 UTC_minutes "UTC time: minutes";
CM_ BO_ 523 "Air suspension controller message: axle data; frame length from the layout, not yet observed on a vehicle bus";
CM_ SG_ 523 TAS_axleIndex "Air suspension controller: axle index";
CM_ SG_ 523 TAS_rawHeightFL "Current height of the FL air spring; raw 1023 = signal not available (SNA)";
CM_ SG_ 523 TAS_staticHeightEstimateFL "Current static height estimate of the FL air spring; raw 1023 = signal not available (SNA)";
CM_ SG_ 523 TAS_componentPressureFL "Current static pressure of the FL air spring; raw 255 = signal not available (SNA)";
CM_ SG_ 523 TAS_rawHeightFR "Current height of the FR air spring; raw 1023 = signal not available (SNA)";
CM_ SG_ 523 TAS_staticHeightEstimateFR "Current static height estimate of the FR air spring; raw 1023 = signal not available (SNA)";
CM_ SG_ 523 TAS_componentPressureFR "Current static pressure of the FR air spring; raw 255 = signal not available (SNA)";
CM_ SG_ 523 TAS_rawHeightRL "Current height of the RL air spring; raw 1023 = signal not available (SNA)";
CM_ SG_ 523 TAS_staticHeightEstimateRL "Current static height estimate of the RL air spring; raw 1023 = signal not available (SNA)";
CM_ SG_ 523 TAS_componentPressureRL "Current static pressure of the RL air spring; raw 255 = signal not available (SNA)";
CM_ SG_ 523 TAS_rawHeightRR "Current height of the RR air spring; raw 1023 = signal not available (SNA)";
CM_ SG_ 523 TAS_staticHeightEstimateRR "Current static height estimate of the RR air spring; raw 1023 = signal not available (SNA)";
CM_ SG_ 523 TAS_componentPressureRR "Current static pressure of the RR air spring; raw 255 = signal not available (SNA)";
CM_ BO_ 1398 "Air suspension controller message: damping states; frame length from the layout, not yet observed on a vehicle bus";
CM_ SG_ 1398 TAS_endstopState "Air suspension controller: endstop state";
CM_ SG_ 1398 TAS_continuousControlState "SW-237496";
CM_ SG_ 1398 TAS_activeTireTune "Air suspension controller: active tire tune";
CM_ SG_ 1398 TAS_roughnessRaiseReason "Air suspension controller: roughness raise reason";
CM_ SG_ 1398 TAS_frontMetricDrivesRear "Air suspension controller: front metric drives rear";
CM_ SG_ 1398 TAS_roadCondition "Air suspension controller: road condition; raw 255 = signal not available (SNA)";
CM_ SG_ 1398 TAS_bellyProtect "Air suspension controller: belly protect";
CM_ SG_ 1398 TAS_frontMetricDrivesFront "Air suspension controller: front metric drives front";
CM_ SG_ 1398 TAS_speedBumpAxleFront "Air suspension controller: speed bump axle front";
CM_ SG_ 1398 TAS_speedBumpAxleRear "Air suspension controller: speed bump axle rear";
CM_ SG_ 1398 TAS_holeProtectFL "Air suspension controller: hole protect FL";
CM_ SG_ 1398 TAS_holeProtectFR "Air suspension controller: hole protect FR";
CM_ SG_ 1398 TAS_holeProtectRL "Air suspension controller: hole protect RL";
CM_ SG_ 1398 TAS_holeProtectRR "Air suspension controller: hole protect RR";
CM_ SG_ 1398 TAS_stepProtectFL "Air suspension controller: step protect FL";
CM_ SG_ 1398 TAS_stepProtectFR "Air suspension controller: step protect FR";
CM_ SG_ 1398 TAS_stepProtectRL "Air suspension controller: step protect RL";
CM_ SG_ 1398 TAS_stepProtectRR "Air suspension controller: step protect RR";
CM_ SG_ 1398 TAS_FDUTorqueCorruptionScale "Air suspension controller: FDU torque corruption scale; raw 15 = signal not available (SNA)";
CM_ SG_ 1398 TAS_sprungMassEstimate "Air suspension controller: sprung mass estimate; raw 31 = signal not available (SNA)";
CM_ SG_ 1398 TAS_anyDamperActive "Air suspension controller: any damper active";
CM_ SG_ 1398 TAS_dampingStatesCounter "Air suspension controller: damping states counter";
CM_ SG_ 1398 TAS_dampingStatesChecksum "Air suspension controller: damping states checksum";
CM_ BO_ 1357 "Air suspension controller message: info; frame length from the layout, not yet observed on a vehicle bus";
CM_ SG_ 1357 TAS_infoIndex "Air suspension controller: info index";
CM_ SG_ 1357 TAS_infoBuildType "Air suspension controller: info build type";
CM_ SG_ 1357 TAS_infoBuildConfigId "Air suspension controller: info build config id";
CM_ SG_ 1357 TAS_infoHardwareId "Air suspension controller: info hardware id";
CM_ SG_ 1357 TAS_infoComponentId "Air suspension controller: info component id";
CM_ SG_ 1357 TAS_infoPcbaId "Air suspension controller: info pcba id";
CM_ SG_ 1357 TAS_infoAssemblyId "Air suspension controller: info assembly id; raw 255 = signal not available (SNA)";
CM_ SG_ 1357 TAS_infoUsageId "Air suspension controller: info usage id";
CM_ SG_ 1357 TAS_infoSubUsageId "Air suspension controller: info sub usage id";
CM_ SG_ 1357 TAS_infoAppCrc "Air suspension controller: info app crc";
CM_ SG_ 1357 TAS_infoAppGitHash "Air suspension controller: info app git hash";
CM_ SG_ 1357 TAS_infoBootGitHash "Air suspension controller: info boot git hash";
CM_ SG_ 1357 TAS_infoPlatformType "Air suspension controller: info platform type";
CM_ SG_ 1357 TAS_infoMajorVersion "Air suspension controller: info major version; raw 255 = signal not available (SNA)";
CM_ SG_ 1357 TAS_infoBranchOrigin "Air suspension controller: info branch origin; raw 255 = signal not available (SNA)";
CM_ SG_ 1357 TAS_infoMaturity "Air suspension controller: info maturity; raw 255 = signal not available (SNA)";
CM_ SG_ 1357 TAS_infoHardwareRevision "Air suspension controller: info hardware revision; raw 255 = signal not available (SNA)";
CM_ BO_ 525 "Air suspension controller message: states; frame length from the layout, not yet observed on a vehicle bus";
CM_ SG_ 525 TAS_levelingState "Indicates air suspension leveling state.";
CM_ SG_ 525 TAS_levelingItem "Indicates the currently active air suspension components.";
CM_ SG_ 525 TAS_pressureGallery "Current air suspension valve block gallery pressure; raw 255 = signal not available (SNA)";
CM_ SG_ 525 TAS_pressureReservoir "Indicates the latest valid reservoir pressure; raw 255 = signal not available (SNA)";
CM_ SG_ 525 TAS_runMode "Indicates the status of run mode.";
CM_ SG_ 525 TAS_filterMode "Indicates the status of filter mode.";
CM_ SG_ 525 TAS_compressorRun "Either an indication that the compressor is running or a request to run the air compressor";
CM_ SG_ 525 TAS_twistDetected "TAS has detected large amount of twist.";
CM_ SG_ 525 TAS_leanDetected "TAS has detected vehicle to be leaning left or right.";
CM_ SG_ 525 TAS_limpHomeMode "Indicates which limp home mode is active.";
CM_ SG_ 525 TAS_targetLevel "Indicates target ride height.";
CM_ SG_ 525 TAS_currentLevel "Indicates current ride height.";
CM_ SG_ 525 TAS_jackMode "Indicates the status of Jack mode.";
CM_ SG_ 525 TAS_reduceVehicleSpeedRequest "Air suspension controller: reduce vehicle speed request";
CM_ SG_ 525 TAS_statesCounter "Air suspension controller: states counter";
CM_ SG_ 525 TAS_statesChecksum "Air suspension controller: states checksum";
CM_ BO_ 409 "Air suspension controller message: ui adaptive activity0; frame length from the layout, not yet observed on a vehicle bus";
CM_ SG_ 409 TAS_adaptiveActivityFL_C "Air suspension controller: adaptive activity FL c; raw 31 = signal not available (SNA)";
CM_ SG_ 409 TAS_adaptiveActivityFL_R "Air suspension controller: adaptive activity FL r; raw 31 = signal not available (SNA)";
CM_ SG_ 409 TAS_adaptiveActivityFR_C "Air suspension controller: adaptive activity FR c; raw 31 = signal not available (SNA)";
CM_ SG_ 409 TAS_adaptiveActivityFR_R "Air suspension controller: adaptive activity FR r; raw 31 = signal not available (SNA)";
CM_ SG_ 409 TAS_adaptiveActivityRL_C "Air suspension controller: adaptive activity RL c; raw 31 = signal not available (SNA)";
CM_ SG_ 409 TAS_adaptiveActivityRL_R "Air suspension controller: adaptive activity RL r; raw 31 = signal not available (SNA)";
CM_ SG_ 409 TAS_adaptiveActivityRR_C "Air suspension controller: adaptive activity RR c; raw 31 = signal not available (SNA)";
CM_ SG_ 409 TAS_adaptiveActivityRR_R "Air suspension controller: adaptive activity RR r; raw 31 = signal not available (SNA)";
CM_ SG_ 409 TAS_uiHeightFL "Air suspension controller: ui height FL; raw 63 = signal not available (SNA)";
CM_ SG_ 409 TAS_uiHeightFR "Air suspension controller: ui height FR; raw 63 = signal not available (SNA)";
CM_ SG_ 409 TAS_uiHeightRL "Air suspension controller: ui height RL; raw 63 = signal not available (SNA)";
CM_ SG_ 409 TAS_uiHeightRR "Air suspension controller: ui height RR; raw 63 = signal not available (SNA)";
CM_ BO_ 410 "Air suspension controller message: ui adaptive activity1; frame length from the layout, not yet observed on a vehicle bus";
CM_ SG_ 410 TAS_bodyAccelFL "Air suspension controller: body accel FL; raw 255 = signal not available (SNA)";
CM_ SG_ 410 TAS_bodyAccelFR "Air suspension controller: body accel FR; raw 255 = signal not available (SNA)";
CM_ SG_ 410 TAS_bodyAccelRL "Air suspension controller: body accel RL; raw 255 = signal not available (SNA)";
CM_ SG_ 410 TAS_bodyAccelRR "Air suspension controller: body accel RR; raw 255 = signal not available (SNA)";
CM_ BO_ 538 "Air suspension controller message: ui control; frame length from the layout, not yet observed on a vehicle bus";
CM_ SG_ 538 TAS_yellowWarningLamp "Air suspension controller: yellow warning lamp";
CM_ SG_ 538 TAS_redWarningLamp "Air suspension controller: red warning lamp";
CM_ SG_ 538 TAS_veryLowAllowed "Air suspension controller: very low allowed";
CM_ SG_ 538 TAS_lowAllowed "Air suspension controller: low allowed";
CM_ SG_ 538 TAS_standardAllowed "Air suspension controller: standard allowed";
CM_ SG_ 538 TAS_highAllowed "Air suspension controller: high allowed";
CM_ SG_ 538 TAS_veryHighAllowed "Air suspension controller: very high allowed";
CM_ SG_ 538 TAS_extractAllowed "Air suspension controller: extract allowed";
CM_ SG_ 538 TAS_showSpinner "Air suspension controller: show spinner";
CM_ SG_ 538 TAS_adaptiveRideModeOverride "Air suspension controller: adaptive ride mode override; raw 3 = signal not available (SNA)";
CM_ SG_ 538 TAS_levelSelectEnabled "Air suspension controller: level select enabled";
CM_ SG_ 538 TAS_jackModeToggleEnabled "Air suspension controller: jack mode toggle enabled";
CM_ SG_ 538 TAS_adaptiveRideSelectEnabled "Air suspension controller: adaptive ride select enabled";
CM_ SG_ 538 TAS_launchModeState "Air suspension controller: launch mode state";
CM_ SG_ 538 TAS_restrictUpLevelingFalcons "Air suspension controller: restrict up leveling falcons";
CM_ SG_ 538 TAS_restrictUpLevelingTrunk "Air suspension controller: restrict up leveling trunk";
CM_ SG_ 538 TAS_restrictDownLevelingDoors "Air suspension controller: restrict down leveling doors";
CM_ SG_ 538 TAS_restrictLevelingChargeCable "Air suspension controller: restrict leveling charge cable";
CM_ SG_ 538 TAS_restrictLevelingSystemCheck "Air suspension controller: restrict leveling system check";
CM_ SG_ 538 TAS_restrictLevelingTransport "Air suspension controller: restrict leveling transport";
CM_ SG_ 538 TAS_restrictLevelingShowroom "Indication that up and down leveling are restricted while showroom mode is active.";
CM_ SG_ 538 TAS_uiControlCounter "Air suspension controller: ui control counter";
CM_ SG_ 538 TAS_uiControlChecksum "Air suspension controller: ui control checksum";
CM_ BO_ 1154 "Touchscreen user interface computer message: iso tp pipe remote VCSEC; forwarded onto this bus by the gateway; frame length observed on a vehicle bus";
CM_ SG_ 1154 UI_IsoTpRemoteVCSEC0 "Touchscreen user interface computer: iso tp remote VCSEC0";
CM_ SG_ 1154 UI_IsoTpRemoteVCSEC1 "Touchscreen user interface computer: iso tp remote VCSEC1";
CM_ SG_ 1154 UI_IsoTpRemoteVCSEC2 "Touchscreen user interface computer: iso tp remote VCSEC2";
CM_ SG_ 1154 UI_IsoTpRemoteVCSEC3 "Touchscreen user interface computer: iso tp remote VCSEC3";
CM_ SG_ 1154 UI_IsoTpRemoteVCSEC4 "Touchscreen user interface computer: iso tp remote VCSEC4";
CM_ SG_ 1154 UI_IsoTpRemoteVCSEC5 "Touchscreen user interface computer: iso tp remote VCSEC5";
CM_ SG_ 1154 UI_IsoTpRemoteVCSEC6 "Touchscreen user interface computer: iso tp remote VCSEC6";
CM_ SG_ 1154 UI_IsoTpRemoteVCSEC7 "Touchscreen user interface computer: iso tp remote VCSEC7";
CM_ BO_ 1153 "Touchscreen user interface computer message: iso tp UDP pipe VCSEC; forwarded onto this bus by the gateway; frame length from the layout, not yet observed on a vehicle bus";
CM_ SG_ 1153 UI_IsoTpUDPPipeVCSEC0 "Touchscreen user interface computer: iso tp UDP pipe VCSEC0";
CM_ SG_ 1153 UI_IsoTpUDPPipeVCSEC1 "Touchscreen user interface computer: iso tp UDP pipe VCSEC1";
CM_ SG_ 1153 UI_IsoTpUDPPipeVCSEC2 "Touchscreen user interface computer: iso tp UDP pipe VCSEC2";
CM_ SG_ 1153 UI_IsoTpUDPPipeVCSEC3 "Touchscreen user interface computer: iso tp UDP pipe VCSEC3";
CM_ SG_ 1153 UI_IsoTpUDPPipeVCSEC4 "Touchscreen user interface computer: iso tp UDP pipe VCSEC4";
CM_ SG_ 1153 UI_IsoTpUDPPipeVCSEC5 "Touchscreen user interface computer: iso tp UDP pipe VCSEC5";
CM_ SG_ 1153 UI_IsoTpUDPPipeVCSEC6 "Touchscreen user interface computer: iso tp UDP pipe VCSEC6";
CM_ SG_ 1153 UI_IsoTpUDPPipeVCSEC7 "Touchscreen user interface computer: iso tp UDP pipe VCSEC7";
CM_ BO_ 659 "Touchscreen user interface computer message: chassis control; forwarded onto this bus by the gateway; frame length observed on a vehicle bus";
CM_ SG_ 659 UI_steeringTuneRequest "UI customer level request for steering feel. MS had comfort, normal, sport. M3 intent is Normal, sport see SW-95934";
CM_ SG_ 659 UI_tractionControlMode "Transport user selected traction control modes";
CM_ SG_ 659 UI_parkBrakeRequest "User selection for Park brake; raw 3 = signal not available (SNA)";
CM_ SG_ 659 UI_narrowGarages "Touchscreen user interface computer: narrow garages";
CM_ SG_ 659 UI_winchModeRequest "Winch mode (towing) request";
CM_ SG_ 659 UI_zeroSpeedConfirmed "Touchscreen user interface computer: zero speed confirmed; raw 3 = signal not available (SNA)";
CM_ SG_ 659 UI_trailerMode "Indicates whether trailer mode is selected. To be used when towing a trailer.";
CM_ SG_ 659 UI_distanceUnits "Touchscreen user interface computer: distance units";
CM_ SG_ 659 UI_dasDebugEnable "Touchscreen user interface computer: das debug enable";
CM_ SG_ 659 UI_accOvertakeEnable "Enable ACC Overtake assistance (reduce follow distance when the turn signal is on), UI firmware only sets datavalue to True; raw 3 = signal not available (SNA)";
CM_ SG_ 659 UI_aebEnable "Enable Autonomous Emergency Brakes; raw 3 = signal not available (SNA)";
CM_ SG_ 659 UI_aesEnable "Enable Automatic Emergency Steering (associated datavalue set to true and never changed by UI firmware); raw 3 = signal not available (SNA)";
CM_ SG_ 659 UI_ahlbEnable "Enable Automatic High/Low Beams; raw 3 = signal not available (SNA)";
CM_ SG_ 659 UI_autoLaneChangeEnable "Enable Automatic Lane Change; raw 3 = signal not available (SNA)";
CM_ SG_ 659 UI_winchProxUserOverride "User feedback from tow mode panel confirming that charge cable is disconnected when vehicle is unable to determine cable status";
CM_ SG_ 659 UI_rebootAutopilot "Touchscreen user interface computer: reboot autopilot";
CM_ SG_ 659 UI_autoParkRequest "Request Automatic Parking; raw 15 = signal not available (SNA)";
CM_ SG_ 659 UI_bsdEnable "Enable Blind Spot Detection (datavalue defaults to true and not changed by UI firmware); raw 3 = signal not available (SNA)";
CM_ SG_ 659 UI_fcwEnable "Enable Forward Collision Warning; raw 3 = signal not available (SNA)";
CM_ SG_ 659 UI_fcwSensitivity "Forward Collision Warning Level; raw 3 = signal not available (SNA)";
CM_ SG_ 659 UI_latControlEnable "Enable Lateral Control (lane centering, lane keeping, lane changing); raw 3 = signal not available (SNA)";
CM_ SG_ 659 UI_ldwEnable "Enable Lane Departure Warning; raw 3 = signal not available (SNA)";
CM_ SG_ 659 UI_pedalSafetyEnable "Touchscreen user interface computer: pedal safety enable; raw 3 = signal not available (SNA)";
CM_ SG_ 659 UI_pedalMap_epas "Touchscreen user interface computer: pedal map epas";
CM_ SG_ 659 UI_redLightStopSignEnable "Touchscreen user interface computer: red light stop sign enable; raw 3 = signal not available (SNA)";
CM_ SG_ 659 UI_selfParkTune "Touchscreen user interface computer: self park tune; raw 15 = signal not available (SNA)";
CM_ SG_ 659 UI_chassisControlCounter "Touchscreen user interface computer: chassis control counter";
CM_ SG_ 659 UI_chassisControlChecksum "Touchscreen user interface computer: chassis control checksum";
CM_ BO_ 1280 "Touchscreen user interface computer message: debug ECU; forwarded onto this bus by the gateway; frame length from the layout, not yet observed on a vehicle bus";
CM_ SG_ 1280 UI_debugEcuTarget "Touchscreen user interface computer: debug ecu target";
CM_ SG_ 1280 UI_DI_debugEnable "Touchscreen user interface computer: DI debug enable";
CM_ SG_ 1280 UI_DIS_debugEnable "Touchscreen user interface computer: DIS debug enable";
CM_ SG_ 1280 UI_PM_debugEnable "Touchscreen user interface computer: PM debug enable";
CM_ SG_ 1280 UI_PM_debugAt100Hz "Touchscreen user interface computer: PM debug at100 hz";
CM_ SG_ 1280 UI_PMS_debugEnable "Touchscreen user interface computer: PMS debug enable";
CM_ SG_ 1280 UI_PMS_debugAt100Hz "Touchscreen user interface computer: PMS debug at100 hz";
CM_ SG_ 1280 UI_BMS_debugAllEnable "Touchscreen user interface computer: BMS debug all enable";
CM_ SG_ 1280 UI_BMS_debugDisable "Touchscreen user interface computer: BMS debug disable";
CM_ SG_ 1280 UI_VCRIGHT_debugEnable "Touchscreen user interface computer: VCRIGHT debug enable";
CM_ SG_ 1280 UI_VCFRONT_debugEnable "Touchscreen user interface computer: VCFRONT debug enable";
CM_ SG_ 1280 UI_DIF_debugEnable "Touchscreen user interface computer: DIF debug enable";
CM_ SG_ 1280 UI_DIR_debugEnable "Touchscreen user interface computer: DIR debug enable";
CM_ SG_ 1280 UI_PMF_debugEnable "Touchscreen user interface computer: PMF debug enable";
CM_ SG_ 1280 UI_PMR_debugEnable "Touchscreen user interface computer: PMR debug enable";
CM_ BO_ 2043 "Touchscreen user interface computer message: debug tas; forwarded onto this bus by the gateway; frame length from the layout, not yet observed on a vehicle bus";
CM_ SG_ 2043 UI_debugDampingRequestFLC "Touchscreen user interface computer: debug damping request FLC; raw 255 = signal not available (SNA)";
CM_ SG_ 2043 UI_debugDampingRequestFLR "Touchscreen user interface computer: debug damping request FLR; raw 255 = signal not available (SNA)";
CM_ SG_ 2043 UI_debugDampingRequestFRC "Touchscreen user interface computer: debug damping request FRC; raw 255 = signal not available (SNA)";
CM_ SG_ 2043 UI_debugDampingRequestFRR "Touchscreen user interface computer: debug damping request FRR; raw 255 = signal not available (SNA)";
CM_ SG_ 2043 UI_debugDampingRequestRLC "Touchscreen user interface computer: debug damping request RLC; raw 255 = signal not available (SNA)";
CM_ SG_ 2043 UI_debugDampingRequestRLR "Touchscreen user interface computer: debug damping request RLR; raw 255 = signal not available (SNA)";
CM_ SG_ 2043 UI_debugDampingRequestRRC "Touchscreen user interface computer: debug damping request RRC; raw 255 = signal not available (SNA)";
CM_ SG_ 2043 UI_debugDampingRequestRRR "Touchscreen user interface computer: debug damping request RRR; raw 255 = signal not available (SNA)";
CM_ BO_ 568 "Touchscreen user interface computer message: driver assist map data; forwarded onto this bus by the gateway; frame length observed on a vehicle bus";
CM_ SG_ 568 UI_mapSpeedLimitDependency "Touchscreen user interface computer: map speed limit dependency; raw 7 = signal not available (SNA)";
CM_ SG_ 568 UI_roadClass "Autopilot map road class; raw 0 = signal not available (SNA)";
CM_ SG_ 568 UI_inSuperchargerGeofence "Touchscreen user interface computer: in supercharger geofence";
CM_ SG_ 568 UI_mapSpeedUnits "Touchscreen user interface computer: map speed units";
CM_ SG_ 568 UI_mapSpeedLimit "Touchscreen user interface computer: map speed limit; raw 31 = signal not available (SNA)";
CM_ SG_ 568 UI_mapSpeedLimitType "Touchscreen user interface computer: map speed limit type; raw 7 = signal not available (SNA)";
CM_ SG_ 568 UI_countryCode "Touchscreen user interface computer: country code; raw 1023 = signal not available (SNA)";
CM_ SG_ 568 UI_streetCount "Touchscreen user interface computer: street count";
CM_ SG_ 568 UI_gpsRoadMatch "Touchscreen user interface computer: gps road match";
CM_ SG_ 568 UI_navRouteActive "Navigation route is active";
CM_ SG_ 568 UI_parallelAutoparkEnabled "Autopilot map parallel park enabled.";
CM_ SG_ 568 UI_perpendicularAutoparkEnabled "Autopilot map perpendicular park enabled.";
CM_ SG_ 568 UI_nextBranchDist "Touchscreen user interface computer: next branch dist; raw 31 = signal not available (SNA)";
CM_ SG_ 568 UI_controlledAccess "DAS map controlled access segment.";
CM_ SG_ 568 UI_nextBranchLeftOffRamp "Touchscreen user interface computer: next branch left off ramp";
CM_ SG_ 568 UI_nextBranchRightOffRamp "Touchscreen user interface computer: next branch right off ramp";
CM_ SG_ 568 UI_rejectLeftLane "Touchscreen user interface computer: reject left lane";
CM_ SG_ 568 UI_rejectRightLane "Touchscreen user interface computer: reject right lane";
CM_ SG_ 568 UI_rejectHPP "Touchscreen user interface computer: reject HPP";
CM_ SG_ 568 UI_rejectNav "Touchscreen user interface computer: reject nav";
CM_ SG_ 568 UI_rejectLeftFreeSpace "Touchscreen user interface computer: reject left free space";
CM_ SG_ 568 UI_rejectRightFreeSpace "Touchscreen user interface computer: reject right free space";
CM_ SG_ 568 UI_rejectAutosteer "Touchscreen user interface computer: reject autosteer";
CM_ SG_ 568 UI_rejectHandsOn "Touchscreen user interface computer: reject hands on";
CM_ SG_ 568 UI_acceptBottsDots "Touchscreen user interface computer: accept botts dots";
CM_ SG_ 568 UI_autosteerRestricted "Autopilot map is autostreer restricted.";
CM_ SG_ 568 UI_pmmEnabled "Touchscreen user interface computer: pmm enabled";
CM_ SG_ 568 UI_scaEnabled "Touchscreen user interface computer: sca enabled";
CM_ SG_ 568 UI_mapDataCounter "Touchscreen user interface computer: map data counter";
CM_ SG_ 568 UI_mapDataChecksum "Touchscreen user interface computer: map data checksum";
CM_ BO_ 651 "Touchscreen user interface computer message: driver profile recall2; forwarded onto this bus by the gateway; frame length from the layout, not yet observed on a vehicle bus";
CM_ SG_ 651 UI_driverProfileLinkedKeySHA1 "Touchscreen user interface computer: driver profile linked key SHA1; raw 4294967295 = signal not available (SNA)";
CM_ SG_ 651 UI_driverProfileIndex "Tracks manual driver profile selection. Shows the linked phonekey / key card / key fob or profile index if not linked";
CM_ SG_ 651 UI_driverProfileSelectionType "Tracks manual driver profile selection. Shows the linked phonekey / key card / key fob or profile index if not linked";
CM_ SG_ 651 UI_driverProfilePositionAdjusted "Tracks adjustments to driver profile. Sets when a profile position has been adjusted from what was saved";
CM_ SG_ 651 UI_activeKeyRequested "Tracks manual driver profile selection. Shows the linked phonekey / key card / key fob or profile index if not linked";
CM_ BO_ 984 "Touchscreen user interface computer message: elevation status; forwarded onto this bus by the gateway; frame length observed on a vehicle bus";
CM_ SG_ 984 UI_elevation "Touchscreen user interface computer: elevation; raw 8191 = signal not available (SNA)";
CM_ SG_ 984 UI_navElevation "Touchscreen user interface computer: nav elevation; raw 8191 = signal not available (SNA)";
CM_ BO_ 804 "Touchscreen user interface computer message: gps time; forwarded onto this bus by the gateway; frame length observed on a vehicle bus";
CM_ SG_ 804 UI_gpsTime "Touchscreen user interface computer: gps time";
CM_ BO_ 883 "Touchscreen user interface computer message: gps vehicle speed; forwarded onto this bus by the gateway; frame length observed on a vehicle bus";
CM_ SG_ 883 UI_gpsHDOP "Touchscreen user interface computer: gps HDOP";
CM_ SG_ 883 UI_gpsVehicleHeading "Touchscreen user interface computer: gps vehicle heading";
CM_ SG_ 883 UI_gpsVehicleSpeed "Touchscreen user interface computer: gps vehicle speed";
CM_ SG_ 883 UI_userSpeedOffset "Touchscreen user interface computer: user speed offset";
CM_ SG_ 883 UI_mapSpeedLimitUnits "Autopilot map speed limit units.";
CM_ SG_ 883 UI_userSpeedOffsetUnits "Touchscreen user interface computer: user speed offset units";
CM_ SG_ 883 UI_mppSpeedLimit "Autopilot map speed limit";
CM_ SG_ 883 UI_gpsNmeaMIA "GPS NMEA data MIA";
CM_ SG_ 883 UI_gpsAntennaDisconnected "GPS antenna state";
CM_ SG_ 883 UI_conditionalLimitActive "Conditional speed limit condition is currently active";
CM_ SG_ 883 UI_conditionalSpeedLimit "Conditional speed limit value; raw 31 = signal not available (SNA)";
BA_DEF_ BO_ "GenMsgCycleTime" INT 0 3600000;
BA_DEF_ BO_ "GenMsgSendType" ENUM "Cyclic","NotUsed","NotUsed","NotUsed","NotUsed","NotUsed","NotUsed","IfActive","NoMsgSendType","NotUsed";
BA_DEF_ BO_ "VFrameFormat" ENUM "StandardCAN","ExtendedCAN","reserved","J1939PG","reserved","reserved","reserved","reserved","reserved","reserved","reserved","reserved","reserved","reserved","StandardCAN_FD","ExtendedCAN_FD";
BA_DEF_ BO_ "CANFD_BRS" ENUM "0","1";
BA_DEF_ SG_ "GenSigSNA" STRING;
BA_DEF_ SG_ "SystemSignalLongSymbol" STRING;
BA_DEF_ SG_ "Confidence" ENUM "validated","plausible","layout-only","contradicted";
BA_DEF_DEF_ "GenMsgCycleTime" 0;
BA_DEF_DEF_ "GenMsgSendType" "NoMsgSendType";
BA_DEF_DEF_ "VFrameFormat" "StandardCAN";
BA_DEF_DEF_ "CANFD_BRS" "1";
BA_DEF_DEF_ "GenSigSNA" "";
BA_DEF_DEF_ "SystemSignalLongSymbol" "";
BA_DEF_DEF_ "Confidence" "layout-only";
BA_ "GenMsgCycleTime" BO_ 612 100;
BA_ "GenMsgSendType" BO_ 612 0;
BA_ "GenMsgCycleTime" BO_ 692 100;
BA_ "GenMsgSendType" BO_ 692 0;
BA_ "GenMsgCycleTime" BO_ 964 1000;
BA_ "GenMsgSendType" BO_ 964 0;
BA_ "GenMsgCycleTime" BO_ 676 1000;
BA_ "GenMsgSendType" BO_ 676 0;
BA_ "GenMsgCycleTime" BO_ 790 1000;
BA_ "GenMsgSendType" BO_ 790 0;
BA_ "GenMsgCycleTime" BO_ 1748 1000;
BA_ "GenMsgSendType" BO_ 1748 0;
BA_ "GenMsgCycleTime" BO_ 1551 1000;
BA_ "GenMsgSendType" BO_ 1551 0;
BA_ "GenMsgCycleTime" BO_ 837 1000;
BA_ "GenMsgSendType" BO_ 837 0;
BA_ "GenMsgCycleTime" BO_ 647 100;
BA_ "GenMsgSendType" BO_ 647 0;
BA_ "GenMsgCycleTime" BO_ 1359 100;
BA_ "GenMsgSendType" BO_ 1359 0;
BA_ "GenMsgCycleTime" BO_ 816 1000;
BA_ "GenMsgSendType" BO_ 816 0;
BA_ "GenMsgCycleTime" BO_ 585 50;
BA_ "GenMsgSendType" BO_ 585 0;
BA_ "GenMsgCycleTime" BO_ 553 100;
BA_ "GenMsgSendType" BO_ 553 0;
BA_ "GenMsgCycleTime" BO_ 297 10;
BA_ "GenMsgSendType" BO_ 297 0;
BA_ "GenMsgCycleTime" BO_ 815 1000;
BA_ "GenMsgSendType" BO_ 815 0;
BA_ "GenMsgCycleTime" BO_ 1355 1000;
BA_ "GenMsgSendType" BO_ 1355 0;
BA_ "GenMsgCycleTime" BO_ 869 1000;
BA_ "GenMsgSendType" BO_ 869 0;
BA_ "GenMsgCycleTime" BO_ 880 1000;
BA_ "GenMsgSendType" BO_ 880 0;
BA_ "GenMsgCycleTime" BO_ 1467 1000;
BA_ "GenMsgSendType" BO_ 1467 0;
BA_ "GenMsgCycleTime" BO_ 1597 1000;
BA_ "GenMsgSendType" BO_ 1597 0;
BA_ "GenMsgCycleTime" BO_ 792 100;
BA_ "GenMsgSendType" BO_ 792 0;
BA_ "GenMsgCycleTime" BO_ 523 20;
BA_ "GenMsgSendType" BO_ 523 0;
BA_ "GenMsgCycleTime" BO_ 1398 100;
BA_ "GenMsgSendType" BO_ 1398 0;
BA_ "GenMsgCycleTime" BO_ 1357 1000;
BA_ "GenMsgSendType" BO_ 1357 0;
BA_ "GenMsgCycleTime" BO_ 525 100;
BA_ "GenMsgSendType" BO_ 525 0;
BA_ "GenMsgCycleTime" BO_ 409 50;
BA_ "GenMsgSendType" BO_ 409 0;
BA_ "GenMsgCycleTime" BO_ 410 50;
BA_ "GenMsgSendType" BO_ 410 0;
BA_ "GenMsgCycleTime" BO_ 538 100;
BA_ "GenMsgSendType" BO_ 538 0;
BA_ "GenMsgCycleTime" BO_ 659 500;
BA_ "GenMsgSendType" BO_ 659 0;
BA_ "GenMsgCycleTime" BO_ 1280 5000;
BA_ "GenMsgSendType" BO_ 1280 0;
BA_ "GenMsgCycleTime" BO_ 2043 2000;
BA_ "GenMsgSendType" BO_ 2043 0;
BA_ "GenMsgCycleTime" BO_ 568 500;
BA_ "GenMsgSendType" BO_ 568 0;
BA_ "GenMsgCycleTime" BO_ 651 500;
BA_ "GenMsgSendType" BO_ 651 0;
BA_ "GenMsgCycleTime" BO_ 984 1000;
BA_ "GenMsgSendType" BO_ 984 0;
BA_ "GenMsgCycleTime" BO_ 804 1000;
BA_ "GenMsgSendType" BO_ 804 0;
BA_ "GenMsgCycleTime" BO_ 883 1000;
BA_ "GenMsgSendType" BO_ 883 0;
BA_ "Confidence" SG_ 1012 LS_lightShowIndex 1;
BA_ "Confidence" SG_ 1012 LS_lightLeftRampedChannel1Reques 0;
BA_ "SystemSignalLongSymbol" SG_ 1012 LS_lightLeftRampedChannel1Reques "LS_lightLeftRampedChannel1Request";
BA_ "Confidence" SG_ 1012 LS_lightLeftRampedChannel1Durati 0;
BA_ "SystemSignalLongSymbol" SG_ 1012 LS_lightLeftRampedChannel1Durati "LS_lightLeftRampedChannel1Duration";
BA_ "Confidence" SG_ 1012 LS_lightLeftRampedChannel2Reques 0;
BA_ "SystemSignalLongSymbol" SG_ 1012 LS_lightLeftRampedChannel2Reques "LS_lightLeftRampedChannel2Request";
BA_ "Confidence" SG_ 1012 LS_lightLeftRampedChannel2Durati 0;
BA_ "SystemSignalLongSymbol" SG_ 1012 LS_lightLeftRampedChannel2Durati "LS_lightLeftRampedChannel2Duration";
BA_ "Confidence" SG_ 1012 LS_lightLeftRampedChannel3Reques 0;
BA_ "SystemSignalLongSymbol" SG_ 1012 LS_lightLeftRampedChannel3Reques "LS_lightLeftRampedChannel3Request";
BA_ "Confidence" SG_ 1012 LS_lightLeftRampedChannel3Durati 0;
BA_ "SystemSignalLongSymbol" SG_ 1012 LS_lightLeftRampedChannel3Durati "LS_lightLeftRampedChannel3Duration";
BA_ "Confidence" SG_ 1012 LS_lightLeftRampedChannel4Reques 0;
BA_ "SystemSignalLongSymbol" SG_ 1012 LS_lightLeftRampedChannel4Reques "LS_lightLeftRampedChannel4Request";
BA_ "Confidence" SG_ 1012 LS_lightLeftRampedChannel4Durati 0;
BA_ "SystemSignalLongSymbol" SG_ 1012 LS_lightLeftRampedChannel4Durati "LS_lightLeftRampedChannel4Duration";
BA_ "Confidence" SG_ 1012 LS_lightLeftRampedChannel5Reques 0;
BA_ "SystemSignalLongSymbol" SG_ 1012 LS_lightLeftRampedChannel5Reques "LS_lightLeftRampedChannel5Request";
BA_ "Confidence" SG_ 1012 LS_lightLeftRampedChannel5Durati 0;
BA_ "SystemSignalLongSymbol" SG_ 1012 LS_lightLeftRampedChannel5Durati "LS_lightLeftRampedChannel5Duration";
BA_ "Confidence" SG_ 1012 LS_lightLeftRampedChannel6Reques 0;
BA_ "SystemSignalLongSymbol" SG_ 1012 LS_lightLeftRampedChannel6Reques "LS_lightLeftRampedChannel6Request";
BA_ "Confidence" SG_ 1012 LS_lightLeftRampedChannel6Durati 0;
BA_ "SystemSignalLongSymbol" SG_ 1012 LS_lightLeftRampedChannel6Durati "LS_lightLeftRampedChannel6Duration";
BA_ "Confidence" SG_ 1012 LS_lightLeftRampedChannel7Reques 0;
BA_ "SystemSignalLongSymbol" SG_ 1012 LS_lightLeftRampedChannel7Reques "LS_lightLeftRampedChannel7Request";
BA_ "Confidence" SG_ 1012 LS_lightLeftRampedChannel7Durati 0;
BA_ "SystemSignalLongSymbol" SG_ 1012 LS_lightLeftRampedChannel7Durati "LS_lightLeftRampedChannel7Duration";
BA_ "Confidence" SG_ 1012 LS_lightRightRampedChannel1Reque 0;
BA_ "SystemSignalLongSymbol" SG_ 1012 LS_lightRightRampedChannel1Reque "LS_lightRightRampedChannel1Request";
BA_ "Confidence" SG_ 1012 LS_lightRightRampedChannel1Durat 0;
BA_ "GenSigSNA" SG_ 1012 LS_lightRightRampedChannel1Durat "1";
BA_ "SystemSignalLongSymbol" SG_ 1012 LS_lightRightRampedChannel1Durat "LS_lightRightRampedChannel1Duration";
BA_ "Confidence" SG_ 1012 LS_lightRightRampedChannel2Reque 0;
BA_ "SystemSignalLongSymbol" SG_ 1012 LS_lightRightRampedChannel2Reque "LS_lightRightRampedChannel2Request";
BA_ "Confidence" SG_ 1012 LS_lightRightRampedChannel2Durat 0;
BA_ "GenSigSNA" SG_ 1012 LS_lightRightRampedChannel2Durat "1";
BA_ "SystemSignalLongSymbol" SG_ 1012 LS_lightRightRampedChannel2Durat "LS_lightRightRampedChannel2Duration";
BA_ "Confidence" SG_ 1012 LS_lightRightRampedChannel3Reque 0;
BA_ "SystemSignalLongSymbol" SG_ 1012 LS_lightRightRampedChannel3Reque "LS_lightRightRampedChannel3Request";
BA_ "Confidence" SG_ 1012 LS_lightRightRampedChannel3Durat 0;
BA_ "SystemSignalLongSymbol" SG_ 1012 LS_lightRightRampedChannel3Durat "LS_lightRightRampedChannel3Duration";
BA_ "Confidence" SG_ 1012 LS_lightRightRampedChannel4Reque 0;
BA_ "SystemSignalLongSymbol" SG_ 1012 LS_lightRightRampedChannel4Reque "LS_lightRightRampedChannel4Request";
BA_ "Confidence" SG_ 1012 LS_lightRightRampedChannel4Durat 0;
BA_ "SystemSignalLongSymbol" SG_ 1012 LS_lightRightRampedChannel4Durat "LS_lightRightRampedChannel4Duration";
BA_ "Confidence" SG_ 1012 LS_lightRightRampedChannel5Reque 0;
BA_ "SystemSignalLongSymbol" SG_ 1012 LS_lightRightRampedChannel5Reque "LS_lightRightRampedChannel5Request";
BA_ "Confidence" SG_ 1012 LS_lightRightRampedChannel5Durat 0;
BA_ "SystemSignalLongSymbol" SG_ 1012 LS_lightRightRampedChannel5Durat "LS_lightRightRampedChannel5Duration";
BA_ "Confidence" SG_ 1012 LS_lightRightRampedChannel6Reque 0;
BA_ "SystemSignalLongSymbol" SG_ 1012 LS_lightRightRampedChannel6Reque "LS_lightRightRampedChannel6Request";
BA_ "Confidence" SG_ 1012 LS_lightRightRampedChannel6Durat 0;
BA_ "SystemSignalLongSymbol" SG_ 1012 LS_lightRightRampedChannel6Durat "LS_lightRightRampedChannel6Duration";
BA_ "Confidence" SG_ 1012 LS_lightRightRampedChannel7Reque 0;
BA_ "SystemSignalLongSymbol" SG_ 1012 LS_lightRightRampedChannel7Reque "LS_lightRightRampedChannel7Request";
BA_ "Confidence" SG_ 1012 LS_lightRightRampedChannel7Durat 0;
BA_ "SystemSignalLongSymbol" SG_ 1012 LS_lightRightRampedChannel7Durat "LS_lightRightRampedChannel7Duration";
BA_ "Confidence" SG_ 1012 LS_lightRearTurnLeftRequest 0;
BA_ "Confidence" SG_ 1012 LS_lightRearTurnRightRequest 0;
BA_ "Confidence" SG_ 1012 LS_lightSideRepeaterLeftRequest 0;
BA_ "Confidence" SG_ 1012 LS_lightSideRepeaterRightRequest 0;
BA_ "Confidence" SG_ 1012 LS_lightSideMarkerLeftRequest 0;
BA_ "Confidence" SG_ 1012 LS_lightSideMarkerRightRequest 0;
BA_ "Confidence" SG_ 1012 LS_lightFrontFogLeftRequest 0;
BA_ "Confidence" SG_ 1012 LS_lightFrontFogRightRequest 0;
BA_ "Confidence" SG_ 1012 LS_lightRearFogRequest 0;
BA_ "Confidence" SG_ 1012 LS_lightBrakeRequest 0;
BA_ "Confidence" SG_ 1012 LS_lightTailLeftRequest 0;
BA_ "Confidence" SG_ 1012 LS_lightTailRightRequest 0;
BA_ "Confidence" SG_ 1012 LS_lightLicensePlateRequest 0;
BA_ "Confidence" SG_ 1012 LS_lightReverseRequest 0;
BA_ "Confidence" SG_ 1012 LS_lightAuxParkLeftRequest 0;
BA_ "Confidence" SG_ 1012 LS_lightAuxParkRightRequest 0;
BA_ "Confidence" SG_ 1012 LS_mirrorRequestLeft 0;
BA_ "Confidence" SG_ 1012 LS_mirrorRequestRight 0;
BA_ "Confidence" SG_ 1012 LS_liftgateRequest 0;
BA_ "Confidence" SG_ 1012 LS_windowRequestLF 0;
BA_ "Confidence" SG_ 1012 LS_windowRequestLR 0;
BA_ "Confidence" SG_ 1012 LS_windowRequestRF 0;
BA_ "Confidence" SG_ 1012 LS_windowRequestRR 0;
BA_ "Confidence" SG_ 1012 LS_presentingHandleRequestLF 0;
BA_ "Confidence" SG_ 1012 LS_presentingHandleRequestLR 0;
BA_ "Confidence" SG_ 1012 LS_presentingHandleRequestRF 0;
BA_ "Confidence" SG_ 1012 LS_presentingHandleRequestRR 0;
BA_ "Confidence" SG_ 1012 LS_powerFrontDoorRequestLeft 0;
BA_ "Confidence" SG_ 1012 LS_powerFrontDoorRequestRight 0;
BA_ "Confidence" SG_ 1012 LS_falconDoorRequestLeft 0;
BA_ "Confidence" SG_ 1012 LS_falconDoorRequestRight 0;
BA_ "Confidence" SG_ 1012 LS_chargePortRequest 0;
BA_ "GenSigSNA" SG_ 1012 LS_chargePortRequest "3";
BA_ "Confidence" SG_ 1012 LS_chargePortRaveRequest 0;
BA_ "Confidence" SG_ 1012 LS_suspensionRequest 0;
BA_ "GenSigSNA" SG_ 1012 LS_suspensionRequest "3";
BA_ "Confidence" SG_ 1012 LS_rgbIPFLRed 0;
BA_ "Confidence" SG_ 1012 LS_rgbIPFLGreen 0;
BA_ "Confidence" SG_ 1012 LS_rgbIPFLBlue 0;
BA_ "Confidence" SG_ 1012 LS_rgbIPFRRed 0;
BA_ "Confidence" SG_ 1012 LS_rgbIPFRGreen 0;
BA_ "Confidence" SG_ 1012 LS_rgbIPFRBlue 0;
BA_ "Confidence" SG_ 1012 LS_rgbDoorFLForeRed 0;
BA_ "Confidence" SG_ 1012 LS_rgbDoorFLForeGreen 0;
BA_ "Confidence" SG_ 1012 LS_rgbDoorFLForeBlue 0;
BA_ "Confidence" SG_ 1012 LS_rgbDoorFLAftRed 0;
BA_ "Confidence" SG_ 1012 LS_rgbDoorFLAftGreen 0;
BA_ "Confidence" SG_ 1012 LS_rgbDoorFLAftBlue 0;
BA_ "Confidence" SG_ 1012 LS_rgbDoorFRForeRed 0;
BA_ "Confidence" SG_ 1012 LS_rgbDoorFRForeGreen 0;
BA_ "Confidence" SG_ 1012 LS_rgbDoorFRForeBlue 0;
BA_ "Confidence" SG_ 1012 LS_rgbDoorFRAftRed 0;
BA_ "Confidence" SG_ 1012 LS_rgbDoorFRAftGreen 0;
BA_ "Confidence" SG_ 1012 LS_rgbDoorFRAftBlue 0;
BA_ "Confidence" SG_ 1012 LS_rgbDoorRLForeRed 0;
BA_ "Confidence" SG_ 1012 LS_rgbDoorRLForeGreen 0;
BA_ "Confidence" SG_ 1012 LS_rgbDoorRLForeBlue 0;
BA_ "Confidence" SG_ 1012 LS_rgbDoorRLAftRed 0;
BA_ "Confidence" SG_ 1012 LS_rgbDoorRLAftGreen 0;
BA_ "Confidence" SG_ 1012 LS_rgbDoorRLAftBlue 0;
BA_ "Confidence" SG_ 1012 LS_rgbDoorRRForeRed 0;
BA_ "Confidence" SG_ 1012 LS_rgbDoorRRForeGreen 0;
BA_ "Confidence" SG_ 1012 LS_rgbDoorRRForeBlue 0;
BA_ "Confidence" SG_ 1012 LS_rgbDoorRRAftRed 0;
BA_ "Confidence" SG_ 1012 LS_rgbDoorRRAftGreen 0;
BA_ "Confidence" SG_ 1012 LS_rgbDoorRRAftBlue 0;
BA_ "Confidence" SG_ 1012 LS_frontMatrix0 0;
BA_ "Confidence" SG_ 1012 LS_frontMatrix1 0;
BA_ "Confidence" SG_ 1012 LS_frontMatrix2 0;
BA_ "Confidence" SG_ 1012 LS_frontMatrix3 0;
BA_ "Confidence" SG_ 1012 LS_frontMatrix4 0;
BA_ "Confidence" SG_ 1012 LS_frontMatrix5 0;
BA_ "Confidence" SG_ 1012 LS_frontMatrix6 0;
BA_ "Confidence" SG_ 1012 LS_frontMatrix7 0;
BA_ "Confidence" SG_ 1012 LS_frontMatrix8 0;
BA_ "Confidence" SG_ 1012 LS_frontMatrix9 0;
BA_ "Confidence" SG_ 1012 LS_frontMatrix10 0;
BA_ "Confidence" SG_ 1012 LS_frontMatrix11 0;
BA_ "Confidence" SG_ 1012 LS_frontMatrix12 0;
BA_ "Confidence" SG_ 1012 LS_frontMatrix13 0;
BA_ "Confidence" SG_ 1012 LS_frontMatrix14 0;
BA_ "Confidence" SG_ 1012 LS_frontMatrix15 0;
BA_ "Confidence" SG_ 1012 LS_frontMatrix16 0;
BA_ "Confidence" SG_ 1012 LS_frontMatrix17 0;
BA_ "Confidence" SG_ 1012 LS_frontMatrix18 0;
BA_ "Confidence" SG_ 1012 LS_frontMatrix19 0;
BA_ "Confidence" SG_ 1012 LS_frontMatrix20 0;
BA_ "Confidence" SG_ 1012 LS_frontMatrix21 0;
BA_ "Confidence" SG_ 1012 LS_frontMatrix22 0;
BA_ "Confidence" SG_ 1012 LS_frontMatrix23 0;
BA_ "Confidence" SG_ 1012 LS_frontMatrix24 0;
BA_ "Confidence" SG_ 1012 LS_frontMatrix25 0;
BA_ "Confidence" SG_ 1012 LS_frontMatrix26 0;
BA_ "Confidence" SG_ 1012 LS_frontMatrix27 0;
BA_ "Confidence" SG_ 1012 LS_frontMatrix28 0;
BA_ "Confidence" SG_ 1012 LS_frontMatrix29 0;
BA_ "Confidence" SG_ 1012 LS_frontMatrix30 0;
BA_ "Confidence" SG_ 1012 LS_frontMatrix31 0;
BA_ "Confidence" SG_ 1012 LS_frontMatrix32 0;
BA_ "Confidence" SG_ 1012 LS_frontMatrix33 0;
BA_ "Confidence" SG_ 1012 LS_frontMatrix34 0;
BA_ "Confidence" SG_ 1012 LS_frontMatrix35 0;
BA_ "Confidence" SG_ 1012 LS_frontMatrix36 0;
BA_ "Confidence" SG_ 1012 LS_frontMatrix37 0;
BA_ "Confidence" SG_ 1012 LS_frontMatrix38 0;
BA_ "Confidence" SG_ 1012 LS_frontMatrix39 0;
BA_ "Confidence" SG_ 1012 LS_frontMatrix40 0;
BA_ "Confidence" SG_ 1012 LS_frontMatrix41 0;
BA_ "Confidence" SG_ 1012 LS_frontMatrix42 0;
BA_ "Confidence" SG_ 1012 LS_frontMatrix43 0;
BA_ "Confidence" SG_ 1012 LS_frontMatrix44 0;
BA_ "Confidence" SG_ 1012 LS_frontMatrix45 0;
BA_ "Confidence" SG_ 1012 LS_frontMatrix46 0;
BA_ "Confidence" SG_ 1012 LS_frontMatrix47 0;
BA_ "Confidence" SG_ 1012 LS_frontMatrix48 0;
BA_ "Confidence" SG_ 1012 LS_frontMatrix49 0;
BA_ "Confidence" SG_ 1012 LS_frontMatrix50 0;
BA_ "Confidence" SG_ 1012 LS_frontMatrix51 0;
BA_ "Confidence" SG_ 1012 LS_frontMatrix52 0;
BA_ "Confidence" SG_ 1012 LS_frontMatrix53 0;
BA_ "Confidence" SG_ 1012 LS_frontMatrix54 0;
BA_ "Confidence" SG_ 1012 LS_frontMatrix55 0;
BA_ "Confidence" SG_ 1012 LS_frontMatrix56 0;
BA_ "Confidence" SG_ 1012 LS_frontMatrix57 0;
BA_ "Confidence" SG_ 1012 LS_frontMatrix58 0;
BA_ "Confidence" SG_ 1012 LS_frontMatrix59 0;
BA_ "Confidence" SG_ 1012 LS_rearMatrix0 0;
BA_ "Confidence" SG_ 1012 LS_rearMatrix1 0;
BA_ "Confidence" SG_ 1012 LS_rearMatrix2 0;
BA_ "Confidence" SG_ 1012 LS_rearMatrix3 0;
BA_ "Confidence" SG_ 1012 LS_rearMatrix4 0;
BA_ "Confidence" SG_ 1012 LS_rearMatrix5 0;
BA_ "Confidence" SG_ 1012 LS_rearMatrix6 0;
BA_ "Confidence" SG_ 1012 LS_rearMatrix7 0;
BA_ "Confidence" SG_ 1012 LS_rearMatrix8 0;
BA_ "Confidence" SG_ 1012 LS_rearMatrix9 0;
BA_ "Confidence" SG_ 1012 LS_rearMatrix10 0;
BA_ "Confidence" SG_ 1012 LS_rearMatrix11 0;
BA_ "Confidence" SG_ 1012 LS_rearMatrix12 0;
BA_ "Confidence" SG_ 1012 LS_rearMatrix13 0;
BA_ "Confidence" SG_ 1012 LS_rearMatrix14 0;
BA_ "Confidence" SG_ 1012 LS_rearMatrix15 0;
BA_ "Confidence" SG_ 1012 LS_rearMatrix16 0;
BA_ "Confidence" SG_ 1012 LS_rearMatrix17 0;
BA_ "Confidence" SG_ 1012 LS_rearMatrix18 0;
BA_ "Confidence" SG_ 1012 LS_rearMatrix19 0;
BA_ "Confidence" SG_ 1012 LS_rearMatrix20 0;
BA_ "Confidence" SG_ 1012 LS_rearMatrix21 0;
BA_ "Confidence" SG_ 1012 LS_rearMatrix22 0;
BA_ "Confidence" SG_ 1012 LS_rearMatrix23 0;
BA_ "Confidence" SG_ 1012 LS_rearMatrix24 0;
BA_ "Confidence" SG_ 1012 LS_rearMatrix25 0;
BA_ "Confidence" SG_ 1012 LS_rearMatrix26 0;
BA_ "Confidence" SG_ 1012 LS_rearMatrix27 0;
BA_ "Confidence" SG_ 1012 LS_rearMatrix28 0;
BA_ "Confidence" SG_ 1012 LS_rearMatrix29 0;
BA_ "Confidence" SG_ 1012 LS_rearMatrix30 0;
BA_ "Confidence" SG_ 1012 LS_rearMatrix31 0;
BA_ "Confidence" SG_ 1012 LS_rearMatrix32 0;
BA_ "Confidence" SG_ 1012 LS_rearMatrix33 0;
BA_ "Confidence" SG_ 1012 LS_rearMatrix34 0;
BA_ "Confidence" SG_ 1012 LS_rearMatrix35 0;
BA_ "Confidence" SG_ 1012 LS_rearMatrix36 0;
BA_ "Confidence" SG_ 1012 LS_rearMatrix37 0;
BA_ "Confidence" SG_ 1012 LS_rearMatrix38 0;
BA_ "Confidence" SG_ 1012 LS_rearMatrix39 0;
BA_ "Confidence" SG_ 1012 LS_rearMatrix40 0;
BA_ "Confidence" SG_ 1012 LS_rearMatrix41 0;
BA_ "Confidence" SG_ 1012 LS_rearMatrix42 0;
BA_ "Confidence" SG_ 1012 LS_rearMatrix43 0;
BA_ "Confidence" SG_ 1012 LS_rearMatrix44 0;
BA_ "Confidence" SG_ 1012 LS_rearMatrix45 0;
BA_ "Confidence" SG_ 1012 LS_rearMatrix46 0;
BA_ "Confidence" SG_ 1012 LS_rearMatrix47 0;
BA_ "Confidence" SG_ 1012 LS_rearMatrix48 0;
BA_ "Confidence" SG_ 1012 LS_rearMatrix49 0;
BA_ "Confidence" SG_ 1012 LS_rearMatrix50 0;
BA_ "Confidence" SG_ 1012 LS_rearMatrix51 0;
BA_ "Confidence" SG_ 1012 LS_rearMatrix52 0;
BA_ "Confidence" SG_ 1012 LS_rearMatrix53 0;
BA_ "Confidence" SG_ 1012 LS_rearMatrix54 0;
BA_ "Confidence" SG_ 1012 LS_rearMatrix55 0;
BA_ "Confidence" SG_ 1012 LS_rearMatrix56 0;
BA_ "Confidence" SG_ 1012 LS_rearMatrix57 0;
BA_ "Confidence" SG_ 1012 LS_rearMatrix58 0;
BA_ "Confidence" SG_ 1012 LS_rearMatrix59 0;
BA_ "Confidence" SG_ 1012 LS_offroadLightBar0 0;
BA_ "Confidence" SG_ 1012 LS_offroadLightBar1 0;
BA_ "Confidence" SG_ 1012 LS_offroadLightBar2 0;
BA_ "Confidence" SG_ 1012 LS_offroadLightBar3 0;
BA_ "Confidence" SG_ 1012 LS_offroadLightBar4 0;
BA_ "Confidence" SG_ 1012 LS_offroadLightBar5 0;
BA_ "Confidence" SG_ 612 PCS_chgInputVoltage 0;
BA_ "Confidence" SG_ 612 PCS_chgLineCurrent 0;
BA_ "Confidence" SG_ 612 PCS_chgAcVoltagePresent 0;
BA_ "Confidence" SG_ 612 PCS_chgInputPower 0;
BA_ "Confidence" SG_ 612 PCS_chgAcCurrentLimit 0;
BA_ "Confidence" SG_ 692 PCS_dcdcLvBusVolt 0;
BA_ "Confidence" SG_ 692 PCS_dcdcHvBusVolt 0;
BA_ "Confidence" SG_ 692 PCS_dcdcLvOutputCurrent 0;
BA_ "Confidence" SG_ 964 PCS_infoIndex 1;
BA_ "Confidence" SG_ 964 PCS_buildType 0;
BA_ "Confidence" SG_ 964 PCS_buildConfigId 0;
BA_ "Confidence" SG_ 964 PCS_hardwareId 0;
BA_ "Confidence" SG_ 964 PCS_componentId 0;
BA_ "Confidence" SG_ 964 PCS_pcbaId 0;
BA_ "Confidence" SG_ 964 PCS_assemblyId 0;
BA_ "Confidence" SG_ 964 PCS_usageId 0;
BA_ "Confidence" SG_ 964 PCS_subUsageId 0;
BA_ "Confidence" SG_ 964 PCS_platformType 0;
BA_ "Confidence" SG_ 964 PCS_appCrc 0;
BA_ "Confidence" SG_ 964 PCS_cpu2AppCrc 0;
BA_ "Confidence" SG_ 964 PCS_appGitHash 0;
BA_ "Confidence" SG_ 964 PCS_bootGitHash 0;
BA_ "Confidence" SG_ 964 PCS_bootUdsProtoVersion 0;
BA_ "Confidence" SG_ 964 PCS_bootCrc 0;
BA_ "Confidence" SG_ 676 PCS_chgPhATemp 0;
BA_ "GenSigSNA" SG_ 676 PCS_chgPhATemp "1025";
BA_ "Confidence" SG_ 676 PCS_chgPhBTemp 0;
BA_ "GenSigSNA" SG_ 676 PCS_chgPhBTemp "1025";
BA_ "Confidence" SG_ 676 PCS_chgPhCTemp 0;
BA_ "GenSigSNA" SG_ 676 PCS_chgPhCTemp "1025";
BA_ "Confidence" SG_ 676 PCS_dcdcTemp 0;
BA_ "GenSigSNA" SG_ 676 PCS_dcdcTemp "1025";
BA_ "Confidence" SG_ 676 PCS_ambientTemp 0;
BA_ "GenSigSNA" SG_ 676 PCS_ambientTemp "1025";
BA_ "Confidence" SG_ 676 PCS_dcdcBusbarTemp 0;
BA_ "GenSigSNA" SG_ 676 PCS_dcdcBusbarTemp "511";
BA_ "Confidence" SG_ 790 PMF_infoIndex 1;
BA_ "Confidence" SG_ 790 PMF_buildType 0;
BA_ "Confidence" SG_ 790 PMF_buildConfigurationId 0;
BA_ "Confidence" SG_ 790 PMF_hardwareId 0;
BA_ "Confidence" SG_ 790 PMF_deviceFused 0;
BA_ "Confidence" SG_ 790 PMF_componentId 0;
BA_ "Confidence" SG_ 790 PMF_pcbaId 0;
BA_ "Confidence" SG_ 790 PMF_assemblyId 0;
BA_ "Confidence" SG_ 790 PMF_usageId 0;
BA_ "Confidence" SG_ 790 PMF_subUsageId 0;
BA_ "Confidence" SG_ 790 PMF_applicationCrc 0;
BA_ "Confidence" SG_ 790 PMF_appGitHash 0;
BA_ "Confidence" SG_ 790 PMF_bootGitHash 0;
BA_ "Confidence" SG_ 790 PMF_platformTyp 0;
BA_ "Confidence" SG_ 790 PMF_udsProtocolVersion 0;
BA_ "Confidence" SG_ 790 PMF_bootloaderCrc 0;
BA_ "Confidence" SG_ 1748 PMR_infoIndex 1;
BA_ "Confidence" SG_ 1748 PMR_buildType 0;
BA_ "Confidence" SG_ 1748 PMR_buildConfigurationId 0;
BA_ "Confidence" SG_ 1748 PMR_hardwareId 0;
BA_ "Confidence" SG_ 1748 PMR_deviceFused 0;
BA_ "Confidence" SG_ 1748 PMR_componentId 0;
BA_ "Confidence" SG_ 1748 PMR_pcbaId 0;
BA_ "Confidence" SG_ 1748 PMR_assemblyId 0;
BA_ "Confidence" SG_ 1748 PMR_usageId 0;
BA_ "Confidence" SG_ 1748 PMR_subUsageId 0;
BA_ "Confidence" SG_ 1748 PMR_applicationCrc 0;
BA_ "Confidence" SG_ 1748 PMR_appGitHash 0;
BA_ "Confidence" SG_ 1748 PMR_bootGitHash 0;
BA_ "Confidence" SG_ 1748 PMR_platformTyp 0;
BA_ "Confidence" SG_ 1748 PMR_udsProtocolVersion 0;
BA_ "Confidence" SG_ 1748 PMR_bootloaderCrc 0;
BA_ "Confidence" SG_ 1551 PM_infoIndex 1;
BA_ "Confidence" SG_ 1551 PM_buildType 0;
BA_ "Confidence" SG_ 1551 PM_buildConfigurationId 0;
BA_ "Confidence" SG_ 1551 PM_hardwareId 0;
BA_ "Confidence" SG_ 1551 PM_deviceFused 0;
BA_ "Confidence" SG_ 1551 PM_componentId 0;
BA_ "Confidence" SG_ 1551 PM_pcbaId 0;
BA_ "Confidence" SG_ 1551 PM_assemblyId 0;
BA_ "Confidence" SG_ 1551 PM_usageId 0;
BA_ "Confidence" SG_ 1551 PM_subUsageId 0;
BA_ "Confidence" SG_ 1551 PM_applicationCrc 0;
BA_ "Confidence" SG_ 1551 PM_bootGitHash 0;
BA_ "Confidence" SG_ 837 PTC_infoIndex 1;
BA_ "Confidence" SG_ 837 PTC_infoBuildType 0;
BA_ "Confidence" SG_ 837 PTC_infoBuildConfigId 0;
BA_ "Confidence" SG_ 837 PTC_infoHardwareId 0;
BA_ "Confidence" SG_ 837 PTC_infoComponentId 0;
BA_ "Confidence" SG_ 837 PTC_infoPcbaId 0;
BA_ "Confidence" SG_ 837 PTC_infoAssemblyId 0;
BA_ "GenSigSNA" SG_ 837 PTC_infoAssemblyId "255";
BA_ "Confidence" SG_ 837 PTC_infoUsageId 0;
BA_ "Confidence" SG_ 837 PTC_infoSubUsageId 0;
BA_ "Confidence" SG_ 837 PTC_infoPlatformType 0;
BA_ "Confidence" SG_ 837 PTC_infoAppCrc 0;
BA_ "Confidence" SG_ 837 PTC_infoBootUdsProtoVersion 0;
BA_ "Confidence" SG_ 837 PTC_infoBootCrc 0;
BA_ "Confidence" SG_ 647 PTC_leftTempIGBT 0;
BA_ "Confidence" SG_ 647 PTC_tempOCP 0;
BA_ "Confidence" SG_ 647 PTC_rightTempIGBT 0;
BA_ "Confidence" SG_ 647 PTC_tempPCB 0;
BA_ "Confidence" SG_ 647 PTC_voltageHV 0;
BA_ "Confidence" SG_ 647 PTC_leftCurrentHV 0;
BA_ "Confidence" SG_ 647 PTC_rightCurrentHV 0;
BA_ "Confidence" SG_ 1359 SCCM_matrixIndex 1;
BA_ "SystemSignalLongSymbol" SG_ 1359 SCCM_a026_parkButtonInvalidSigna "SCCM_a026_parkButtonInvalidSignal";
BA_ "SystemSignalLongSymbol" SG_ 1359 SCCM_a028_parkButtonShortToGroun "SCCM_a028_parkButtonShortToGround";
BA_ "SystemSignalLongSymbol" SG_ 1359 SCCM_a121_turnIndicatorAngleInva "SCCM_a121_turnIndicatorAngleInvalid";
BA_ "SystemSignalLongSymbol" SG_ 1359 SCCM_a122_turnIndicatorSpeedInva "SCCM_a122_turnIndicatorSpeedInvalid";
BA_ "SystemSignalLongSymbol" SG_ 1359 SCCM_a123_turnIndicatorStuckActi "SCCM_a123_turnIndicatorStuckActive";
BA_ "SystemSignalLongSymbol" SG_ 1359 SCCM_a124_turnIndicatorIdleInval "SCCM_a124_turnIndicatorIdleInvalid";
BA_ "SystemSignalLongSymbol" SG_ 1359 SCCM_a125_turnIndicatorHallAngle "SCCM_a125_turnIndicatorHallAngleMismatch";
BA_ "SystemSignalLongSymbol" SG_ 1359 SCCM_a126_turnIndicatorHallMagOu "SCCM_a126_turnIndicatorHallMagOutOfRange";
BA_ "Confidence" SG_ 816 SCCM_infoIndex 1;
BA_ "Confidence" SG_ 816 SCCM_infoBuildType 0;
BA_ "Confidence" SG_ 816 SCCM_infoBuildConfigId 0;
BA_ "Confidence" SG_ 816 SCCM_infoHardwareId 0;
BA_ "Confidence" SG_ 816 SCCM_infoComponentId 0;
BA_ "Confidence" SG_ 816 SCCM_infoPcbaId 0;
BA_ "Confidence" SG_ 816 SCCM_infoAssemblyId 0;
BA_ "Confidence" SG_ 816 SCCM_infoUsageId 0;
BA_ "Confidence" SG_ 816 SCCM_infoSubUsageId 0;
BA_ "Confidence" SG_ 816 SCCM_infoPlatformType 0;
BA_ "Confidence" SG_ 816 SCCM_infoBootSvnRev 0;
BA_ "Confidence" SG_ 816 SCCM_infoBootSvnUrlHash 0;
BA_ "Confidence" SG_ 816 SCCM_infoSubcomponent1Version 0;
BA_ "Confidence" SG_ 816 SCCM_infoAppSvnHash 0;
BA_ "Confidence" SG_ 816 SCCM_infoBootSvnHash 0;
BA_ "Confidence" SG_ 816 SCCM_infoUdsProtoVersion 0;
BA_ "Confidence" SG_ 816 SCCM_infoBootCrc 0;
BA_ "Confidence" SG_ 585 SCCM_leftStalkCrc 0;
BA_ "Confidence" SG_ 585 SCCM_leftStalkCounter 0;
BA_ "Confidence" SG_ 585 SCCM_highBeamStalkStatus 0;
BA_ "GenSigSNA" SG_ 585 SCCM_highBeamStalkStatus "3";
BA_ "Confidence" SG_ 585 SCCM_washWipeButtonStatus 0;
BA_ "GenSigSNA" SG_ 585 SCCM_washWipeButtonStatus "3";
BA_ "Confidence" SG_ 585 SCCM_turnIndicatorStalkStatus 0;
BA_ "GenSigSNA" SG_ 585 SCCM_turnIndicatorStalkStatus "9";
BA_ "Confidence" SG_ 585 SCCM_turnIndicatorStalkAngle 0;
BA_ "GenSigSNA" SG_ 585 SCCM_turnIndicatorStalkAngle "4095";
BA_ "Confidence" SG_ 553 SCCM_rightStalkCrc 0;
BA_ "Confidence" SG_ 553 SCCM_rightStalkCounter 0;
BA_ "Confidence" SG_ 553 SCCM_rightStalkStatus 0;
BA_ "GenSigSNA" SG_ 553 SCCM_rightStalkStatus "6";
BA_ "Confidence" SG_ 553 SCCM_rightStalkReserved1 0;
BA_ "Confidence" SG_ 553 SCCM_parkButtonStatus 0;
BA_ "GenSigSNA" SG_ 553 SCCM_parkButtonStatus "3";
BA_ "Confidence" SG_ 553 SCCM_rightStalkReserved2 0;
BA_ "Confidence" SG_ 297 SCCM_steeringAngleCrc 0;
BA_ "Confidence" SG_ 297 SCCM_steeringAngleCounter 0;
BA_ "Confidence" SG_ 297 SCCM_supplierID 0;
BA_ "Confidence" SG_ 297 SCCM_steeringAngleSensorStatus 0;
BA_ "Confidence" SG_ 297 SCCM_steeringAngle 0;
BA_ "GenSigSNA" SG_ 297 SCCM_steeringAngle "16383";
BA_ "Confidence" SG_ 297 SCCM_steeringAngleValidity 0;
BA_ "GenSigSNA" SG_ 297 SCCM_steeringAngleValidity "3";
BA_ "Confidence" SG_ 297 SCCM_steeringAngleSpeed 0;
BA_ "Confidence" SG_ 297 SCCM_steeringAngleSensorReservd1 0;
BA_ "Confidence" SG_ 297 SCCM_steeringAngleSensorReservd2 0;
BA_ "Confidence" SG_ 297 SCCM_steeringAngleSensorReservd3 0;
BA_ "Confidence" SG_ 1356 SCM_alertID 1;
BA_ "Confidence" SG_ 1356 SCM_alertType 1;
BA_ "Confidence" SG_ 1354 SCS_alertID 1;
BA_ "Confidence" SG_ 1354 SCS_alertType 1;
BA_ "Confidence" SG_ 1354 SCS_a044_proximityV 1;
BA_ "Confidence" SG_ 1354 SCS_a074_voltageWithRo 1;
BA_ "Confidence" SG_ 1354 SCS_a074_voltageWithoutRo 1;
BA_ "Confidence" SG_ 1467 SDCR_matrixIndex 1;
BA_ "SystemSignalLongSymbol" SG_ 1467 SDCR_a004_pmRunningFdbkIrrationa "SDCR_a004_pmRunningFdbkIrrational";
BA_ "SystemSignalLongSymbol" SG_ 1467 SDCR_a019_historicalFaultCurrent "SDCR_a019_historicalFaultCurrents";
BA_ "SystemSignalLongSymbol" SG_ 1467 SDCR_a025_diSwitchingFdbkIrratio "SDCR_a025_diSwitchingFdbkIrrational";
BA_ "SystemSignalLongSymbol" SG_ 1467 SDCR_a026_faultCurrentMonitoring "SDCR_a026_faultCurrentMonitoringDisabled";
BA_ "Confidence" SG_ 1597 SDCR_infoIndex 1;
BA_ "Confidence" SG_ 1597 SDCR_infoBuildType 1;
BA_ "Confidence" SG_ 1597 SDCR_infoBuildConfigId 0;
BA_ "Confidence" SG_ 1597 SDCR_infoHardwareId 0;
BA_ "Confidence" SG_ 1597 SDCR_infoSubUsageId 0;
BA_ "Confidence" SG_ 1597 SDCR_infoBootGitHash 0;
BA_ "Confidence" SG_ 792 UTC_year 0;
BA_ "Confidence" SG_ 792 UTC_month 0;
BA_ "Confidence" SG_ 792 UTC_seconds 0;
BA_ "Confidence" SG_ 792 UTC_hour 0;
BA_ "Confidence" SG_ 792 UTC_day 0;
BA_ "Confidence" SG_ 792 UTC_minutes 0;
BA_ "Confidence" SG_ 523 TAS_axleIndex 1;
BA_ "Confidence" SG_ 523 TAS_rawHeightFL 0;
BA_ "GenSigSNA" SG_ 523 TAS_rawHeightFL "1023";
BA_ "Confidence" SG_ 523 TAS_staticHeightEstimateFL 0;
BA_ "GenSigSNA" SG_ 523 TAS_staticHeightEstimateFL "1023";
BA_ "Confidence" SG_ 523 TAS_componentPressureFL 0;
BA_ "GenSigSNA" SG_ 523 TAS_componentPressureFL "255";
BA_ "Confidence" SG_ 523 TAS_rawHeightFR 0;
BA_ "GenSigSNA" SG_ 523 TAS_rawHeightFR "1023";
BA_ "Confidence" SG_ 523 TAS_staticHeightEstimateFR 0;
BA_ "GenSigSNA" SG_ 523 TAS_staticHeightEstimateFR "1023";
BA_ "Confidence" SG_ 523 TAS_componentPressureFR 0;
BA_ "GenSigSNA" SG_ 523 TAS_componentPressureFR "255";
BA_ "Confidence" SG_ 523 TAS_rawHeightRL 0;
BA_ "GenSigSNA" SG_ 523 TAS_rawHeightRL "1023";
BA_ "Confidence" SG_ 523 TAS_staticHeightEstimateRL 0;
BA_ "GenSigSNA" SG_ 523 TAS_staticHeightEstimateRL "1023";
BA_ "Confidence" SG_ 523 TAS_componentPressureRL 0;
BA_ "GenSigSNA" SG_ 523 TAS_componentPressureRL "255";
BA_ "Confidence" SG_ 523 TAS_rawHeightRR 0;
BA_ "GenSigSNA" SG_ 523 TAS_rawHeightRR "1023";
BA_ "Confidence" SG_ 523 TAS_staticHeightEstimateRR 0;
BA_ "GenSigSNA" SG_ 523 TAS_staticHeightEstimateRR "1023";
BA_ "Confidence" SG_ 523 TAS_componentPressureRR 0;
BA_ "GenSigSNA" SG_ 523 TAS_componentPressureRR "255";
BA_ "Confidence" SG_ 1398 TAS_endstopState 0;
BA_ "Confidence" SG_ 1398 TAS_continuousControlState 0;
BA_ "Confidence" SG_ 1398 TAS_activeTireTune 0;
BA_ "Confidence" SG_ 1398 TAS_roughnessRaiseReason 0;
BA_ "Confidence" SG_ 1398 TAS_frontMetricDrivesRear 0;
BA_ "Confidence" SG_ 1398 TAS_roadCondition 0;
BA_ "GenSigSNA" SG_ 1398 TAS_roadCondition "255";
BA_ "Confidence" SG_ 1398 TAS_bellyProtect 0;
BA_ "Confidence" SG_ 1398 TAS_frontMetricDrivesFront 0;
BA_ "Confidence" SG_ 1398 TAS_speedBumpAxleFront 0;
BA_ "Confidence" SG_ 1398 TAS_speedBumpAxleRear 0;
BA_ "Confidence" SG_ 1398 TAS_holeProtectFL 0;
BA_ "Confidence" SG_ 1398 TAS_holeProtectFR 0;
BA_ "Confidence" SG_ 1398 TAS_holeProtectRL 0;
BA_ "Confidence" SG_ 1398 TAS_holeProtectRR 0;
BA_ "Confidence" SG_ 1398 TAS_stepProtectFL 0;
BA_ "Confidence" SG_ 1398 TAS_stepProtectFR 0;
BA_ "Confidence" SG_ 1398 TAS_stepProtectRL 0;
BA_ "Confidence" SG_ 1398 TAS_stepProtectRR 0;
BA_ "Confidence" SG_ 1398 TAS_FDUTorqueCorruptionScale 0;
BA_ "GenSigSNA" SG_ 1398 TAS_FDUTorqueCorruptionScale "15";
BA_ "Confidence" SG_ 1398 TAS_sprungMassEstimate 0;
BA_ "GenSigSNA" SG_ 1398 TAS_sprungMassEstimate "31";
BA_ "Confidence" SG_ 1398 TAS_anyDamperActive 0;
BA_ "Confidence" SG_ 1398 TAS_dampingStatesCounter 0;
BA_ "Confidence" SG_ 1398 TAS_dampingStatesChecksum 0;
BA_ "Confidence" SG_ 1357 TAS_infoIndex 1;
BA_ "Confidence" SG_ 1357 TAS_infoBuildType 0;
BA_ "Confidence" SG_ 1357 TAS_infoBuildConfigId 0;
BA_ "Confidence" SG_ 1357 TAS_infoHardwareId 0;
BA_ "Confidence" SG_ 1357 TAS_infoComponentId 0;
BA_ "Confidence" SG_ 1357 TAS_infoPcbaId 0;
BA_ "Confidence" SG_ 1357 TAS_infoAssemblyId 0;
BA_ "GenSigSNA" SG_ 1357 TAS_infoAssemblyId "255";
BA_ "Confidence" SG_ 1357 TAS_infoUsageId 0;
BA_ "Confidence" SG_ 1357 TAS_infoSubUsageId 0;
BA_ "Confidence" SG_ 1357 TAS_infoAppCrc 0;
BA_ "Confidence" SG_ 1357 TAS_infoAppGitHash 0;
BA_ "Confidence" SG_ 1357 TAS_infoBootGitHash 0;
BA_ "Confidence" SG_ 1357 TAS_infoPlatformType 0;
BA_ "Confidence" SG_ 1357 TAS_infoMajorVersion 0;
BA_ "GenSigSNA" SG_ 1357 TAS_infoMajorVersion "255";
BA_ "Confidence" SG_ 1357 TAS_infoBranchOrigin 0;
BA_ "GenSigSNA" SG_ 1357 TAS_infoBranchOrigin "255";
BA_ "Confidence" SG_ 1357 TAS_infoMaturity 0;
BA_ "GenSigSNA" SG_ 1357 TAS_infoMaturity "255";
BA_ "Confidence" SG_ 1357 TAS_infoHardwareRevision 0;
BA_ "GenSigSNA" SG_ 1357 TAS_infoHardwareRevision "255";
BA_ "Confidence" SG_ 525 TAS_levelingState 0;
BA_ "Confidence" SG_ 525 TAS_levelingItem 0;
BA_ "Confidence" SG_ 525 TAS_pressureGallery 0;
BA_ "GenSigSNA" SG_ 525 TAS_pressureGallery "255";
BA_ "Confidence" SG_ 525 TAS_pressureReservoir 0;
BA_ "GenSigSNA" SG_ 525 TAS_pressureReservoir "255";
BA_ "Confidence" SG_ 525 TAS_runMode 0;
BA_ "Confidence" SG_ 525 TAS_filterMode 0;
BA_ "Confidence" SG_ 525 TAS_compressorRun 0;
BA_ "Confidence" SG_ 525 TAS_twistDetected 0;
BA_ "Confidence" SG_ 525 TAS_leanDetected 0;
BA_ "Confidence" SG_ 525 TAS_limpHomeMode 0;
BA_ "Confidence" SG_ 525 TAS_targetLevel 0;
BA_ "Confidence" SG_ 525 TAS_currentLevel 0;
BA_ "Confidence" SG_ 525 TAS_jackMode 0;
BA_ "Confidence" SG_ 525 TAS_reduceVehicleSpeedRequest 0;
BA_ "Confidence" SG_ 525 TAS_statesCounter 0;
BA_ "Confidence" SG_ 525 TAS_statesChecksum 0;
BA_ "Confidence" SG_ 409 TAS_adaptiveActivityFL_C 0;
BA_ "GenSigSNA" SG_ 409 TAS_adaptiveActivityFL_C "31";
BA_ "Confidence" SG_ 409 TAS_adaptiveActivityFL_R 0;
BA_ "GenSigSNA" SG_ 409 TAS_adaptiveActivityFL_R "31";
BA_ "Confidence" SG_ 409 TAS_adaptiveActivityFR_C 0;
BA_ "GenSigSNA" SG_ 409 TAS_adaptiveActivityFR_C "31";
BA_ "Confidence" SG_ 409 TAS_adaptiveActivityFR_R 0;
BA_ "GenSigSNA" SG_ 409 TAS_adaptiveActivityFR_R "31";
BA_ "Confidence" SG_ 409 TAS_adaptiveActivityRL_C 0;
BA_ "GenSigSNA" SG_ 409 TAS_adaptiveActivityRL_C "31";
BA_ "Confidence" SG_ 409 TAS_adaptiveActivityRL_R 0;
BA_ "GenSigSNA" SG_ 409 TAS_adaptiveActivityRL_R "31";
BA_ "Confidence" SG_ 409 TAS_adaptiveActivityRR_C 0;
BA_ "GenSigSNA" SG_ 409 TAS_adaptiveActivityRR_C "31";
BA_ "Confidence" SG_ 409 TAS_adaptiveActivityRR_R 0;
BA_ "GenSigSNA" SG_ 409 TAS_adaptiveActivityRR_R "31";
BA_ "Confidence" SG_ 409 TAS_uiHeightFL 0;
BA_ "GenSigSNA" SG_ 409 TAS_uiHeightFL "63";
BA_ "Confidence" SG_ 409 TAS_uiHeightFR 0;
BA_ "GenSigSNA" SG_ 409 TAS_uiHeightFR "63";
BA_ "Confidence" SG_ 409 TAS_uiHeightRL 0;
BA_ "GenSigSNA" SG_ 409 TAS_uiHeightRL "63";
BA_ "Confidence" SG_ 409 TAS_uiHeightRR 0;
BA_ "GenSigSNA" SG_ 409 TAS_uiHeightRR "63";
BA_ "Confidence" SG_ 410 TAS_bodyAccelFL 0;
BA_ "GenSigSNA" SG_ 410 TAS_bodyAccelFL "255";
BA_ "Confidence" SG_ 410 TAS_bodyAccelFR 0;
BA_ "GenSigSNA" SG_ 410 TAS_bodyAccelFR "255";
BA_ "Confidence" SG_ 410 TAS_bodyAccelRL 0;
BA_ "GenSigSNA" SG_ 410 TAS_bodyAccelRL "255";
BA_ "Confidence" SG_ 410 TAS_bodyAccelRR 0;
BA_ "GenSigSNA" SG_ 410 TAS_bodyAccelRR "255";
BA_ "Confidence" SG_ 538 TAS_yellowWarningLamp 0;
BA_ "Confidence" SG_ 538 TAS_redWarningLamp 0;
BA_ "Confidence" SG_ 538 TAS_veryLowAllowed 0;
BA_ "Confidence" SG_ 538 TAS_lowAllowed 0;
BA_ "Confidence" SG_ 538 TAS_standardAllowed 0;
BA_ "Confidence" SG_ 538 TAS_highAllowed 0;
BA_ "Confidence" SG_ 538 TAS_veryHighAllowed 0;
BA_ "Confidence" SG_ 538 TAS_extractAllowed 0;
BA_ "Confidence" SG_ 538 TAS_showSpinner 0;
BA_ "Confidence" SG_ 538 TAS_adaptiveRideModeOverride 0;
BA_ "GenSigSNA" SG_ 538 TAS_adaptiveRideModeOverride "3";
BA_ "Confidence" SG_ 538 TAS_levelSelectEnabled 0;
BA_ "Confidence" SG_ 538 TAS_jackModeToggleEnabled 0;
BA_ "Confidence" SG_ 538 TAS_adaptiveRideSelectEnabled 0;
BA_ "Confidence" SG_ 538 TAS_launchModeState 0;
BA_ "Confidence" SG_ 538 TAS_restrictUpLevelingFalcons 0;
BA_ "Confidence" SG_ 538 TAS_restrictUpLevelingTrunk 0;
BA_ "Confidence" SG_ 538 TAS_restrictDownLevelingDoors 0;
BA_ "Confidence" SG_ 538 TAS_restrictLevelingChargeCable 0;
BA_ "Confidence" SG_ 538 TAS_restrictLevelingSystemCheck 0;
BA_ "Confidence" SG_ 538 TAS_restrictLevelingTransport 0;
BA_ "Confidence" SG_ 538 TAS_restrictLevelingShowroom 0;
BA_ "Confidence" SG_ 538 TAS_uiControlCounter 0;
BA_ "Confidence" SG_ 538 TAS_uiControlChecksum 0;
BA_ "Confidence" SG_ 659 UI_steeringTuneRequest 0;
BA_ "Confidence" SG_ 659 UI_tractionControlMode 0;
BA_ "Confidence" SG_ 659 UI_parkBrakeRequest 0;
BA_ "GenSigSNA" SG_ 659 UI_parkBrakeRequest "3";
BA_ "Confidence" SG_ 659 UI_narrowGarages 1;
BA_ "Confidence" SG_ 659 UI_winchModeRequest 0;
BA_ "Confidence" SG_ 659 UI_zeroSpeedConfirmed 1;
BA_ "GenSigSNA" SG_ 659 UI_zeroSpeedConfirmed "3";
BA_ "Confidence" SG_ 659 UI_trailerMode 0;
BA_ "Confidence" SG_ 659 UI_distanceUnits 1;
BA_ "Confidence" SG_ 659 UI_dasDebugEnable 1;
BA_ "Confidence" SG_ 659 UI_accOvertakeEnable 0;
BA_ "GenSigSNA" SG_ 659 UI_accOvertakeEnable "3";
BA_ "Confidence" SG_ 659 UI_aebEnable 0;
BA_ "GenSigSNA" SG_ 659 UI_aebEnable "3";
BA_ "Confidence" SG_ 659 UI_aesEnable 0;
BA_ "GenSigSNA" SG_ 659 UI_aesEnable "3";
BA_ "Confidence" SG_ 659 UI_ahlbEnable 0;
BA_ "GenSigSNA" SG_ 659 UI_ahlbEnable "3";
BA_ "Confidence" SG_ 659 UI_autoLaneChangeEnable 0;
BA_ "GenSigSNA" SG_ 659 UI_autoLaneChangeEnable "3";
BA_ "Confidence" SG_ 659 UI_winchProxUserOverride 0;
BA_ "Confidence" SG_ 659 UI_rebootAutopilot 1;
BA_ "Confidence" SG_ 659 UI_autoParkRequest 0;
BA_ "GenSigSNA" SG_ 659 UI_autoParkRequest "15";
BA_ "Confidence" SG_ 659 UI_bsdEnable 0;
BA_ "GenSigSNA" SG_ 659 UI_bsdEnable "3";
BA_ "Confidence" SG_ 659 UI_fcwEnable 0;
BA_ "GenSigSNA" SG_ 659 UI_fcwEnable "3";
BA_ "Confidence" SG_ 659 UI_fcwSensitivity 0;
BA_ "GenSigSNA" SG_ 659 UI_fcwSensitivity "3";
BA_ "Confidence" SG_ 659 UI_latControlEnable 0;
BA_ "GenSigSNA" SG_ 659 UI_latControlEnable "3";
BA_ "Confidence" SG_ 659 UI_ldwEnable 0;
BA_ "GenSigSNA" SG_ 659 UI_ldwEnable "3";
BA_ "Confidence" SG_ 659 UI_pedalSafetyEnable 1;
BA_ "GenSigSNA" SG_ 659 UI_pedalSafetyEnable "3";
BA_ "Confidence" SG_ 659 UI_pedalMap_epas 1;
BA_ "Confidence" SG_ 659 UI_redLightStopSignEnable 1;
BA_ "GenSigSNA" SG_ 659 UI_redLightStopSignEnable "3";
BA_ "Confidence" SG_ 659 UI_selfParkTune 1;
BA_ "GenSigSNA" SG_ 659 UI_selfParkTune "15";
BA_ "Confidence" SG_ 659 UI_chassisControlCounter 1;
BA_ "Confidence" SG_ 659 UI_chassisControlChecksum 0;
BA_ "Confidence" SG_ 1280 UI_debugEcuTarget 1;
BA_ "Confidence" SG_ 2043 UI_debugDampingRequestFLC 1;
BA_ "GenSigSNA" SG_ 2043 UI_debugDampingRequestFLC "255";
BA_ "Confidence" SG_ 2043 UI_debugDampingRequestFLR 1;
BA_ "GenSigSNA" SG_ 2043 UI_debugDampingRequestFLR "255";
BA_ "Confidence" SG_ 2043 UI_debugDampingRequestFRC 1;
BA_ "GenSigSNA" SG_ 2043 UI_debugDampingRequestFRC "255";
BA_ "Confidence" SG_ 2043 UI_debugDampingRequestFRR 1;
BA_ "GenSigSNA" SG_ 2043 UI_debugDampingRequestFRR "255";
BA_ "Confidence" SG_ 2043 UI_debugDampingRequestRLC 1;
BA_ "GenSigSNA" SG_ 2043 UI_debugDampingRequestRLC "255";
BA_ "Confidence" SG_ 2043 UI_debugDampingRequestRLR 1;
BA_ "GenSigSNA" SG_ 2043 UI_debugDampingRequestRLR "255";
BA_ "Confidence" SG_ 2043 UI_debugDampingRequestRRC 1;
BA_ "GenSigSNA" SG_ 2043 UI_debugDampingRequestRRC "255";
BA_ "Confidence" SG_ 2043 UI_debugDampingRequestRRR 1;
BA_ "GenSigSNA" SG_ 2043 UI_debugDampingRequestRRR "255";
BA_ "Confidence" SG_ 568 UI_mapSpeedLimitDependency 1;
BA_ "GenSigSNA" SG_ 568 UI_mapSpeedLimitDependency "7";
BA_ "Confidence" SG_ 568 UI_roadClass 0;
BA_ "GenSigSNA" SG_ 568 UI_roadClass "0";
BA_ "Confidence" SG_ 568 UI_inSuperchargerGeofence 1;
BA_ "Confidence" SG_ 568 UI_mapSpeedUnits 1;
BA_ "Confidence" SG_ 568 UI_mapSpeedLimit 1;
BA_ "GenSigSNA" SG_ 568 UI_mapSpeedLimit "31";
BA_ "Confidence" SG_ 568 UI_mapSpeedLimitType 1;
BA_ "GenSigSNA" SG_ 568 UI_mapSpeedLimitType "7";
BA_ "Confidence" SG_ 568 UI_countryCode 1;
BA_ "GenSigSNA" SG_ 568 UI_countryCode "1023";
BA_ "Confidence" SG_ 568 UI_streetCount 1;
BA_ "Confidence" SG_ 568 UI_gpsRoadMatch 1;
BA_ "Confidence" SG_ 568 UI_navRouteActive 0;
BA_ "Confidence" SG_ 568 UI_parallelAutoparkEnabled 0;
BA_ "Confidence" SG_ 568 UI_perpendicularAutoparkEnabled 0;
BA_ "Confidence" SG_ 568 UI_nextBranchDist 1;
BA_ "GenSigSNA" SG_ 568 UI_nextBranchDist "31";
BA_ "Confidence" SG_ 568 UI_controlledAccess 0;
BA_ "Confidence" SG_ 568 UI_nextBranchLeftOffRamp 1;
BA_ "Confidence" SG_ 568 UI_nextBranchRightOffRamp 1;
BA_ "Confidence" SG_ 568 UI_rejectLeftLane 1;
BA_ "Confidence" SG_ 568 UI_rejectRightLane 1;
BA_ "Confidence" SG_ 568 UI_rejectHPP 1;
BA_ "Confidence" SG_ 568 UI_rejectNav 1;
BA_ "Confidence" SG_ 568 UI_rejectLeftFreeSpace 1;
BA_ "Confidence" SG_ 568 UI_rejectRightFreeSpace 1;
BA_ "Confidence" SG_ 568 UI_rejectAutosteer 1;
BA_ "Confidence" SG_ 568 UI_rejectHandsOn 1;
BA_ "Confidence" SG_ 568 UI_acceptBottsDots 1;
BA_ "Confidence" SG_ 568 UI_autosteerRestricted 0;
BA_ "Confidence" SG_ 568 UI_pmmEnabled 1;
BA_ "Confidence" SG_ 568 UI_scaEnabled 1;
BA_ "Confidence" SG_ 568 UI_mapDataCounter 1;
BA_ "Confidence" SG_ 568 UI_mapDataChecksum 0;
BA_ "Confidence" SG_ 651 UI_driverProfileLinkedKeySHA1 1;
BA_ "GenSigSNA" SG_ 651 UI_driverProfileLinkedKeySHA1 "4294967295";
BA_ "Confidence" SG_ 651 UI_driverProfileIndex 0;
BA_ "Confidence" SG_ 651 UI_driverProfileSelectionType 0;
BA_ "Confidence" SG_ 651 UI_driverProfilePositionAdjusted 0;
BA_ "Confidence" SG_ 651 UI_activeKeyRequested 0;
BA_ "Confidence" SG_ 984 UI_elevation 1;
BA_ "GenSigSNA" SG_ 984 UI_elevation "8191";
BA_ "Confidence" SG_ 984 UI_navElevation 1;
BA_ "GenSigSNA" SG_ 984 UI_navElevation "8191";
BA_ "Confidence" SG_ 804 UI_gpsTime 1;
BA_ "Confidence" SG_ 883 UI_gpsHDOP 1;
BA_ "Confidence" SG_ 883 UI_gpsVehicleHeading 1;
BA_ "Confidence" SG_ 883 UI_gpsVehicleSpeed 1;
BA_ "Confidence" SG_ 883 UI_userSpeedOffset 1;
BA_ "Confidence" SG_ 883 UI_mapSpeedLimitUnits 0;
BA_ "Confidence" SG_ 883 UI_userSpeedOffsetUnits 1;
BA_ "Confidence" SG_ 883 UI_mppSpeedLimit 0;
BA_ "Confidence" SG_ 883 UI_gpsNmeaMIA 0;
BA_ "Confidence" SG_ 883 UI_gpsAntennaDisconnected 0;
BA_ "Confidence" SG_ 883 UI_conditionalLimitActive 0;
BA_ "Confidence" SG_ 883 UI_conditionalSpeedLimit 0;
BA_ "GenSigSNA" SG_ 883 UI_conditionalSpeedLimit "31";
VAL_ 1012 LS_lightShowIndex 24 "LightShowMux24" 23 "LightShowMux23" 22 "LightShowMux22" 21 "LightShowMux21" 20 "LightShowMux20" 19 "LightShowMux19" 18 "LightShowMux18" 17 "LightShowMux17" 16 "LightShowMux16" 15 "LightShowMux15" 14 "LightShowMux14" 13 "LightShowMux13" 12 "LightShowMux12" 11 "LightShowMux11" 10 "LightShowMux10" 9 "LightShowMux9" 8 "LightShowMux8" 7 "LightShowMux7" 6 "LightShowMux6" 5 "LightShowMux5" 4 "LightShowMux4" 3 "LightShowMux3" 2 "LightShowMux2" 1 "LightShowMux1" 0 "LightShowMux0" ;
VAL_ 1012 LS_lightLeftRampedChannel1Durati 3 "TWO_SECONDS" 2 "ONE_SECOND" 1 "HALF_SECOND" 0 "INSTANT" ;
VAL_ 1012 LS_lightLeftRampedChannel2Durati 3 "TWO_SECONDS" 2 "ONE_SECOND" 1 "HALF_SECOND" 0 "INSTANT" ;
VAL_ 1012 LS_lightLeftRampedChannel3Durati 3 "TWO_SECONDS" 2 "ONE_SECOND" 1 "HALF_SECOND" 0 "INSTANT" ;
VAL_ 1012 LS_lightLeftRampedChannel4Durati 3 "TWO_SECONDS" 2 "ONE_SECOND" 1 "HALF_SECOND" 0 "INSTANT" ;
VAL_ 1012 LS_lightLeftRampedChannel5Durati 3 "TWO_SECONDS" 2 "ONE_SECOND" 1 "HALF_SECOND" 0 "INSTANT" ;
VAL_ 1012 LS_lightLeftRampedChannel6Durati 3 "TWO_SECONDS" 2 "ONE_SECOND" 1 "HALF_SECOND" 0 "INSTANT" ;
VAL_ 1012 LS_lightLeftRampedChannel7Durati 3 "TWO_SECONDS" 2 "ONE_SECOND" 1 "HALF_SECOND" 0 "INSTANT" ;
VAL_ 1012 LS_lightRightRampedChannel1Durat 3 "TWO_SECONDS" 2 "ONE_SECOND" 1 "HALF_SECOND" 0 "INSTANT" ;
VAL_ 1012 LS_lightRightRampedChannel2Durat 3 "TWO_SECONDS" 2 "ONE_SECOND" 1 "HALF_SECOND" 0 "INSTANT" ;
VAL_ 1012 LS_lightRightRampedChannel3Durat 3 "TWO_SECONDS" 2 "ONE_SECOND" 1 "HALF_SECOND" 0 "INSTANT" ;
VAL_ 1012 LS_lightRightRampedChannel4Durat 3 "TWO_SECONDS" 2 "ONE_SECOND" 1 "HALF_SECOND" 0 "INSTANT" ;
VAL_ 1012 LS_lightRightRampedChannel5Durat 3 "TWO_SECONDS" 2 "ONE_SECOND" 1 "HALF_SECOND" 0 "INSTANT" ;
VAL_ 1012 LS_lightRightRampedChannel6Durat 3 "TWO_SECONDS" 2 "ONE_SECOND" 1 "HALF_SECOND" 0 "INSTANT" ;
VAL_ 1012 LS_lightRightRampedChannel7Durat 3 "TWO_SECONDS" 2 "ONE_SECOND" 1 "HALF_SECOND" 0 "INSTANT" ;
VAL_ 1012 LS_mirrorRequestLeft 4 "HOLIDAY_PARTY_STOP" 3 "HOLIDAY_PARTY_CLOSE" 2 "HOLIDAY_PARTY_DANCE" 1 "HOLIDAY_PARTY_OPEN" 0 "HOLIDAY_PARTY_IDLE" ;
VAL_ 1012 LS_mirrorRequestRight 4 "HOLIDAY_PARTY_STOP" 3 "HOLIDAY_PARTY_CLOSE" 2 "HOLIDAY_PARTY_DANCE" 1 "HOLIDAY_PARTY_OPEN" 0 "HOLIDAY_PARTY_IDLE" ;
VAL_ 1012 LS_liftgateRequest 4 "HOLIDAY_PARTY_STOP" 3 "HOLIDAY_PARTY_CLOSE" 2 "HOLIDAY_PARTY_DANCE" 1 "HOLIDAY_PARTY_OPEN" 0 "HOLIDAY_PARTY_IDLE" ;
VAL_ 1012 LS_windowRequestLF 4 "HOLIDAY_PARTY_STOP" 3 "HOLIDAY_PARTY_CLOSE" 2 "HOLIDAY_PARTY_DANCE" 1 "HOLIDAY_PARTY_OPEN" 0 "HOLIDAY_PARTY_IDLE" ;
VAL_ 1012 LS_windowRequestLR 4 "HOLIDAY_PARTY_STOP" 3 "HOLIDAY_PARTY_CLOSE" 2 "HOLIDAY_PARTY_DANCE" 1 "HOLIDAY_PARTY_OPEN" 0 "HOLIDAY_PARTY_IDLE" ;
VAL_ 1012 LS_windowRequestRF 4 "HOLIDAY_PARTY_STOP" 3 "HOLIDAY_PARTY_CLOSE" 2 "HOLIDAY_PARTY_DANCE" 1 "HOLIDAY_PARTY_OPEN" 0 "HOLIDAY_PARTY_IDLE" ;
VAL_ 1012 LS_windowRequestRR 4 "HOLIDAY_PARTY_STOP" 3 "HOLIDAY_PARTY_CLOSE" 2 "HOLIDAY_PARTY_DANCE" 1 "HOLIDAY_PARTY_OPEN" 0 "HOLIDAY_PARTY_IDLE" ;
VAL_ 1012 LS_presentingHandleRequestLF 4 "HOLIDAY_PARTY_STOP" 3 "HOLIDAY_PARTY_CLOSE" 2 "HOLIDAY_PARTY_DANCE" 1 "HOLIDAY_PARTY_OPEN" 0 "HOLIDAY_PARTY_IDLE" ;
VAL_ 1012 LS_presentingHandleRequestLR 4 "HOLIDAY_PARTY_STOP" 3 "HOLIDAY_PARTY_CLOSE" 2 "HOLIDAY_PARTY_DANCE" 1 "HOLIDAY_PARTY_OPEN" 0 "HOLIDAY_PARTY_IDLE" ;
VAL_ 1012 LS_presentingHandleRequestRF 4 "HOLIDAY_PARTY_STOP" 3 "HOLIDAY_PARTY_CLOSE" 2 "HOLIDAY_PARTY_DANCE" 1 "HOLIDAY_PARTY_OPEN" 0 "HOLIDAY_PARTY_IDLE" ;
VAL_ 1012 LS_presentingHandleRequestRR 4 "HOLIDAY_PARTY_STOP" 3 "HOLIDAY_PARTY_CLOSE" 2 "HOLIDAY_PARTY_DANCE" 1 "HOLIDAY_PARTY_OPEN" 0 "HOLIDAY_PARTY_IDLE" ;
VAL_ 1012 LS_powerFrontDoorRequestLeft 4 "HOLIDAY_PARTY_STOP" 3 "HOLIDAY_PARTY_CLOSE" 2 "HOLIDAY_PARTY_DANCE" 1 "HOLIDAY_PARTY_OPEN" 0 "HOLIDAY_PARTY_IDLE" ;
VAL_ 1012 LS_powerFrontDoorRequestRight 4 "HOLIDAY_PARTY_STOP" 3 "HOLIDAY_PARTY_CLOSE" 2 "HOLIDAY_PARTY_DANCE" 1 "HOLIDAY_PARTY_OPEN" 0 "HOLIDAY_PARTY_IDLE" ;
VAL_ 1012 LS_falconDoorRequestLeft 4 "HOLIDAY_PARTY_STOP" 3 "HOLIDAY_PARTY_CLOSE" 2 "HOLIDAY_PARTY_DANCE" 1 "HOLIDAY_PARTY_OPEN" 0 "HOLIDAY_PARTY_IDLE" ;
VAL_ 1012 LS_falconDoorRequestRight 4 "HOLIDAY_PARTY_STOP" 3 "HOLIDAY_PARTY_CLOSE" 2 "HOLIDAY_PARTY_DANCE" 1 "HOLIDAY_PARTY_OPEN" 0 "HOLIDAY_PARTY_IDLE" ;
VAL_ 1012 LS_chargePortRequest 3 "REQUEST_SNA" 2 "REQUEST_CLOSE" 1 "REQUEST_OPEN" 0 "REQUEST_NONE" ;
VAL_ 1012 LS_suspensionRequest 3 "SUSPENSION_REQUEST_SNA" 2 "SUSPENSION_REQUEST_LOWER" 1 "SUSPENSION_REQUEST_RAISE" 0 "SUSPENSION_REQUEST_NONE" ;
VAL_ 964 PCS_infoIndex 255 "END" 31 "SUBCOMPONENT_GITHASH" 30 "PACKAGE_SN_8_14" 29 "PACKAGE_SN_1_7" 27 "PACKAGE_PN_15_20" 26 "PACKAGE_PN_8_14" 25 "PACKAGE_PN_1_7" 23 "SUBCOMPONENT2" 22 "VARIANTCRC" 20 "UDS_PROTOCOL_BOOTCRC" 19 "VERSION_DEPRECATED" 18 "BOOTLOADER_GITHASH" 17 "APP_GITHASH" 16 "SUBCOMPONENT" 15 "BOOTLOADER_CRC" 14 "BOOTLOADER_SVN" 13 "APP_CRC" 11 "PCBAID_ASSYID_USAGEID" 10 "BUILD_HWID_COMPONENTID" 9 "DEPRECATED_9" 8 "DEPRECATED_8" 7 "DEPRECATED_7" 6 "DEPRECATED_6" 5 "DEPRECATED_5" 4 "DEPRECATED_4" 3 "DEPRECATED_3" 2 "DEPRECATED_2" 1 "DEPRECATED_1" 0 "DEPRECATED_0" ;
VAL_ 964 PCS_buildType 4 "INFO_MFG_BUILD" 3 "INFO_TRACEABLE_CI_BUILD" 2 "INFO_LOCAL_BUILD" 1 "INFO_PLATFORM_BUILD" 0 "INFO_UNKNOWN_BUILD" ;
VAL_ 676 PCS_chgPhATemp -1023 "SNA" ;
VAL_ 676 PCS_chgPhBTemp -1023 "SNA" ;
VAL_ 676 PCS_chgPhCTemp -1023 "SNA" ;
VAL_ 676 PCS_dcdcTemp -1023 "SNA" ;
VAL_ 676 PCS_ambientTemp -1023 "SNA" ;
VAL_ 676 PCS_dcdcBusbarTemp 511 "SNA" ;
VAL_ 790 PMF_infoIndex 255 "END" 21 "DI_BUILD_DATA" 20 "UDS_PROTOCOL_BOOTCRC" 19 "VERSION_DEPRECATED" 18 "BOOTLOADER_GITHASH" 17 "APP_GITHASH" 16 "SUBCOMPONENT" 15 "BOOTLOADER_CRC" 14 "BOOTLOADER_SVN" 13 "APP_CRC" 11 "PCBAID_ASSYID_USAGEID" 10 "BUILD_HWID_COMPONENTID" 9 "DEPRECATED_9" 8 "DEPRECATED_8" 7 "DEPRECATED_7" 6 "DEPRECATED_6" 5 "DEPRECATED_5" 4 "DEPRECATED_4" 3 "DEPRECATED_3" 2 "DEPRECATED_2" 1 "DEPRECATED_1" 0 "DEPRECATED_0" ;
VAL_ 790 PMF_buildType 4 "INFO_MFG_BUILD" 3 "INFO_TRACEABLE_CI_BUILD" 2 "INFO_LOCAL_BUILD" 1 "INFO_PLATFORM_BUILD" 0 "INFO_UNKNOWN_BUILD" ;
VAL_ 790 PMF_hardwareId 252 "CONFIGURABLE_HWID_PLACEHOLDER" ;
VAL_ 1748 PMR_infoIndex 255 "END" 21 "DI_BUILD_DATA" 20 "UDS_PROTOCOL_BOOTCRC" 19 "VERSION_DEPRECATED" 18 "BOOTLOADER_GITHASH" 17 "APP_GITHASH" 16 "SUBCOMPONENT" 15 "BOOTLOADER_CRC" 14 "BOOTLOADER_SVN" 13 "APP_CRC" 11 "PCBAID_ASSYID_USAGEID" 10 "BUILD_HWID_COMPONENTID" 9 "DEPRECATED_9" 8 "DEPRECATED_8" 7 "DEPRECATED_7" 6 "DEPRECATED_6" 5 "DEPRECATED_5" 4 "DEPRECATED_4" 3 "DEPRECATED_3" 2 "DEPRECATED_2" 1 "DEPRECATED_1" 0 "DEPRECATED_0" ;
VAL_ 1748 PMR_buildType 4 "INFO_MFG_BUILD" 3 "INFO_TRACEABLE_CI_BUILD" 2 "INFO_LOCAL_BUILD" 1 "INFO_PLATFORM_BUILD" 0 "INFO_UNKNOWN_BUILD" ;
VAL_ 1748 PMR_hardwareId 252 "CONFIGURABLE_HWID_PLACEHOLDER" ;
VAL_ 1551 PM_infoIndex 255 "END" 21 "DI_BUILD_DATA" 20 "UDS_PROTOCOL_BOOTCRC" 19 "VERSION_DEPRECATED" 18 "BOOTLOADER_GITHASH" 17 "APP_GITHASH" 16 "SUBCOMPONENT" 15 "BOOTLOADER_CRC" 14 "BOOTLOADER_SVN" 13 "APP_CRC" 11 "PCBAID_ASSYID_USAGEID" 10 "BUILD_HWID_COMPONENTID" 9 "DEPRECATED_9" 8 "DEPRECATED_8" 7 "DEPRECATED_7" 6 "DEPRECATED_6" 5 "DEPRECATED_5" 4 "DEPRECATED_4" 3 "DEPRECATED_3" 2 "DEPRECATED_2" 1 "DEPRECATED_1" 0 "DEPRECATED_0" ;
VAL_ 1551 PM_buildType 4 "INFO_MFG_BUILD" 3 "INFO_TRACEABLE_CI_BUILD" 2 "INFO_LOCAL_BUILD" 1 "INFO_PLATFORM_BUILD" 0 "INFO_UNKNOWN_BUILD" ;
VAL_ 1551 PM_hardwareId 252 "CONFIGURABLE_HWID_PLACEHOLDER" ;
VAL_ 837 PTC_infoIndex 255 "END" 31 "SUBCOMPONENT_GITHASH" 30 "PACKAGE_SN_8_14" 29 "PACKAGE_SN_1_7" 27 "PACKAGE_PN_15_20" 26 "PACKAGE_PN_8_14" 25 "PACKAGE_PN_1_7" 23 "SUBCOMPONENT2" 22 "VARIANTCRC" 20 "UDS_PROTOCOL_BOOTCRC" 19 "VERSION_DEPRECATED" 18 "BOOTLOADER_GITHASH" 17 "APP_GITHASH" 16 "SUBCOMPONENT" 15 "BOOTLOADER_CRC" 14 "BOOTLOADER_SVN" 13 "APP_CRC" 11 "PCBAID_ASSYID_USAGEID" 10 "BUILD_HWID_COMPONENTID" 9 "DEPRECATED_9" 8 "DEPRECATED_8" 7 "DEPRECATED_7" 6 "DEPRECATED_6" 5 "DEPRECATED_5" 4 "DEPRECATED_4" 3 "DEPRECATED_3" 2 "DEPRECATED_2" 1 "DEPRECATED_1" 0 "DEPRECATED_0" ;
VAL_ 837 PTC_infoBuildType 4 "INFO_MFG_BUILD" 3 "INFO_TRACEABLE_CI_BUILD" 2 "INFO_LOCAL_BUILD" 1 "INFO_PLATFORM_BUILD" 0 "INFO_UNKNOWN_BUILD" ;
VAL_ 837 PTC_infoAssemblyId 255 "ASSEMBLY_SNA" 1 "ASSEMBLY1" ;
VAL_ 1359 SCCM_matrixIndex 2 "AlertMatrix2" 1 "AlertMatrix1" 0 "AlertMatrix0" ;
VAL_ 816 SCCM_infoIndex 255 "END" 20 "UDS_PROTOCOL_BOOTCRC" 18 "BOOTLOADER_SVNHASH" 17 "APP_SVNHASH" 16 "SUBCOMPONENT1" 14 "BOOTLOADER_SVN" 13 "APP_CRC" 11 "PCBAID_ASSYID_USAGEID" 10 "BUILD_HWID_COMPONENTID" ;
VAL_ 816 SCCM_infoBuildType 4 "INFO_MFG_BUILD" 3 "INFO_TRACEABLE_CI_BUILD" 2 "INFO_LOCAL_BUILD" 1 "INFO_PLATFORM_BUILD" 0 "INFO_UNKNOWN_BUILD" ;
VAL_ 585 SCCM_highBeamStalkStatus 3 "SNA" 2 "PUSH" 1 "PULL" 0 "IDLE" ;
VAL_ 585 SCCM_washWipeButtonStatus 3 "SNA" 2 "2ND_DETENT" 1 "1ST_DETENT" 0 "NOT_PRESSED" ;
VAL_ 585 SCCM_turnIndicatorStalkStatus 9 "SNA" 8 "DOWN_2" 7 "DOWN_1_5" 6 "DOWN_1" 5 "DOWN_0_5" 4 "UP_2" 3 "UP_1_5" 2 "UP_1" 1 "UP_0_5" 0 "IDLE" ;
VAL_ 585 SCCM_turnIndicatorStalkAngle 4095 "SNA" ;
VAL_ 553 SCCM_rightStalkStatus 6 "SNA" 5 "INIT" 4 "DOWN_2" 3 "DOWN_1" 2 "UP_2" 1 "UP_1" 0 "IDLE" ;
VAL_ 553 SCCM_parkButtonStatus 3 "SNA" 2 "INIT" 1 "PRESSED" 0 "NOT_PRESSED" ;
VAL_ 297 SCCM_steeringAngleSensorStatus 3 "ERROR_INIT" 2 "ERROR" 1 "INIT" 0 "OK" ;
VAL_ 297 SCCM_steeringAngle 16383 "SNA" ;
VAL_ 297 SCCM_steeringAngleValidity 3 "SNA" 2 "INIT" 1 "VALID" 0 "INVALID" ;
VAL_ 1356 SCM_alertID 91 "a091_voltageRiseDetection" 78 "a078_voltageMatchTimeout" 76 "a076_bmsMIA" 74 "a074_isoVDiffHi" 44 "a044_proximityRationality" 27 "a027_externalIsolationLow" 0 "ALERT_DO_NOT_USE_ZERO" ;
VAL_ 1356 SCM_alertType 1 "SET" 0 "CLEARED" ;
VAL_ 1354 SCS_alertID 128 "a128_unused128" 127 "a127_unused127" 126 "a126_unused126" 125 "a125_unused125" 124 "a124_unused124" 123 "a123_unused123" 122 "a122_unused122" 121 "a121_unused121" 120 "a120_unused120" 119 "a119_unused119" 118 "a118_unused118" 117 "a117_unused117" 116 "a116_unused116" 115 "a115_unused115" 114 "a114_unused114" 113 "a113_unused113" 112 "a112_unused112" 111 "a111_unused111" 110 "a110_unused110" 109 "a109_unused109" 108 "a108_unused108" 107 "a107_unused107" 106 "a106_unused106" 105 "a105_unused105" 104 "a104_unused104" 103 "a103_unused103" 102 "a102_unused102" 101 "a101_unused101" 100 "a100_unused100" 99 "a099_unused99" 98 "a098_unused98" 97 "a097_unused97" 96 "a096_unused96" 95 "a095_unused95" 94 "a094_unused94" 93 "a093_unused93" 92 "a092_cabEnableDeasserted" 91 "a091_voltageRiseDetection" 90 "a090_negCordOT" 89 "a089_posCordOT" 88 "a088_negCordTempRationality" 87 "a087_posCordTempRationality" 86 "a086_lccResetDetected" 85 "a085_unused85" 84 "a084_unused84" 83 "a083_chargeCurrentLimited" 82 "a082_VbatUV" 81 "a081_rmsInputVoltageHigh" 80 "a080_lccFaulted" 79 "a079_unexpectedVbat" 78 "a078_voltageMatchTimeout" 77 "a077_unexpectedVbatBehavior" 76 "a076_bmsMIA" 75 "a075_unused75" 74 "a074_isoVDiffHi" 73 "a073_lccMIA" 72 "a072_gtwMIA" 71 "a071_chargerMIA" 70 "a070_vStageRationalityV2" 69 "a069_vStageRationalityV1" 68 "a068_vBatRationalityStage4" 67 "a067_vBatRationalityStage3" 66 "a066_vBatRationalityStage2" 65 "a065_vBatRationalityStage1" 64 "a064_vehicleCommandTimeout" 63 "a063_canRationality" 62 "a062_unused" 61 "a061_postOutOfService" 60 "a060_swHVIL" 59 "a059_memoryError" 58 "a058_adcRef" 57 "a057_watchdogReset" 56 "a056_stateTransitionDenied" 55 "a055_coolantLevelLow" 54 "a054_pumpRegulation" 53 "a053_unexpectedThermalBehavi" 52 "a052_ambientTempRationality" 51 "a051_cordTempRationality" 50 "a050_coolantTempRationality" 49 "a049_pcbaTempRationality" 48 "a048_ambientOT" 47 "a047_cordOT" 46 "a046_coolantOT" 45 "a045_pcbaOT" 44 "a044_proximityRationality" 43 "a043_pilotRationality" 42 "a042_pilotOutOfRange" 41 "a041_minus12VOutOfRange" 40 "a040_plus12VOutOfRange" 39 "a039_ibatRegulation" 38 "a038_contactorFailedOpen" 37 "a037_outputContactorWelded" 36 "a036_internalContactorWelded" 35 "a035_unexpectedVbusBehavior" 34 "a034_IBatRationality" 33 "a033_VBusRationality" 32 "a032_VBatRationality" 31 "a031_IbatOC" 30 "a030_VbusOV" 29 "a029_VbatOV" 28 "a028_isolationRationality" 27 "a027_externalIsolationLow" 26 "a026_internalIsolationLow" 25 "a025_internalIsolationFault" 24 "a024_emergencyShutdown" 21 "a021_unusedHW21" 20 "a020_unusedHW20" 19 "a019_unusedHW19" 18 "a018_unusedHW18" 17 "a017_unusedHW17" 16 "a016_unusedHW16" 15 "a015_cpldRationality" 14 "a014_coolantTempHiFoldBk" 13 "a013_cordTempHiFoldBk" 12 "a012_hwIllegalCntrCmdV2" 11 "a011_hwIllegalCntrCmdV1" 10 "a010_hwOpen_V2" 9 "a009_hwOpen_V1" 8 "a008_hwIllegalCntrShoot" 7 "a007_hwWeld_V2" 6 "a006_hwWeld_V1" 5 "a005_hwHVIL" 4 "a004_hwVbusOV" 3 "a003_hwCordOT" 2 "a002_hwIbatOC" 1 "a001_hwDSPfault" 0 "ALERT_DO_NOT_USE_ZERO" ;
VAL_ 1354 SCS_alertType 1 "SET" 0 "CLEARED" ;
VAL_ 1467 SDCR_matrixIndex 0 "SDCR_AlertMatrix0" ;
VAL_ 1597 SDCR_infoIndex 255 "END" 41 "SUBCOMPONENT14" 40 "SUBCOMPONENT13" 39 "SUBCOMPONENT12" 38 "SUBCOMPONENT11" 37 "SUBCOMPONENT10" 36 "SUBCOMPONENT9" 35 "SUBCOMPONENT8" 34 "SUBCOMPONENT7" 33 "SUBCOMPONENT6" 32 "SUBCOMPONENT5" 31 "SUBCOMPONENT4" 24 "SUBCOMPONENT3" 23 "SUBCOMPONENT2" 20 "UDS_PROTOCOL_BOOTCRC" 19 "VERSION_DEPRECATED" 18 "BOOTLOADER_GITHASH" 17 "APP_GITHASH" 16 "SUBCOMPONENT1" 15 "BOOTLOADER_CRC" 14 "BOOTLOADER_SVN" 13 "APP_CRC" 11 "PCBAID_ASSYID_USAGEID" 10 "BUILD_HWID_COMPONENTID" 9 "DEPRECATED_9" 8 "DEPRECATED_8" 7 "DEPRECATED_7" 6 "DEPRECATED_6" 5 "DEPRECATED_5" 4 "DEPRECATED_4" 3 "DEPRECATED_3" 2 "DEPRECATED_2" 1 "DEPRECATED_1" 0 "DEPRECATED_0" ;
VAL_ 1597 SDCR_infoBuildType 4 "INFO_MFG_BUILD" 3 "INFO_TRACEABLE_CI_BUILD" 2 "INFO_LOCAL_BUILD" 1 "INFO_PLATFORM_BUILD" 0 "INFO_UNKNOWN_BUILD" ;
VAL_ 523 TAS_axleIndex 1 "axleRear" 0 "axleFront" ;
VAL_ 523 TAS_rawHeightFL 1023 "SNA" ;
VAL_ 523 TAS_staticHeightEstimateFL 1023 "SNA" ;
VAL_ 523 TAS_componentPressureFL 255 "SNA" ;
VAL_ 523 TAS_rawHeightFR 1023 "SNA" ;
VAL_ 523 TAS_staticHeightEstimateFR 1023 "SNA" ;
VAL_ 523 TAS_componentPressureFR 255 "SNA" ;
VAL_ 523 TAS_rawHeightRL 1023 "SNA" ;
VAL_ 523 TAS_staticHeightEstimateRL 1023 "SNA" ;
VAL_ 523 TAS_componentPressureRL 255 "SNA" ;
VAL_ 523 TAS_rawHeightRR 1023 "SNA" ;
VAL_ 523 TAS_staticHeightEstimateRR 1023 "SNA" ;
VAL_ 523 TAS_componentPressureRR 255 "SNA" ;
VAL_ 1398 TAS_endstopState 1 "TAS_DAMPING_STATE_ACTIVE" 0 "TAS_DAMPING_STATE_STANDBY" ;
VAL_ 1398 TAS_continuousControlState 1 "TAS_DAMPING_STATE_ACTIVE" 0 "TAS_DAMPING_STATE_STANDBY" ;
VAL_ 1398 TAS_activeTireTune 1 "TAS_TIRE_TUNE_MICHELIN_SUMMER_21" 0 "TAS_TIRE_TUNE_DEFAULT" ;
VAL_ 1398 TAS_roughnessRaiseReason 2 "TAS_ROUGHNESS_RAISE_REASON_LOOKAHEAD" 1 "TAS_ROUGHNESS_RAISE_REASON_LEGACY" 0 "TAS_ROUGHNESS_RAISE_REASON_NONE" ;
VAL_ 1398 TAS_frontMetricDrivesRear 3 "TAS_ACTION_ACTIVE" 2 "TAS_ACTION_ARMED" 1 "TAS_ACTION_STANDBY" 0 "TAS_ACTION_DISABLED" ;
VAL_ 1398 TAS_roadCondition 255 "SNA" ;
VAL_ 1398 TAS_bellyProtect 3 "TAS_ACTION_ACTIVE" 2 "TAS_ACTION_ARMED" 1 "TAS_ACTION_STANDBY" 0 "TAS_ACTION_DISABLED" ;
VAL_ 1398 TAS_frontMetricDrivesFront 3 "TAS_ACTION_ACTIVE" 2 "TAS_ACTION_ARMED" 1 "TAS_ACTION_STANDBY" 0 "TAS_ACTION_DISABLED" ;
VAL_ 1398 TAS_speedBumpAxleFront 4 "TAS_ACTION_CANCELED" 3 "TAS_ACTION_ACTIVE" 2 "TAS_ACTION_ARMED" 1 "TAS_ACTION_STANDBY" 0 "TAS_ACTION_DISABLED" ;
VAL_ 1398 TAS_speedBumpAxleRear 4 "TAS_ACTION_CANCELED" 3 "TAS_ACTION_ACTIVE" 2 "TAS_ACTION_ARMED" 1 "TAS_ACTION_STANDBY" 0 "TAS_ACTION_DISABLED" ;
VAL_ 1398 TAS_holeProtectFL 3 "TAS_ACTION_ACTIVE" 2 "TAS_ACTION_ARMED" 1 "TAS_ACTION_STANDBY" 0 "TAS_ACTION_DISABLED" ;
VAL_ 1398 TAS_holeProtectFR 3 "TAS_ACTION_ACTIVE" 2 "TAS_ACTION_ARMED" 1 "TAS_ACTION_STANDBY" 0 "TAS_ACTION_DISABLED" ;
VAL_ 1398 TAS_holeProtectRL 3 "TAS_ACTION_ACTIVE" 2 "TAS_ACTION_ARMED" 1 "TAS_ACTION_STANDBY" 0 "TAS_ACTION_DISABLED" ;
VAL_ 1398 TAS_holeProtectRR 3 "TAS_ACTION_ACTIVE" 2 "TAS_ACTION_ARMED" 1 "TAS_ACTION_STANDBY" 0 "TAS_ACTION_DISABLED" ;
VAL_ 1398 TAS_stepProtectFL 3 "TAS_ACTION_ACTIVE" 2 "TAS_ACTION_ARMED" 1 "TAS_ACTION_STANDBY" 0 "TAS_ACTION_DISABLED" ;
VAL_ 1398 TAS_stepProtectFR 3 "TAS_ACTION_ACTIVE" 2 "TAS_ACTION_ARMED" 1 "TAS_ACTION_STANDBY" 0 "TAS_ACTION_DISABLED" ;
VAL_ 1398 TAS_stepProtectRL 3 "TAS_ACTION_ACTIVE" 2 "TAS_ACTION_ARMED" 1 "TAS_ACTION_STANDBY" 0 "TAS_ACTION_DISABLED" ;
VAL_ 1398 TAS_stepProtectRR 3 "TAS_ACTION_ACTIVE" 2 "TAS_ACTION_ARMED" 1 "TAS_ACTION_STANDBY" 0 "TAS_ACTION_DISABLED" ;
VAL_ 1398 TAS_FDUTorqueCorruptionScale 15 "SNA" ;
VAL_ 1398 TAS_sprungMassEstimate 31 "SNA" ;
VAL_ 1357 TAS_infoIndex 255 "END" 41 "SUBCOMPONENT14" 40 "SUBCOMPONENT13" 39 "SUBCOMPONENT12" 38 "SUBCOMPONENT11" 37 "SUBCOMPONENT10" 36 "SUBCOMPONENT9" 35 "SUBCOMPONENT8" 34 "SUBCOMPONENT7" 33 "SUBCOMPONENT6" 32 "SUBCOMPONENT5" 31 "SUBCOMPONENT4" 24 "SUBCOMPONENT3" 23 "SUBCOMPONENT2" 20 "UDS_PROTOCOL_BOOTCRC" 19 "VERSION_DEPRECATED" 18 "BOOTLOADER_GITHASH" 17 "APP_GITHASH" 16 "SUBCOMPONENT1" 15 "BOOTLOADER_CRC" 14 "BOOTLOADER_SVN" 13 "APP_CRC" 11 "PCBAID_ASSYID_USAGEID" 10 "BUILD_HWID_COMPONENTID" 9 "DEPRECATED_9" 8 "DEPRECATED_8" 7 "DEPRECATED_7" 6 "DEPRECATED_6" 5 "DEPRECATED_5" 4 "DEPRECATED_4" 3 "DEPRECATED_3" 2 "DEPRECATED_2" 1 "DEPRECATED_1" 0 "DEPRECATED_0" ;
VAL_ 1357 TAS_infoBuildType 4 "INFO_MFG_BUILD" 3 "INFO_TRACEABLE_CI_BUILD" 2 "INFO_LOCAL_BUILD" 1 "INFO_PLATFORM_BUILD" 0 "INFO_UNKNOWN_BUILD" ;
VAL_ 1357 TAS_infoAssemblyId 255 "ASSEMBLY_SNA" 1 "ASSEMBLY1" ;
VAL_ 1357 TAS_infoMajorVersion 255 "SNA" 254 "LOCAL_BUILD" ;
VAL_ 1357 TAS_infoBranchOrigin 255 "SNA" 254 "LOCAL_BUILD" ;
VAL_ 1357 TAS_infoMaturity 255 "SNA" 254 "LOCAL_BUILD" ;
VAL_ 1357 TAS_infoHardwareRevision 255 "SNA" 254 "LOCAL_BUILD" ;
VAL_ 525 TAS_levelingState 15 "LEVELING_STATE_CROSSLINK" 14 "LEVELING_STATE_QUIET_EXHAUST" 13 "LEVELING_STATE_EXHAUST_RESERVOIR" 12 "LEVELING_STATE_LOWER_SPRING_WITH_COMPRESSOR" 11 "LEVELING_STATE_LOWER_SPRING" 10 "LEVELING_STATE_FILL_SPRING_RESERVOIR_FROM_COMPRESSOR" 9 "LEVELING_STATE_FILL_SPRING_FROM_RESERVOIR" 8 "LEVELING_STATE_FILL_SPRING_FROM_BOOST" 7 "LEVELING_STATE_FILL_SPRING_FROM_COMPRESSOR" 6 "LEVELING_STATE_FILL_RESERVOIR_FROM_COMPRESSOR" 5 "LEVELING_STATE_COMPRESSOR_PREFILL_GALLERY" 4 "LEVELING_STATE_COMPRESSOR_RAMPUP" 3 "LEVELING_STATE_EXHAUST_GALLERY" 2 "LEVELING_STATE_MEASURE_SPRING_PRESSURE" 1 "LEVELING_STATE_READ_P_RESERVOIR" 0 "LEVELING_STATE_IDLE" ;
VAL_ 525 TAS_levelingItem 7 "TAS_LEVELING_ITEM_ALL" 6 "TAS_LEVELING_ITEM_REAR_AXLE" 5 "TAS_LEVELING_ITEM_FRONT_AXLE" 4 "TAS_LEVELING_ITEM_RR" 3 "TAS_LEVELING_ITEM_RL" 2 "TAS_LEVELING_ITEM_FR" 1 "TAS_LEVELING_ITEM_FL" 0 "TAS_LEVELING_ITEM_NONE" ;
VAL_ 525 TAS_pressureGallery 255 "SNA" ;
VAL_ 525 TAS_pressureReservoir 255 "SNA" ;
VAL_ 525 TAS_runMode 7 "RUN_MODE_DYNO" 6 "RUN_MODE_LOW_POWER" 5 "RUN_MODE_NORMAL" 4 "RUN_MODE_DAN" 3 "RUN_MODE_ASSEMBLY" 2 "RUN_MODE_SERVICE" 1 "RUN_MODE_SYSTEM_CHECK" 0 "RUN_MODE_INIT" ;
VAL_ 525 TAS_filterMode 7 "MODE_STOPPING" 6 "MODE_DRIVE" 5 "MODE_LOADING" 4 "MODE_READY" 3 "MODE_TEST" 2 "MODE_CALIBRATE" 1 "MODE_INIT" 0 "MODE_NONE" ;
VAL_ 525 TAS_limpHomeMode 4 "LIMP_HOME_MODE_40" 3 "LIMP_HOME_MODE_30" 2 "LIMP_HOME_MODE_20" 1 "LIMP_HOME_MODE_10" 0 "LIMP_HOME_MODE_0" ;
VAL_ 525 TAS_targetLevel 4 "TAS_VERY_LOW" 3 "TAS_LOW" 2 "TAS_STANDARD" 1 "TAS_HIGH" 0 "TAS_VERY_HIGH" ;
VAL_ 525 TAS_currentLevel 4 "TAS_VERY_LOW" 3 "TAS_LOW" 2 "TAS_STANDARD" 1 "TAS_HIGH" 0 "TAS_VERY_HIGH" ;
VAL_ 409 TAS_adaptiveActivityFL_C 31 "SNA" ;
VAL_ 409 TAS_adaptiveActivityFL_R 31 "SNA" ;
VAL_ 409 TAS_adaptiveActivityFR_C 31 "SNA" ;
VAL_ 409 TAS_adaptiveActivityFR_R 31 "SNA" ;
VAL_ 409 TAS_adaptiveActivityRL_C 31 "SNA" ;
VAL_ 409 TAS_adaptiveActivityRL_R 31 "SNA" ;
VAL_ 409 TAS_adaptiveActivityRR_C 31 "SNA" ;
VAL_ 409 TAS_adaptiveActivityRR_R 31 "SNA" ;
VAL_ 409 TAS_uiHeightFL 63 "SNA" ;
VAL_ 409 TAS_uiHeightFR 63 "SNA" ;
VAL_ 409 TAS_uiHeightRL 63 "SNA" ;
VAL_ 409 TAS_uiHeightRR 63 "SNA" ;
VAL_ 410 TAS_bodyAccelFL 255 "SNA" ;
VAL_ 410 TAS_bodyAccelFR 255 "SNA" ;
VAL_ 410 TAS_bodyAccelRL 255 "SNA" ;
VAL_ 410 TAS_bodyAccelRR 255 "SNA" ;
VAL_ 538 TAS_adaptiveRideModeOverride 3 "TAS_ADAPTIVE_RIDE_MODE_SNA" 2 "TAS_ADAPTIVE_RIDE_MODE_SPORT" 1 "TAS_ADAPTIVE_RIDE_MODE_AUTO" 0 "TAS_ADAPTIVE_RIDE_MODE_COMFORT" ;
VAL_ 538 TAS_launchModeState 4 "TAS_LAUNCH_MODE_STATE_RAISE_SUSPENSION" 3 "TAS_LAUNCH_MODE_STATE_READY" 2 "TAS_LAUNCH_MODE_STATE_LOWER_SUSPENSION" 1 "TAS_LAUNCH_MODE_STATE_IDLE" 0 "TAS_LAUNCH_MODE_STATE_BLOCKED" ;
VAL_ 659 UI_steeringTuneRequest 2 "STEERING_TUNE_SPORT" 1 "STEERING_TUNE_STANDARD" 0 "STEERING_TUNE_COMFORT" ;
VAL_ 659 UI_tractionControlMode 7 "TC_SLIPPERY_SURFACE_SELECTED" 6 "TC_OFFROAD_ASSIST_SELECTED" 5 "TC_DYNO_MODE_SELECTED" 4 "TC_ROLLS_MODE_SELECTED" 3 "TC_DEV_MODE_2_SELECTED" 2 "TC_DEV_MODE_1_SELECTED" 1 "TC_SLIP_START_SELECTED" 0 "TC_NORMAL_SELECTED" ;
VAL_ 659 UI_parkBrakeRequest 3 "PARK_BRAKE_REQUEST_SNA" 1 "PARK_BRAKE_REQUEST_PRESSED" 0 "PARK_BRAKE_REQUEST_IDLE" ;
VAL_ 659 UI_winchModeRequest 3 "WINCH_MODE_DIALOGUE_OPEN" 2 "WINCH_MODE_EXIT" 1 "WINCH_MODE_ENTER" 0 "WINCH_MODE_IDLE" ;
VAL_ 659 UI_zeroSpeedConfirmed 3 "SNA" 2 "UNUSED" 1 "CONFIRMED" 0 "CANCELED" ;
VAL_ 659 UI_trailerMode 1 "TRAILER_MODE_ON" 0 "TRAILER_MODE_OFF" ;
VAL_ 659 UI_distanceUnits 1 "MILES" 0 "KM" ;
VAL_ 659 UI_accOvertakeEnable 3 "SNA" 1 "ACC_OVERTAKE_ON" 0 "ACC_OVERTAKE_OFF" ;
VAL_ 659 UI_aebEnable 3 "SNA" 1 "AEB_ON" 0 "AEB_OFF" ;
VAL_ 659 UI_aesEnable 3 "SNA" 1 "AES_ON" 0 "AES_OFF" ;
VAL_ 659 UI_ahlbEnable 3 "SNA" 1 "AHLB_ON" 0 "AHLB_OFF" ;
VAL_ 659 UI_autoLaneChangeEnable 3 "SNA" 1 "ON" 0 "OFF" ;
VAL_ 659 UI_autoParkRequest 15 "SNA" 12 "BEGIN_PARKING" 11 "RESUME" 10 "PAUSE" 9 "SEARCH" 8 "COMPLETE" 7 "ABORT" 6 "PARALLEL_PULL_OUT_TO_RIGHT" 5 "PARALLEL_PULL_OUT_TO_LEFT" 4 "PARK_RIGHT_CROSS" 3 "PARK_RIGHT_PARALLEL" 2 "PARK_LEFT_CROSS" 1 "PARK_LEFT_PARALLEL" 0 "NONE" ;
VAL_ 659 UI_bsdEnable 3 "SNA" 1 "BSD_ON" 0 "BSD_OFF" ;
VAL_ 659 UI_fcwEnable 3 "SNA" 1 "FCW_ON" 0 "FCW_OFF" ;
VAL_ 659 UI_fcwSensitivity 3 "SNA" 2 "AEB_SENSITIVITY_LATE" 1 "AEB_SENSITIVITY_AVERAGE" 0 "AEB_SENSITIVITY_EARLY" ;
VAL_ 659 UI_latControlEnable 3 "LATERAL_CONTROL_SNA" 2 "LATERAL_CONTROL_UNAVAILABLE" 1 "LATERAL_CONTROL_ON" 0 "LATERAL_CONTROL_OFF" ;
VAL_ 659 UI_ldwEnable 3 "SNA" 1 "LDW_TRIGGERS_HAPTIC" 0 "NO_HAPTIC" ;
VAL_ 659 UI_pedalSafetyEnable 3 "SNA" 1 "PEDAL_SAFETY_ON" 0 "PEDAL_SAFETY_OFF" ;
VAL_ 659 UI_pedalMap_epas 2 "PERFORMANCE" 1 "SPORT" 0 "CHILL" ;
VAL_ 659 UI_redLightStopSignEnable 3 "SNA" 1 "RLSSW_ON" 0 "RLSSW_OFF" ;
VAL_ 659 UI_selfParkTune 15 "SNA" ;
VAL_ 1280 UI_debugEcuTarget 21 "PMRE2" 20 "PMRE2L" 19 "PMRE1L" 18 "DIRE2" 17 "DIRE1R" 16 "DIRE1L" 15 "PMRER" 14 "PMREL" 13 "DIRER" 12 "DIREL" 11 "PMR" 10 "PMF" 9 "DIR" 8 "DIF" 7 "VCFRONT" 6 "VCRIGHT" 5 "BMS" 4 "PMS" 3 "PM" 2 "DIS" 1 "DI" ;
VAL_ 2043 UI_debugDampingRequestFLC 255 "SNA" ;
VAL_ 2043 UI_debugDampingRequestFLR 255 "SNA" ;
VAL_ 2043 UI_debugDampingRequestFRC 255 "SNA" ;
VAL_ 2043 UI_debugDampingRequestFRR 255 "SNA" ;
VAL_ 2043 UI_debugDampingRequestRLC 255 "SNA" ;
VAL_ 2043 UI_debugDampingRequestRLR 255 "SNA" ;
VAL_ 2043 UI_debugDampingRequestRRC 255 "SNA" ;
VAL_ 2043 UI_debugDampingRequestRRR 255 "SNA" ;
VAL_ 568 UI_mapSpeedLimitDependency 7 "SNA" 6 "LANE" 5 "SEASON" 4 "TIME" 3 "SNOW" 2 "RAIN" 1 "SCHOOL" 0 "NONE" ;
VAL_ 568 UI_roadClass 6 "CLASS_6_MINOR" 5 "CLASS_5" 4 "CLASS_4" 3 "CLASS_3" 2 "CLASS_2" 1 "CLASS_1_MAJOR" 0 "UNKNOWN_INVALID_SNA" ;
VAL_ 568 UI_mapSpeedUnits 1 "KPH" 0 "MPH" ;
VAL_ 568 UI_mapSpeedLimit 31 "SNA" 30 "UNLIMITED" 29 "LESS_OR_EQ_160" 28 "LESS_OR_EQ_150" 27 "LESS_OR_EQ_140" 26 "LESS_OR_EQ_130" 25 "LESS_OR_EQ_120" 24 "LESS_OR_EQ_115" 23 "LESS_OR_EQ_110" 22 "LESS_OR_EQ_105" 21 "LESS_OR_EQ_100" 20 "LESS_OR_EQ_95" 19 "LESS_OR_EQ_90" 18 "LESS_OR_EQ_85" 17 "LESS_OR_EQ_80" 16 "LESS_OR_EQ_75" 15 "LESS_OR_EQ_70" 14 "LESS_OR_EQ_65" 13 "LESS_OR_EQ_60" 12 "LESS_OR_EQ_55" 11 "LESS_OR_EQ_50" 10 "LESS_OR_EQ_45" 9 "LESS_OR_EQ_40" 8 "LESS_OR_EQ_35" 7 "LESS_OR_EQ_30" 6 "LESS_OR_EQ_25" 5 "LESS_OR_EQ_20" 4 "LESS_OR_EQ_15" 3 "LESS_OR_EQ_10" 2 "LESS_OR_EQ_7" 1 "LESS_OR_EQ_5" 0 "UNKNOWN" ;
VAL_ 568 UI_mapSpeedLimitType 7 "UNKNOWN_SNA" 4 "BUMPS" 3 "DEPENDENT" 2 "ADVISORY" 1 "REGULAR" ;
VAL_ 568 UI_countryCode 1023 "SNA" 0 "UNKNOWN" ;
VAL_ 568 UI_nextBranchDist 31 "SNA" ;
VAL_ 651 UI_driverProfileLinkedKeySHA1 4294967295 "SNA" ;
VAL_ 651 UI_driverProfileSelectionType 3 "DRIVER_PROFILE_SELECTION_TYPE_NONE" 2 "DRIVER_PROFILE_SELECTION_TYPE_AUTOMATIC_NO_OP" 1 "DRIVER_PROFILE_SELECTION_TYPE_AUTOMATIC_RESTORE" 0 "DRIVER_PROFILE_SELECTION_TYPE_MANUAL" ;
VAL_ 984 UI_elevation 8191 "SNA" ;
VAL_ 984 UI_navElevation 8191 "SNA" ;
VAL_ 883 UI_mapSpeedLimitUnits 1 "KPH" 0 "MPH" ;
VAL_ 883 UI_userSpeedOffsetUnits 1 "KPH" 0 "MPH" ;
VAL_ 883 UI_conditionalSpeedLimit 31 "SNA" ;
